VERSION ""

NS_ :

BS_:

BU_: BCM BMS_12V CMS_D CMS_P DSMU ECDO METER MID PBD PSB_D PSB_P PSCU RSCU2R RSCU3R SCCM SRVM VSP

BO_ 32 ACU_A102: 8 BCM
  SG_ AirbagCrashOrder_v3 : 5|6@0+ (1,0) [0|0] "" BMS_12V,DSMU,PSCU,SCCM
  SG_ PreRolloverDetection : 16|1@0+ (1,0) [0|0] "" PSB_D,PSB_P
  SG_ RolloverDetection : 57|1@0+ (1,0) [0|0] "" PSB_D,PSB_P

BO_ 114 EBA_A101: 7 BCM
  SG_ BrakePedalPosition : 23|12@0+ (0.03125,0) [0|100] "%" PSB_D,PSB_P

BO_ 115 ECM_A109: 6 BCM
  SG_ EngineRPMDisplay : 31|16@0+ (0.125,0) [0|8191.75] "rpm" METER

BO_ 116 ECM_A110: 8 BCM
  SG_ StopAutoPhase : 47|3@0+ (1,0) [0|0] "" SCCM

BO_ 117 ECM_A112: 8 BCM
  SG_ CRC_ECM_A112 : 7|8@0+ (1,0) [0|255] "" METER
  SG_ Clock_ECM_A112 : 15|4@0+ (1,0) [0|15] "" METER
  SG_ PowerTrainStatus : 25|2@0+ (1,0) [0|0] "" METER,VSP
  SG_ EngineStopRequestOrigin : 28|3@0+ (1,0) [0|0] "" METER
  SG_ EngineRPM : 39|16@0+ (0.125,0) [0|8191.75] "rpm" VSP

BO_ 159 ADAS_A4: 5 BCM
  SG_ AEB_BrakeWheelTorqueOrder2 : 11|3@0+ (1,0) [0|0] "" PSB_D,PSB_P

BO_ 168 STRG_A1: 7 BCM
  SG_ SteeringWheelAngleRaw : 22|15@0+ (0.1,-1080) [-1080|1080] "°" METER,PSB_D,PSB_P
  SG_ SwaSensorInternalStatus : 39|3@0+ (1,0) [0|0] "" DSMU,METER,PSB_D,PSB_P
  SG_ SteeringWheelRotationSpeed : 47|16@0+ (0.1,-3276.7) [-3276.7|3276.7] "°/s" DSMU,PSB_D,PSB_P

BO_ 171 VDC_A6: 8 BCM
  SG_ YawRateCorrected : 10|11@0+ (0.1,-100) [-100|100] "°/s" DSMU
  SG_ BrakingPressure : 31|8@0+ (0.5,0) [0|126] "bar" PSB_D,PSB_P
  SG_ SteerRackPinionAngleCorrect : 39|15@0+ (0.1,-1080) [-1080|1080] "°" METER,PSB_D,PSB_P

BO_ 180 VDC_A5: 8 BCM
  SG_ LongitudinalAccelCorrected : 23|12@0+ (0.001,-2) [-2|2] "G" METER
  SG_ TransversalAccelCorrected : 47|12@0+ (0.001,-2) [-2|2] "G" METER

BO_ 303 ATCU_A108: 7 BCM
  SG_ GearLeverPosition_v2 : 20|4@0+ (1,0) [0|0] "" DSMU,PBD,RSCU2R,SCCM,VSP

BO_ 514 VDC_A4: 8 BCM
  SG_ ABSinRegulation : 0|1@0+ (1,0) [0|0] "" PSB_D,PSB_P
  SG_ ESCMalfunction : 33|1@0+ (1,0) [0|0] "" METER
  SG_ ABSMalfunction : 47|1@0+ (1,0) [0|0] "" METER

BO_ 534 EPS_A101: 4 BCM
  SG_ CRC_EPS_A101 : 7|8@0+ (1,0) [0|255] "" METER
  SG_ Clock_EPS_A101 : 15|4@0+ (1,0) [0|15] "" METER
  SG_ EPSWarning : 19|2@0+ (1,0) [0|0] "" METER

BO_ 549 VDC_A115: 3 BCM
  SG_ StopLampFlashingRequest : 21|1@0+ (1,0) [0|0] "" DSMU

BO_ 559 FrCamADAS_R109: 7 BCM
  SG_ ADAS_SwitchTransitionDisplay : 42|3@0+ (1,0) [0|0] "" METER

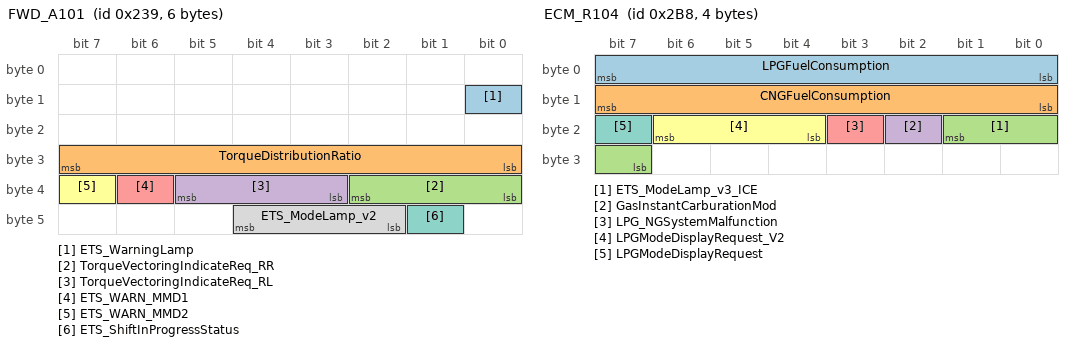
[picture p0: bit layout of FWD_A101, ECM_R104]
BO_ 569 FWD_A101: 6 BCM
  SG_ ETS_WarningLamp : 8|1@0+ (1,0) [0|0] "" METER
  SG_ TorqueDistributionRatio : 31|8@0+ (0.5,0) [0|100] "%" METER
  SG_ TorqueVectoringIndicateReq_RR : 34|3@0+ (1,0) [0|0] "" METER
  SG_ TorqueVectoringIndicateReq_RL : 37|3@0+ (1,0) [0|0] "" METER
  SG_ ETS_WARN_MMD1 : 38|1@0+ (1,0) [0|0] "" METER
  SG_ ETS_WARN_MMD2 : 39|1@0+ (1,0) [0|0] "" METER
  SG_ ETS_ShiftInProgressStatus : 41|1@0+ (1,0) [0|0] "" METER
  SG_ ETS_ModeLamp_v2 : 44|3@0+ (1,0) [0|0] "" METER

BO_ 578 FrCamADAS_R113: 2 BCM
  SG_ V2XDistanceToEvent : 7|11@0+ (1,0) [0|1500] "m" METER

BO_ 604 EPKB_A1: 4 BCM
  SG_ ParkingBrakeBindingStatus : 9|2@0+ (1,0) [0|0] "" METER

BO_ 650 VDC_A9: 8 BCM
  SG_ VehicleSpeed : 39|16@0+ (0.01,0) [0|655.34] "km/h" DSMU,METER,MID,PBD,PSB_D,PSB_P,PSCU,RSCU2R,RSCU3R,SCCM,VSP
  SG_ VehicleSpeedClock : 51|4@0+ (1,0) [0|15] "" DSMU,METER,PBD
  SG_ VDC_StandStillSupposed : 53|2@0+ (1,0) [0|0] "" METER
  SG_ VehicleSpeedCRC : 63|8@0+ (1,0) [0|255] "" DSMU,METER,PBD

BO_ 696 ECM_R104: 4 BCM
  SG_ LPGFuelConsumption : 7|8@0+ (0.000020,0) [0|0.00508] "L" METER
  SG_ CNGFuelConsumption : 15|8@0+ (0.000010,0) [0|0.00254] "kg" METER
  SG_ ETS_ModeLamp_v3_ICE : 17|3@0+ (1,0) [0|0] "" METER
  SG_ GasInstantCarburationMod : 18|1@0+ (1,0) [0|0] "" METER
  SG_ LPG_NGSystemMalfunction : 19|1@0+ (1,0) [0|0] "" METER
  SG_ LPGModeDisplayRequest_V2 : 22|3@0+ (1,0) [0|0] "" METER
  SG_ LPGModeDisplayRequest : 23|1@0+ (1,0) [0|0] "" METER

BO_ 699 VDC_R102: 5 BCM
  SG_ VaccumPumpDurabilityLimitAlert : 18|2@0+ (1,0) [0|0] "" METER

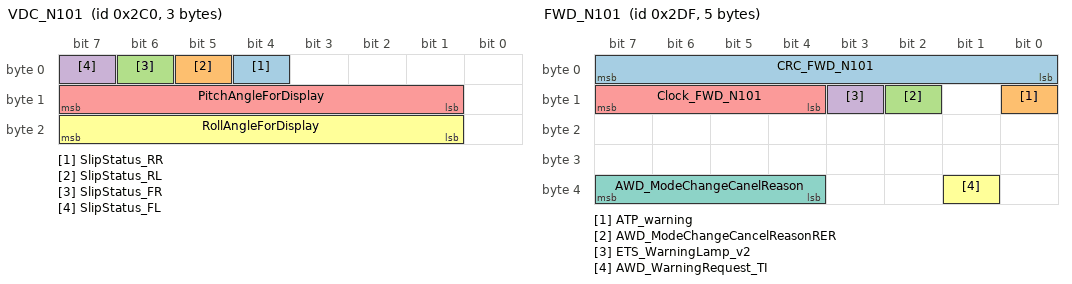
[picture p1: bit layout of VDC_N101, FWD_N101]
BO_ 704 VDC_N101: 3 BCM
  SG_ SlipStatus_RR : 4|1@0+ (1,0) [0|0] "" METER
  SG_ SlipStatus_RL : 5|1@0+ (1,0) [0|0] "" METER
  SG_ SlipStatus_FR : 6|1@0+ (1,0) [0|0] "" METER
  SG_ SlipStatus_FL : 7|1@0+ (1,0) [0|0] "" METER
  SG_ PitchAngleForDisplay : 15|7@0+ (1,-60) [-60|60] "°" METER
  SG_ RollAngleForDisplay : 23|7@0+ (1,-60) [-60|60] "°" METER

BO_ 735 FWD_N101: 5 BCM
  SG_ CRC_FWD_N101 : 7|8@0+ (1,0) [0|255] "" METER
  SG_ ATP_warning : 8|1@0+ (1,0) [0|0] "" METER
  SG_ AWD_ModeChangeCancelReasonRER : 10|1@0+ (1,0) [0|0] "" METER
  SG_ ETS_WarningLamp_v2 : 11|1@0+ (1,0) [0|0] "" METER
  SG_ Clock_FWD_N101 : 15|4@0+ (1,0) [0|15] "" METER
  SG_ AWD_WarningRequest_TI : 33|1@0+ (1,0) [0|0] "" METER
  SG_ AWD_ModeChangeCanelReason : 39|4@0+ (1,0) [0|0] "" METER

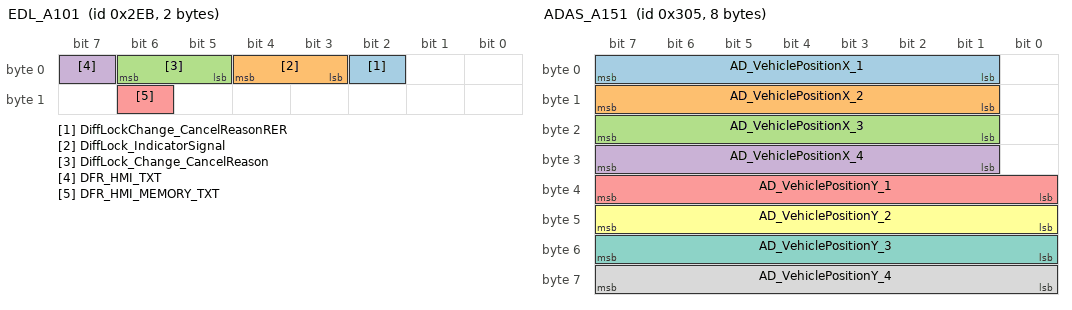
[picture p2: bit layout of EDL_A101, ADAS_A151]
BO_ 747 EDL_A101: 2 BCM
  SG_ DiffLockChange_CancelReasonRER : 2|1@0+ (1,0) [0|0] "" METER
  SG_ DiffLock_IndicatorSignal : 4|2@0+ (1,0) [0|0] "" METER
  SG_ DiffLock_Change_CancelReason : 6|2@0+ (1,0) [0|0] "" METER
  SG_ DFR_HMI_TXT : 7|1@0+ (1,0) [0|0] "" METER
  SG_ DFR_HMI_MEMORY_TXT : 14|1@0+ (1,0) [0|0] "" METER

BO_ 772 ADAS_A148: 4 BCM
  SG_ CRC_ADAS_A148 : 7|8@0+ (1,0) [0|255] "" METER
  SG_ Clock_ADAS_A148 : 15|4@0+ (1,0) [0|15] "" METER
  SG_ AD_OwnVehicle_ALCPosition : 23|7@0+ (1,0) [0|127] "" METER

BO_ 773 ADAS_A151: 8 BCM
  SG_ AD_VehiclePositionX_1 : 7|7@0+ (1,0) [0|127] "" METER
  SG_ AD_VehiclePositionX_2 : 15|7@0+ (1,0) [0|127] "" METER
  SG_ AD_VehiclePositionX_3 : 23|7@0+ (1,0) [0|127] "" METER
  SG_ AD_VehiclePositionX_4 : 31|7@0+ (1,0) [0|127] "" METER
  SG_ AD_VehiclePositionY_1 : 39|8@0+ (1,0) [0|255] "" METER
  SG_ AD_VehiclePositionY_2 : 47|8@0+ (1,0) [0|255] "" METER
  SG_ AD_VehiclePositionY_3 : 55|8@0+ (1,0) [0|255] "" METER
  SG_ AD_VehiclePositionY_4 : 63|8@0+ (1,0) [0|255] "" METER

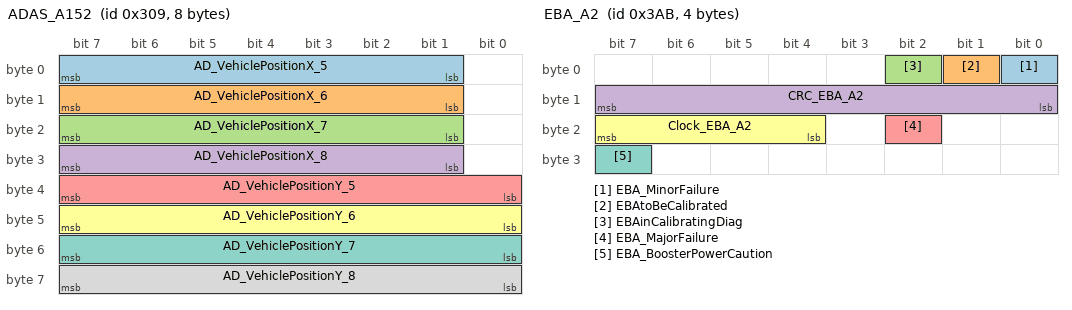
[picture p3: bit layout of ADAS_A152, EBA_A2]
BO_ 777 ADAS_A152: 8 BCM
  SG_ AD_VehiclePositionX_5 : 7|7@0+ (1,0) [0|127] "" METER
  SG_ AD_VehiclePositionX_6 : 15|7@0+ (1,0) [0|127] "" METER
  SG_ AD_VehiclePositionX_7 : 23|7@0+ (1,0) [0|127] "" METER
  SG_ AD_VehiclePositionX_8 : 31|7@0+ (1,0) [0|127] "" METER
  SG_ AD_VehiclePositionY_5 : 39|8@0+ (1,0) [0|255] "" METER
  SG_ AD_VehiclePositionY_6 : 47|8@0+ (1,0) [0|255] "" METER
  SG_ AD_VehiclePositionY_7 : 55|8@0+ (1,0) [0|255] "" METER
  SG_ AD_VehiclePositionY_8 : 63|8@0+ (1,0) [0|255] "" METER

BO_ 791 HVAC_A1: 8 BCM
  SG_ ISS_EcoActivationState : 43|2@0+ (1,0) [0|0] "" METER
  SG_ AirCondEcoActivationState : 45|2@0+ (1,0) [0|0] "" METER
  SG_ ClimECOModeStatusDisplay : 52|2@0+ (1,0) [0|0] "" METER

BO_ 879 METER_A4: 4 METER
  SG_ MemorizedDistanceTotalizer : 7|28@0+ (0.01,0) [0|2600000] "km" BCM

BO_ 893 EPS_A103: 3 BCM
  SG_ LDW_VibrationIntensityState : 2|2@0+ (1,0) [0|0] "" METER

BO_ 896 TCO1: 3 BCM
  SG_ DTCO_Driver1TimeRelatedStates : 11|4@0+ (1,0) [0|0] "" METER
  SG_ DTCO_OverSpeed : 15|2@0+ (1,0) [0|0] "" METER
  SG_ DTCO_Driver2TimeRelatedStates : 19|4@0+ (1,0) [0|0] "" METER

BO_ 930 ADAS_A123: 6 BCM
  SG_ DMC_UnresponsiveAlertStatus : 37|3@0+ (1,0) [0|0] "" METER

BO_ 934 AVM_A120: 3 BCM
  SG_ CRC_AVM_A120 : 7|8@0+ (1,0) [0|255] "" METER
  SG_ APA_StatusDisplay2 : 11|2@0+ (1,0) [0|0] "" METER
  SG_ Clock_AVM_A120 : 15|4@0+ (1,0) [0|15] "" METER

BO_ 939 EBA_A2: 4 BCM
  SG_ EBA_MinorFailure : 0|1@0+ (1,0) [0|0] "" METER
  SG_ EBAtoBeCalibrated : 1|1@0+ (1,0) [0|0] "" METER
  SG_ EBAinCalibratingDiag : 2|1@0+ (1,0) [0|0] "" METER
  SG_ CRC_EBA_A2 : 15|8@0+ (1,0) [0|255] "" METER
  SG_ EBA_MajorFailure : 18|1@0+ (1,0) [0|0] "" METER
  SG_ Clock_EBA_A2 : 23|4@0+ (1,0) [0|15] "" METER
  SG_ EBA_BoosterPowerCaution : 31|1@0+ (1,0) [0|0] "" METER

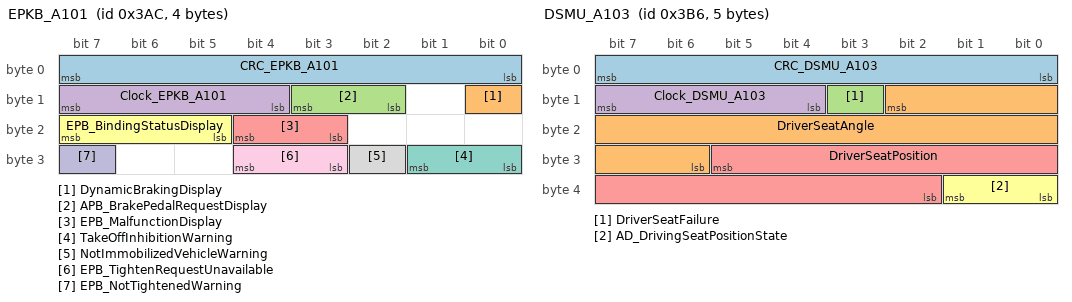
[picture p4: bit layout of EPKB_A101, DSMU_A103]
BO_ 940 EPKB_A101: 4 BCM
  SG_ CRC_EPKB_A101 : 7|8@0+ (1,0) [0|255] "" METER
  SG_ DynamicBrakingDisplay : 8|1@0+ (1,0) [0|0] "" METER
  SG_ APB_BrakePedalRequestDisplay : 11|2@0+ (1,0) [0|0] "" METER
  SG_ Clock_EPKB_A101 : 15|4@0+ (1,0) [0|15] "" METER
  SG_ EPB_MalfunctionDisplay : 20|2@0+ (1,0) [0|0] "" METER
  SG_ EPB_BindingStatusDisplay : 23|3@0+ (1,0) [0|0] "" METER
  SG_ TakeOffInhibitionWarning : 25|2@0+ (1,0) [0|0] "" METER
  SG_ NotImmobilizedVehicleWarning : 26|1@0+ (1,0) [0|0] "" METER
  SG_ EPB_TightenRequestUnavailable : 28|2@0+ (1,0) [0|0] "" METER
  SG_ EPB_NotTightenedWarning : 31|1@0+ (1,0) [0|0] "" METER

BO_ 941 BMS12V_A102: 2 BMS_12V
  SG_ CRC_BMS12V_A102 : 7|8@0+ (1,0) [0|255] "" BCM
  SG_ BMS12V_SafetyAlert : 11|2@0+ (1,0) [0|0] "" BCM,METER
  SG_ Clock_BMS12V_A102 : 15|4@0+ (1,0) [0|15] "" BCM

BO_ 943 FWD_M101: 3 BCM
  SG_ ETS_ModeLamp_v3 : 20|3@0+ (1,0) [0|0] "" METER

BO_ 950 DSMU_A103: 5 DSMU
  SG_ CRC_DSMU_A103 : 7|8@0+ (1,0) [0|255] "" BCM
  SG_ DriverSeatAngle : 10|13@0+ (1,-2244) [-2244|2244] "pulse" BCM
  SG_ DriverSeatFailure : 11|1@0+ (1,0) [0|0] "" BCM
  SG_ Clock_DSMU_A103 : 15|4@0+ (1,0) [0|15] "" BCM
  SG_ DriverSeatPosition : 29|12@0+ (1,-1260) [-1260|1260] "pulse" BCM
  SG_ AD_DrivingSeatPositionState : 33|2@0+ (1,0) [0|0] "" BCM

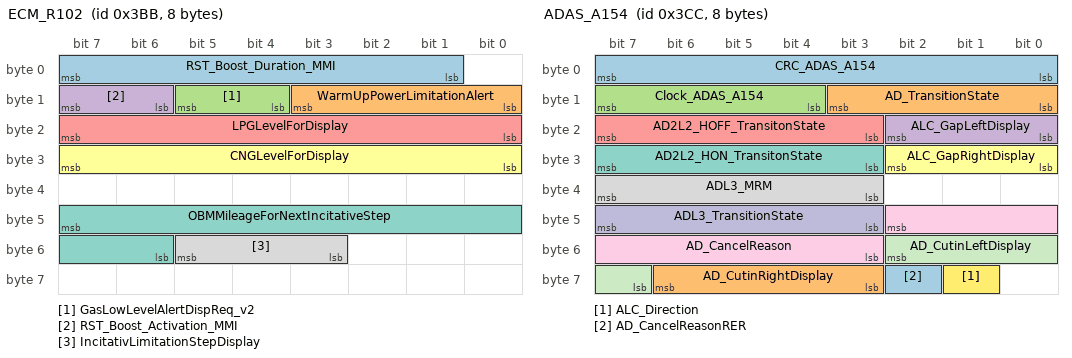
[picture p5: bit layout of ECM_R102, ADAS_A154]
BO_ 955 ECM_R102: 8 BCM
  SG_ RST_Boost_Duration_MMI : 7|7@0+ (1,0) [0|100] "%" METER
  SG_ WarmUpPowerLimitationAlert : 11|4@0+ (1,0) [0|0] "" METER
  SG_ GasLowLevelAlertDispReq_v2 : 13|2@0+ (1,0) [0|0] "" METER
  SG_ RST_Boost_Activation_MMI : 15|2@0+ (1,0) [0|0] "" METER
  SG_ LPGLevelForDisplay : 23|8@0+ (0.25,0) [0|63.5] "L" METER
  SG_ CNGLevelForDisplay : 31|8@0+ (0.2,0) [0|50.8] "kg" METER
  SG_ OBMMileageForNextIncitativeStep : 47|10@0+ (1,0) [0|1000] "Km" METER
  SG_ IncitativLimitationStepDisplay : 53|3@0+ (1,0) [0|0] "" METER

BO_ 959 HEVC_N101: 8 BCM
  SG_ IntelD_SettingStatus : 56|1@0+ (1,0) [0|0] "" METER
  SG_ IntelD_FailureDisplay : 58|2@0+ (1,0) [0|0] "" METER

BO_ 961 IVI_A112: 8 BCM
  SG_ DistanceBeforeNextAction : 7|40@0+ (1,0) [0|0] "" METER
  SG_ UnitDistanceBeforeNextAction : 47|4@0+ (1,0) [0|0] "" METER

BO_ 962 SONAR_A118: 4 BCM
  SG_ CRC_SONAR_A118 : 7|8@0+ (1,0) [0|255] "" METER
  SG_ APA_StatusDisplay : 11|2@0+ (1,0) [0|0] "" METER
  SG_ Clock_SONAR_A118 : 15|4@0+ (1,0) [0|15] "" METER

BO_ 967 IVI_A5: 8 BCM
  SG_ IVI_ParkAssistVolumeState : 63|3@0+ (1,0) [0|0] "" METER

BO_ 969 HEVC_M101: 1 BCM
  SG_ TorqueDistributionRatioDisplay : 7|8@0+ (0.5,0) [0|100] "%" METER

BO_ 970 BLM_A101: 1 BCM
  SG_ VirtualKeyState : 4|1@0+ (1,0) [0|0] "" METER

BO_ 971 ADAS_A150: 6 BCM
  SG_ AD_OwnVehicleEffect : 1|2@0+ (1,0) [0|0] "" METER
  SG_ AD_RightsideLane : 4|3@0+ (1,0) [0|0] "" METER
  SG_ AD_LeftsideLane : 7|3@0+ (1,0) [0|0] "" METER
  SG_ AD_VehicleEffect4 : 9|2@0+ (1,0) [0|0] "" METER
  SG_ AD_VehicleEffect3 : 11|2@0+ (1,0) [0|0] "" METER
  SG_ AD_VehicleEffect2 : 13|2@0+ (1,0) [0|0] "" METER
  SG_ AD_VehicleEffect1 : 15|2@0+ (1,0) [0|0] "" METER
  SG_ AD_VehicleEffect5 : 17|2@0+ (1,0) [0|0] "" METER
  SG_ AD_VehicleStatus2 : 20|3@0+ (1,0) [0|0] "" METER
  SG_ AD_VehicleStatus1 : 23|3@0+ (1,0) [0|0] "" METER
  SG_ AD_VehicleEffect6 : 25|2@0+ (1,0) [0|0] "" METER
  SG_ AD_VehicleStatus4 : 28|3@0+ (1,0) [0|0] "" METER
  SG_ AD_VehicleStatus3 : 31|3@0+ (1,0) [0|0] "" METER
  SG_ AD_VehicleEffect7 : 33|2@0+ (1,0) [0|0] "" METER
  SG_ AD_VehicleStatus6 : 36|3@0+ (1,0) [0|0] "" METER
  SG_ AD_VehicleStatus5 : 39|3@0+ (1,0) [0|0] "" METER
  SG_ AD_VehicleEffect8 : 41|2@0+ (1,0) [0|0] "" METER
  SG_ AD_VehicleStatus8 : 44|3@0+ (1,0) [0|0] "" METER
  SG_ AD_VehicleStatus7 : 47|3@0+ (1,0) [0|0] "" METER

BO_ 972 ADAS_A154: 8 BCM
  SG_ CRC_ADAS_A154 : 7|8@0+ (1,0) [0|255] "" METER
  SG_ AD_TransitionState : 11|4@0+ (1,0) [0|0] "" METER
  SG_ Clock_ADAS_A154 : 15|4@0+ (1,0) [0|15] "" METER
  SG_ ALC_GapLeftDisplay : 18|3@0+ (1,0) [0|0] "" METER
  SG_ AD2L2_HOFF_TransitonState : 23|5@0+ (1,0) [0|0] "" METER
  SG_ ALC_GapRightDisplay : 26|3@0+ (1,0) [0|0] "" METER
  SG_ AD2L2_HON_TransitonState : 31|5@0+ (1,0) [0|0] "" METER
  SG_ ADL3_MRM : 39|5@0+ (1,0) [0|0] "" METER
  SG_ AD_CancelReason : 42|8@0+ (1,0) [0|255] "CancelReason" METER
  SG_ ADL3_TransitionState : 47|5@0+ (1,0) [0|0] "" METER
  SG_ AD_CutinLeftDisplay : 50|4@0+ (1,0) [0|0] "" METER
  SG_ ALC_Direction : 57|1@0+ (1,0) [0|0] "" METER
  SG_ AD_CancelReasonRER : 58|1@0+ (1,0) [0|0] "" METER
  SG_ AD_CutinRightDisplay : 62|4@0+ (1,0) [0|0] "" METER

BO_ 974 ADAS_A147: 7 BCM
  SG_ CRC_ADAS_A147 : 7|8@0+ (1,0) [0|255] "" METER
  SG_ Clock_ADAS_A147 : 15|4@0+ (1,0) [0|15] "" METER
  SG_ ADADAS_ReflectiveFocus_Status : 23|36@0+ (1,0) [0|68719476734] "" METER

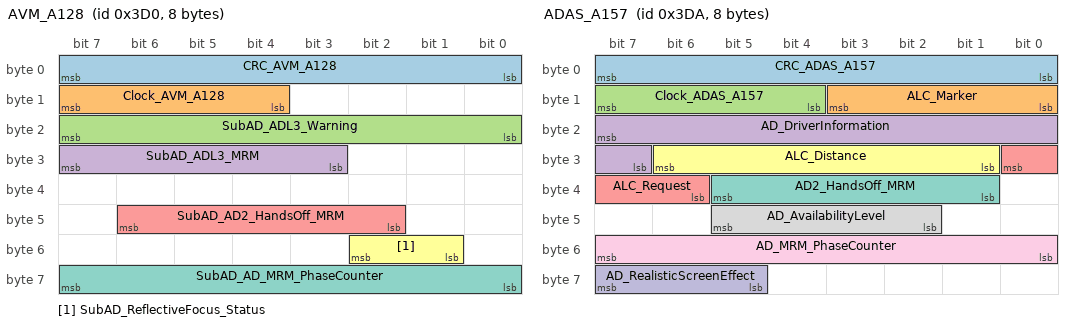
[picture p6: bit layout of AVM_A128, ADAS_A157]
BO_ 976 AVM_A128: 8 BCM
  SG_ CRC_AVM_A128 : 7|8@0+ (1,0) [0|255] "" METER
  SG_ Clock_AVM_A128 : 15|4@0+ (1,0) [0|15] "" METER
  SG_ SubAD_ADL3_Warning : 23|8@0+ (1,0) [0|255] "Warning" METER
  SG_ SubAD_ADL3_MRM : 31|5@0+ (1,0) [0|0] "" METER
  SG_ SubAD_AD2_HandsOff_MRM : 46|5@0+ (1,0) [0|0] "" METER
  SG_ SubAD_ReflectiveFocus_Status : 50|2@0+ (1,0) [0|0] "" METER
  SG_ SubAD_AD_MRM_PhaseCounter : 63|8@0+ (0.2,-0.2) [0|50.6] "s" METER

BO_ 977 CDM_A127: 3 BCM
  SG_ CRC_CDM_A127 : 7|8@0+ (1,0) [0|255] "" BMS_12V
  SG_ Clock_CDM_A127 : 15|4@0+ (1,0) [0|15] "" BMS_12V
  SG_ LiB_RLY_OFF_Inhibition : 23|1@0+ (1,0) [0|0] "" BMS_12V

BO_ 986 ADAS_A157: 8 BCM
  SG_ CRC_ADAS_A157 : 7|8@0+ (1,0) [0|255] "" METER
  SG_ ALC_Marker : 11|4@0+ (1,0) [0|0] "" METER
  SG_ Clock_ADAS_A157 : 15|4@0+ (1,0) [0|15] "" METER
  SG_ AD_DriverInformation : 23|9@0+ (1,0) [0|511] "Instruction" METER
  SG_ ALC_Request : 24|3@0+ (1,0) [0|0] "" METER
  SG_ ALC_Distance : 30|6@0+ (100,-100) [0|6000] "m" METER
  SG_ AD2_HandsOff_MRM : 37|5@0+ (1,0) [0|0] "" METER
  SG_ AD_AvailabilityLevel : 45|4@0+ (1,0) [0|0] "" METER
  SG_ AD_MRM_PhaseCounter : 55|8@0+ (0.2,-0.2) [0|50.6] "s" METER
  SG_ AD_RealisticScreenEffect : 63|3@0+ (1,0) [0|0] "" METER

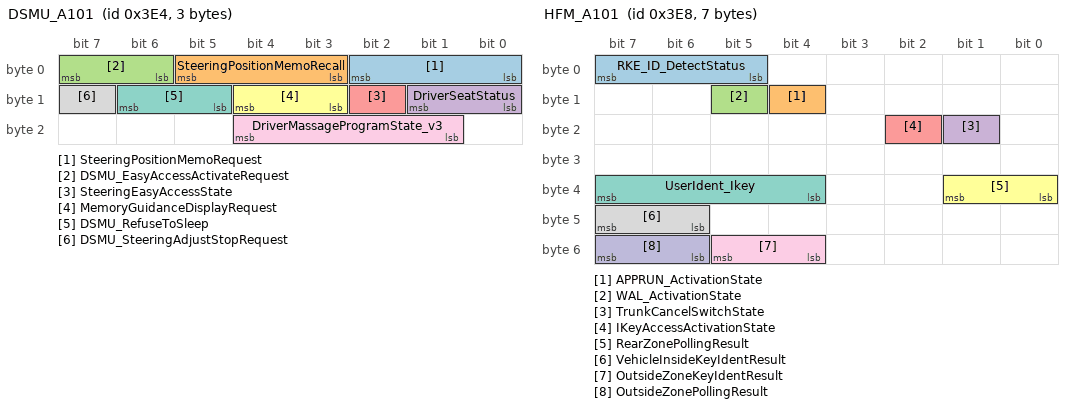
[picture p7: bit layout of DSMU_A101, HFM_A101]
BO_ 996 DSMU_A101: 3 DSMU
  SG_ SteeringPositionMemoRequest : 2|3@0+ (1,0) [0|0] "" SCCM
  SG_ SteeringPositionMemoRecall : 5|3@0+ (1,0) [0|0] "" SCCM
  SG_ DSMU_EasyAccessActivateRequest : 7|2@0+ (1,0) [0|0] "" SCCM
  SG_ DriverSeatStatus : 9|2@0+ (1,0) [0|0] "" BCM,SCCM
  SG_ SteeringEasyAccessState : 10|1@0+ (1,0) [0|0] "" METER
  SG_ MemoryGuidanceDisplayRequest : 12|2@0+ (1,0) [0|0] "" METER
  SG_ DSMU_RefuseToSleep : 14|2@0+ (1,0) [0|0] "" BCM
  SG_ DSMU_SteeringAdjustStopRequest : 15|1@0+ (1,0) [0|0] "" SCCM
  SG_ DriverMassageProgramState_v3 : 20|4@0+ (1,0) [0|0] "" BCM

BO_ 997 SCCM_A101: 1 SCCM
  SG_ SCCM_Status : 2|3@0+ (1,0) [0|0] "" DSMU
  SG_ SCCM_RefuseToSleep : 4|2@0+ (1,0) [0|0] "" BCM
  SG_ STR_AdjustStatus : 6|1@0+ (1,0) [0|0] "" DSMU

BO_ 999 BCM_A105: 4 BCM
  SG_ ADBCautionDisplay : 0|1@0+ (1,0) [0|0] "" METER
  SG_ V2_WakeUpType : 3|3@0+ (1,0) [0|0] "" BMS_12V
  SG_ BCM_LockAndCloseAuthentState : 5|2@0+ (1,0) [0|0] "" PBD
  SG_ V2_WakeUpSleepCommand : 7|2@0+ (1,0) [0|0] "" BMS_12V,DSMU,METER,MID,PBD,PSB_D,PSB_P,PSCU,RSCU2R,RSCU3R,SCCM
  SG_ BCM_SteeringCommandK : 8|1@0+ (1,0) [0|0] "" METER
  SG_ BCM_SteeringCommandJ : 9|1@0+ (1,0) [0|0] "" METER
  SG_ BCM_SteeringCommandI : 10|1@0+ (1,0) [0|0] "" METER
  SG_ BCM_SteeringCommandH : 11|1@0+ (1,0) [0|0] "" METER
  SG_ AHLCautionDisplay : 15|1@0+ (1,0) [0|0] "" METER
  SG_ BCM_SteeringCommandO : 16|1@0+ (1,0) [0|0] "" METER
  SG_ BCM_SteeringCommandN : 17|1@0+ (1,0) [0|0] "" METER
  SG_ BCM_SteeringCommandM : 18|1@0+ (1,0) [0|0] "" METER
  SG_ BCM_SteeringCommandL : 19|1@0+ (1,0) [0|0] "" METER
  SG_ BCM_SteeringPhoneEndCommand : 25|1@0+ (1,0) [0|0] "" METER
  SG_ LightSwitchOperationFdbk_display : 29|4@0+ (1,0) [0|0] "" METER
  SG_ BCM_SteeringCommandG : 30|1@0+ (1,0) [0|0] "" METER
  SG_ BCM_SteeringCommandP : 31|1@0+ (1,0) [0|0] "" METER

BO_ 1000 HFM_A101: 7 BCM
  SG_ RKE_ID_DetectStatus : 7|3@0+ (1,0) [0|0] "" DSMU
  SG_ APPRUN_ActivationState : 12|1@0+ (1,0) [0|0] "" METER
  SG_ WAL_ActivationState : 13|1@0+ (1,0) [0|0] "" METER
  SG_ TrunkCancelSwitchState : 17|1@0+ (1,0) [0|0] "" PBD
  SG_ IKeyAccessActivationState : 18|1@0+ (1,0) [0|0] "" METER
  SG_ RearZonePollingResult : 33|2@0+ (1,0) [0|0] "" PBD
  SG_ UserIdent_Ikey : 39|4@0+ (1,0) [0|0] "" PBD
  SG_ VehicleInsideKeyIdentResult : 47|2@0+ (1,0) [0|0] "" PBD
  SG_ OutsideZoneKeyIdentResult : 53|2@0+ (1,0) [0|0] "" PBD
  SG_ OutsideZonePollingResult : 55|2@0+ (1,0) [0|0] "" PBD

BO_ 1001 PSCU_A102: 1 PSCU
  SG_ PassengerMassageProgramState_v3 : 3|4@0+ (1,0) [0|0] "" BCM

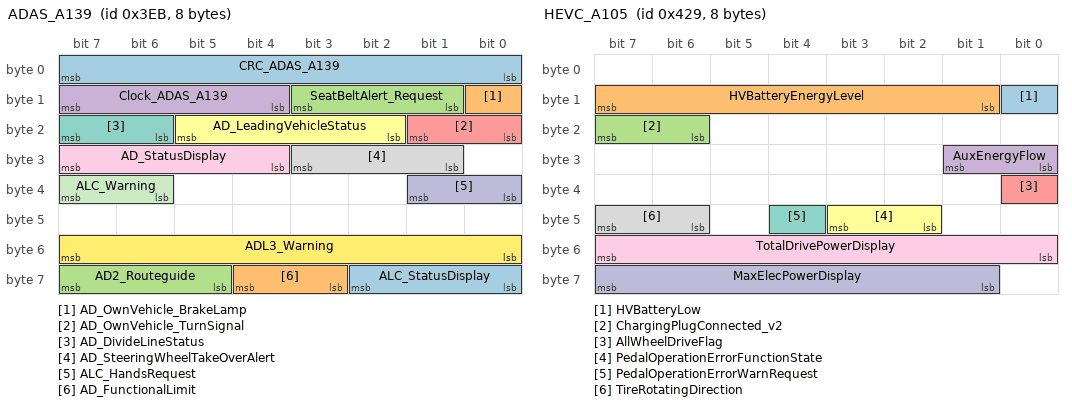
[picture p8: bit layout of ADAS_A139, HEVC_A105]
BO_ 1003 ADAS_A139: 8 BCM
  SG_ CRC_ADAS_A139 : 7|8@0+ (1,0) [0|255] "" METER,PSB_D
  SG_ AD_OwnVehicle_BrakeLamp : 8|1@0+ (1,0) [0|0] "" METER
  SG_ SeatBeltAlert_Request : 11|3@0+ (1,0) [0|0] "" PSB_D
  SG_ Clock_ADAS_A139 : 15|4@0+ (1,0) [0|15] "" METER,PSB_D
  SG_ AD_OwnVehicle_TurnSignal : 17|2@0+ (1,0) [0|0] "" METER
  SG_ AD_LeadingVehicleStatus : 21|4@0+ (1,0) [0|0] "" METER
  SG_ AD_DivideLineStatus : 23|2@0+ (1,0) [0|0] "" METER
  SG_ AD_SteeringWheelTakeOverAlert : 27|3@0+ (1,0) [0|0] "" METER
  SG_ AD_StatusDisplay : 31|4@0+ (1,0) [0|0] "" METER
  SG_ ALC_HandsRequest : 33|2@0+ (1,0) [0|0] "" METER
  SG_ ALC_Warning : 39|2@0+ (1,0) [0|0] "" METER
  SG_ ADL3_Warning : 55|8@0+ (1,0) [0|255] "Warning" METER
  SG_ ALC_StatusDisplay : 58|3@0+ (1,0) [0|0] "" METER
  SG_ AD_FunctionalLimit : 60|2@0+ (1,0) [0|0] "" METER
  SG_ AD2_Routeguide : 63|3@0+ (1,0) [0|0] "" METER

BO_ 1012 TCU_A101: 7 BCM
  SG_ ECALL_StateDisplay_V4 : 55|4@0+ (1,0) [0|0] "" METER

BO_ 1022 PSB_A101: 2 PSB_D
  SG_ CRC_PSB_A101 : 7|8@0+ (1,0) [0|255] "" BCM
  SG_ PSB_RefuseToSleep : 9|2@0+ (1,0) [0|0] "" BCM
  SG_ SeatBeltAlert_Status : 10|1@0+ (1,0) [0|0] "" BCM
  SG_ SeatBeltAlert_Failure : 11|1@0+ (1,0) [0|0] "" BCM
  SG_ Clock_PSB_A101 : 15|4@0+ (1,0) [0|15] "" BCM

BO_ 1028 VSP_A101: 1 VSP
  SG_ VSPSoundActivationState : 4|1@0+ (1,0) [0|0] "" BCM
  SG_ VSPsoundChoiceActivationState : 7|3@0+ (1,0) [0|0] "" BCM

BO_ 1045 IVI_A135: 8 BCM
  SG_ FaceID_temporary_Failure : 11|4@0+ (1,0) [0|0] "" METER
  SG_ FaceID_RegistrationState_IVI : 15|4@0+ (1,0) [0|0] "" METER
  SG_ FaceID_permanent_Failure : 20|2@0+ (1,0) [0|0] "" METER
  SG_ FaceID_RecognitionState_IVI : 23|3@0+ (1,0) [0|0] "" METER

BO_ 1047 AVM_A119: 3 BCM
  SG_ APA_Warning : 4|1@0+ (1,0) [0|0] "" METER

BO_ 1048 SONAR_A121: 1 BCM
  SG_ APA_Warning2 : 7|1@0+ (1,0) [0|0] "" METER

BO_ 1055 HEVC_R129: 8 BCM
  SG_ LowSOCTextRechargeAlertDisplay : 24|1@0+ (1,0) [0|0] "" METER
  SG_ RemainingTripForStartProhibit : 39|8@0+ (1,0) [0|255] "-" METER
  SG_ OBMMileageForNextIncitStep_V2 : 47|14@0+ (1,0) [0|10000] "Km" METER

BO_ 1058 FRCAMERA_A111: 5 BCM
  SG_ SpeedLimiterOSPDisplayRequest : 21|2@0+ (1,0) [0|0] "" METER
  SG_ TSR_ConfidenceLevel : 39|3@0+ (20,0) [0|100] "%" METER

BO_ 1064 HEVC_A104: 7 BCM
  SG_ MinElecPowerDisplay : 26|7@0+ (1,0) [0|100] "%" METER
  SG_ MaxElecPowerStatusDisplay : 33|2@0+ (1,0) [0|0] "" METER
  SG_ MinElecPowerStatusDisplay : 35|2@0+ (1,0) [0|0] "" METER

BO_ 1065 HEVC_A105: 8 BCM
  SG_ HVBatteryLow : 8|1@0+ (1,0) [0|0] "" METER
  SG_ HVBatteryEnergyLevel : 15|7@0+ (1,0) [0|100] "%" METER
  SG_ ChargingPlugConnected_v2 : 23|2@0+ (1,0) [0|0] "" METER
  SG_ AuxEnergyFlow : 25|2@0+ (1,0) [0|0] "" METER
  SG_ AllWheelDriveFlag : 32|1@0+ (1,0) [0|0] "" METER
  SG_ PedalOperationErrorFunctionState : 43|2@0+ (1,0) [0|0] "" METER
  SG_ PedalOperationErrorWarnRequest : 44|1@0+ (1,0) [0|0] "" METER
  SG_ TireRotatingDirection : 47|2@0+ (1,0) [0|0] "" METER
  SG_ TotalDrivePowerDisplay : 55|8@0+ (1,-100) [-100|120] "%" METER
  SG_ MaxElecPowerDisplay : 63|7@0+ (1,0) [0|100] "%" METER

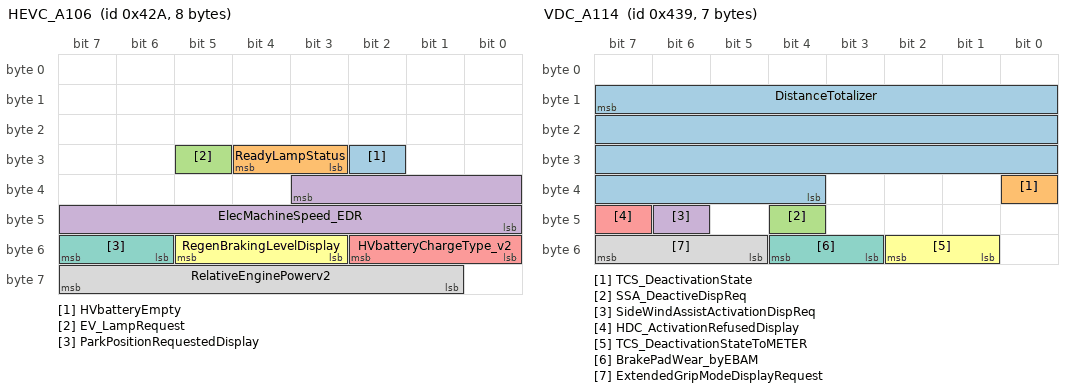
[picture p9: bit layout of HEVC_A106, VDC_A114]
BO_ 1066 HEVC_A106: 8 BCM
  SG_ HVbatteryEmpty : 26|1@0+ (1,0) [0|0] "" METER
  SG_ ReadyLampStatus : 28|2@0+ (1,0) [0|0] "" METER
  SG_ EV_LampRequest : 29|1@0+ (1,0) [0|0] "" METER
  SG_ ElecMachineSpeed_EDR : 35|12@0+ (10,-20000) [-20000|20000] "rpm" METER
  SG_ HVbatteryChargeType_v2 : 50|3@0+ (1,0) [0|0] "" METER
  SG_ RegenBrakingLevelDisplay : 53|3@0+ (1,0) [0|0] "" METER
  SG_ ParkPositionRequestedDisplay : 55|2@0+ (1,0) [0|0] "" METER
  SG_ RelativeEnginePowerv2 : 63|7@0+ (1,0) [0|100] "%" METER

BO_ 1067 HEVC_A107: 8 BCM
  SG_ RE_ElecMachineTemp_BLMS : 26|8@0+ (1,-40) [-40|210] "°C" METER
  SG_ RE_InverterTemp_BLMS : 34|8@0+ (1,-40) [-40|210] "°C" METER
  SG_ RE_ElecMachineSpeed_BLMS : 42|12@0+ (10,-20000) [-20000|20000] "rpm" METER
  SG_ HVbatteryTempForDisp : 62|7@0+ (1,-40) [-40|80] "°C" METER

BO_ 1068 HEVC_A108: 8 BCM
  SG_ HEV_ElecMotorFailureDisplay : 3|1@0+ (1,0) [0|0] "" METER
  SG_ HEV_ChargeFailureDisplay : 4|1@0+ (1,0) [0|0] "" METER
  SG_ HEV_MajorElecFailureDisplay : 5|1@0+ (1,0) [0|0] "" METER
  SG_ ChargingSoundRequest : 7|2@0+ (1,0) [0|0] "" VSP
  SG_ EngineMotorEnergyFlow_v2 : 10|3@0+ (1,0) [0|0] "" METER
  SG_ HVchargerStatus : 12|2@0+ (1,0) [0|0] "" DSMU,PSCU,RSCU2R,RSCU3R
  SG_ EngineWheelEnergyFlow_v2 : 18|3@0+ (1,0) [0|0] "" METER
  SG_ AuxChargePlugEnergyFlow : 20|2@0+ (1,0) [0|0] "" METER
  SG_ BatteryMotorEnergyFlow_v2 : 23|3@0+ (1,0) [0|0] "" METER
  SG_ HVBatInstantCurrentDisplay_v2 : 28|15@0+ (0.125,-1200) [-1200|1200] "A" METER
  SG_ BatteryRearMotorEnergyFlow : 31|3@0+ (1,0) [0|0] "" METER
  SG_ BatteryChargePlugEnergyFlow : 41|2@0+ (1,0) [0|0] "" METER
  SG_ ChargingStatusDisplay_v2 : 45|4@0+ (1,0) [0|0] "" METER
  SG_ ChargeRemainingTimeDisplay_v2 : 55|11@0+ (1,0) [0|2046] "min" METER
  SG_ HybridTractionChargeModeAvail : 56|1@0+ (1,0) [0|0] "" METER
  SG_ HybridTractionSaveModeAvail : 57|1@0+ (1,0) [0|0] "" METER
  SG_ HybridTractionModeCursorDisplay : 60|3@0+ (1,0) [0|0] "" METER

BO_ 1070 HEVC_R101: 7 BCM
  SG_ EcoNavStatusDisplay : 34|1@0+ (1,0) [0|0] "" METER
  SG_ ElecPowerDisplay : 55|8@0+ (1,-100) [-100|100] "%" METER

BO_ 1076 HFM_A104: 8 BCM
  SG_ CRC_HFM_A104 : 7|8@0+ (1,0) [0|255] "" METER
  SG_ BadgeBatteryLow : 8|1@0+ (1,0) [0|0] "" METER
  SG_ Clock_HFM_A104 : 15|4@0+ (1,0) [0|15] "" METER
  SG_ SteeringLockFailure : 47|2@0+ (1,0) [0|0] "" METER
  SG_ SwitchOffSESDisturbers : 50|1@0+ (1,0) [0|0] "" METER

BO_ 1081 VDC_A114: 7 BCM
  SG_ DistanceTotalizer : 15|28@0+ (0.01,0) [0|2600000] "km" BMS_12V,CMS_D,CMS_P,DSMU,METER,MID,PBD,PSB_D,PSB_P,PSCU,RSCU2R,RSCU3R,SCCM,VSP
  SG_ TCS_DeactivationState : 32|1@0+ (1,0) [0|0] "" METER
  SG_ SSA_DeactiveDispReq : 44|1@0+ (1,0) [0|0] "" METER
  SG_ SideWindAssistActivationDispReq : 46|1@0+ (1,0) [0|0] "" METER
  SG_ HDC_ActivationRefusedDisplay : 47|1@0+ (1,0) [0|0] "" METER
  SG_ TCS_DeactivationStateToMETER : 50|2@0+ (1,0) [0|0] "" METER
  SG_ BrakePadWear_byEBAM : 52|2@0+ (1,0) [0|0] "" METER
  SG_ ExtendedGripModeDisplayRequest : 55|3@0+ (1,0) [0|0] "" METER

BO_ 1082 HFM_A108: 7 BCM
  SG_ VPA_PBD_Request : 53|3@0+ (1,0) [0|0] "" PBD

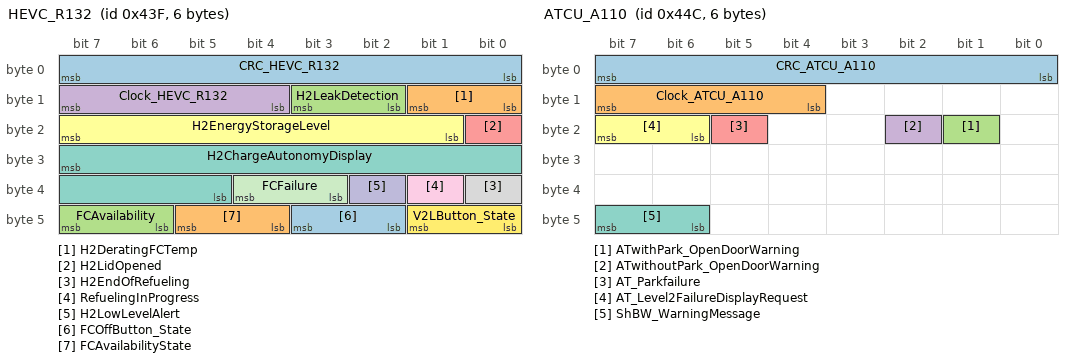
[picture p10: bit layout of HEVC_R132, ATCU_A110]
BO_ 1087 HEVC_R132: 6 BCM
  SG_ CRC_HEVC_R132 : 7|8@0+ (1,0) [0|255] "" METER
  SG_ H2DeratingFCTemp : 9|2@0+ (1,0) [0|0] "" METER
  SG_ H2LeakDetection : 11|2@0+ (1,0) [0|0] "" METER
  SG_ Clock_HEVC_R132 : 15|4@0+ (1,0) [0|15] "" METER
  SG_ H2LidOpened : 16|1@0+ (1,0) [0|0] "" METER
  SG_ H2EnergyStorageLevel : 23|7@0+ (1,0) [0|100] "%" METER
  SG_ H2ChargeAutonomyDisplay : 31|11@0+ (1,0) [0|2047] "KM" METER
  SG_ H2EndOfRefueling : 32|1@0+ (1,0) [0|0] "" METER
  SG_ RefuelingInProgress : 33|1@0+ (1,0) [0|0] "" METER
  SG_ H2LowLevelAlert : 34|1@0+ (1,0) [0|0] "" METER
  SG_ FCFailure : 36|2@0+ (1,0) [0|0] "" METER
  SG_ V2LButton_State : 41|2@0+ (1,0) [0|0] "" METER
  SG_ FCOffButton_State : 43|2@0+ (1,0) [0|0] "" METER
  SG_ FCAvailabilityState : 45|2@0+ (1,0) [0|0] "" METER
  SG_ FCAvailability : 47|2@0+ (1,0) [0|0] "" METER

BO_ 1099 ATCU_A109: 8 BCM
  SG_ AT_BrakeAvailability : 10|2@0+ (1,0) [0|0] "" METER
  SG_ RST_LaunchControlReadyMMI : 13|2@0+ (1,0) [0|0] "" METER
  SG_ AT_LoadAvailability : 17|2@0+ (1,0) [0|0] "" METER
  SG_ AT_DriverRequestWithoutBrake : 18|1@0+ (1,0) [0|0] "" METER
  SG_ AT_DriverRequest : 22|4@0+ (1,0) [0|0] "" METER
  SG_ AT_DriveAvailability_v2 : 23|1@0+ (1,0) [0|0] "" METER
  SG_ AT_PressBrakePedalRequest : 24|1@0+ (1,0) [0|0] "" METER
  SG_ AT_ParkAvailability : 26|2@0+ (1,0) [0|0] "" METER
  SG_ AT_NeutralAvailability : 28|2@0+ (1,0) [0|0] "" METER
  SG_ AT_ManualAvailability : 30|2@0+ (1,0) [0|0] "" METER
  SG_ AT_GearShiftRefused : 31|1@0+ (1,0) [0|0] "" METER
  SG_ ATCVT_CheckWarning : 32|1@0+ (1,0) [0|0] "" METER
  SG_ AT_TipDownAvailability : 34|2@0+ (1,0) [0|0] "" METER
  SG_ AT_ReverseAvailability : 39|2@0+ (1,0) [0|0] "" METER
  SG_ ATCVT_RangeIndicationExtended : 44|6@0+ (1,0) [0|0] "" METER
  SG_ ATCVT_HiTempWarning : 45|1@0+ (1,0) [0|0] "" METER
  SG_ AT_TipUpAvailability : 47|2@0+ (1,0) [0|0] "" METER
  SG_ AccelReqImpossible : 60|1@0+ (1,0) [0|0] "" METER
  SG_ NeutralHoldModeMessage : 63|3@0+ (1,0) [0|0] "" METER

BO_ 1100 ATCU_A110: 6 BCM
  SG_ CRC_ATCU_A110 : 7|8@0+ (1,0) [0|255] "" METER
  SG_ Clock_ATCU_A110 : 15|4@0+ (1,0) [0|15] "" METER
  SG_ ATwithPark_OpenDoorWarning : 17|1@0+ (1,0) [0|0] "" METER
  SG_ ATwithoutPark_OpenDoorWarning : 18|1@0+ (1,0) [0|0] "" METER
  SG_ AT_Parkfailure : 21|1@0+ (1,0) [0|0] "" METER
  SG_ AT_Level2FailureDisplayRequest : 23|2@0+ (1,0) [0|0] "" METER
  SG_ ShBW_WarningMessage : 47|2@0+ (1,0) [0|0] "" METER

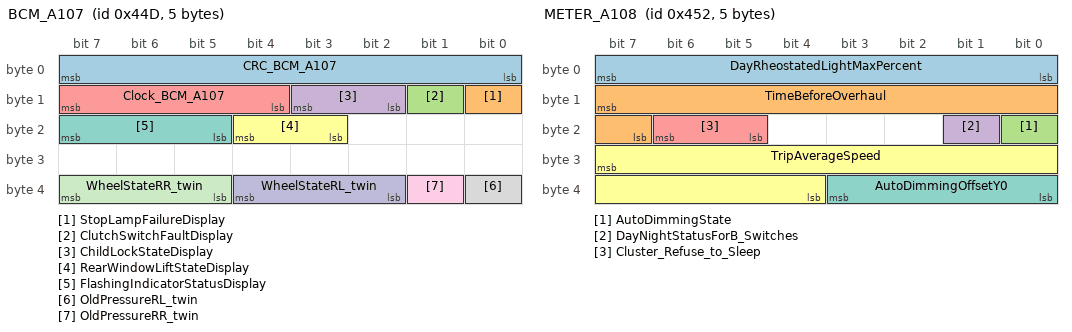
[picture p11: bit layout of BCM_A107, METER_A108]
BO_ 1101 BCM_A107: 5 BCM
  SG_ CRC_BCM_A107 : 7|8@0+ (1,0) [0|255] "" METER
  SG_ StopLampFailureDisplay : 8|1@0+ (1,0) [0|0] "" METER
  SG_ ClutchSwitchFaultDisplay : 9|1@0+ (1,0) [0|0] "" METER
  SG_ ChildLockStateDisplay : 11|2@0+ (1,0) [0|0] "" METER
  SG_ Clock_BCM_A107 : 15|4@0+ (1,0) [0|15] "" METER
  SG_ RearWindowLiftStateDisplay : 20|2@0+ (1,0) [0|0] "" METER
  SG_ FlashingIndicatorStatusDisplay : 23|3@0+ (1,0) [0|0] "" METER
  SG_ OldPressureRL_twin : 32|1@0+ (1,0) [0|0] "" METER
  SG_ OldPressureRR_twin : 33|1@0+ (1,0) [0|0] "" METER
  SG_ WheelStateRL_twin : 36|3@0+ (1,0) [0|0] "" METER
  SG_ WheelStateRR_twin : 39|3@0+ (1,0) [0|0] "" METER

BO_ 1102 BCM_A108: 6 BCM
  SG_ AutoLockActivationState : 1|2@0+ (1,0) [0|0] "" METER
  SG_ AutoLightSensitivityStatus : 3|2@0+ (1,0) [0|0] "" METER
  SG_ AutoFrontWiperActivationStatus : 5|2@0+ (1,0) [0|0] "" METER
  SG_ AHL_ActivationState : 7|2@0+ (1,0) [0|0] "" METER
  SG_ RearWiperStatus : 9|2@0+ (1,0) [0|0] "" METER
  SG_ MotorwayFlashersNumberStatus : 11|2@0+ (1,0) [0|0] "" METER
  SG_ AutoUnLockActivationState : 13|2@0+ (1,0) [0|0] "" METER
  SG_ AmbientLightingPatternState : 14|1@0+ (1,0) [0|0] "" METER
  SG_ AutoFMHactivationState : 15|1@0+ (1,0) [0|0] "" METER
  SG_ AutoInternalLightingState : 16|1@0+ (1,0) [0|0] "" METER
  SG_ AutoFMHdurationState : 19|3@0+ (1,0) [0|0] "" METER
  SG_ ADB_ActivationState : 20|1@0+ (1,0) [0|0] "" METER
  SG_ AutoReLockActivationState : 21|1@0+ (1,0) [0|0] "" METER
  SG_ FrontRearWiperDropStatus : 22|1@0+ (1,0) [0|0] "" METER
  SG_ WGSactivationState : 23|1@0+ (1,0) [0|0] "" METER
  SG_ LowBeamDisplay : 30|1@0+ (1,0) [0|0] "" METER
  SG_ HighBeamDisplay : 31|1@0+ (1,0) [0|0] "" METER
  SG_ AmbientLightingArea5Status : 35|1@0+ (1,0) [0|0] "" METER
  SG_ AmbientLightingArea4Status : 36|1@0+ (1,0) [0|0] "" METER
  SG_ SupportKeyJudgement : 47|2@0+ (1,0) [0|0] "" METER

BO_ 1103 BCM_A109: 8 BCM
  SG_ AHL_ActivationDisplay : 1|2@0+ (1,0) [0|0] "" METER
  SG_ FollowMeHomeDurationDisplay : 4|3@0+ (1,0) [0|0] "" METER
  SG_ KeylessInfoReemissionRequest : 5|1@0+ (1,0) [0|0] "" METER
  SG_ KeyReminderAlert : 7|2@0+ (1,0) [0|0] "" METER
  SG_ FrontRightDoorOpenWarning : 9|2@0+ (1,0) [0|0] "" METER
  SG_ FrontLeftDoorOpenWarning : 11|2@0+ (1,0) [0|0] "" METER
  SG_ PositionLightsDisplay : 13|1@0+ (1,0) [0|0] "" METER
  SG_ BootOpenWarning : 15|2@0+ (1,0) [0|0] "" METER
  SG_ DoorLockRefuseToLockAlertDisplay : 16|1@0+ (1,0) [0|0] "" METER
  SG_ IGN_SaverWarningBeforeIGNOFF : 18|1@0+ (1,0) [0|0] "" METER
  SG_ STCUT_RLY_FailureAlert : 19|1@0+ (1,0) [0|0] "" METER
  SG_ RearRightDoorOpenWarning : 21|2@0+ (1,0) [0|0] "" METER
  SG_ RearLeftDoorOpenWarning : 23|2@0+ (1,0) [0|0] "" METER
  SG_ AllWeather_Display : 25|2@0+ (1,0) [0|0] "" METER
  SG_ BCM_SteeringUpCommand : 26|1@0+ (1,0) [0|0] "" METER
  SG_ BCM_SteeringPushToTalkCommand : 27|1@0+ (1,0) [0|0] "" METER
  SG_ BCM_SteeringPhoneCommand : 28|1@0+ (1,0) [0|0] "" METER
  SG_ WashingInProgressDisplay : 29|1@0+ (1,0) [0|0] "" METER
  SG_ GlasshatchOpenWarning : 31|2@0+ (1,0) [0|0] "" METER
  SG_ BCM_SteeringDownCommand : 32|1@0+ (1,0) [0|0] "" METER
  SG_ BCM_SteeringCommandF : 33|1@0+ (1,0) [0|0] "" METER
  SG_ BCM_SteeringCommandE : 34|1@0+ (1,0) [0|0] "" METER
  SG_ BCM_SteeringCommandD : 35|1@0+ (1,0) [0|0] "" METER
  SG_ BCM_SteeringCommandC : 36|1@0+ (1,0) [0|0] "" METER
  SG_ BCM_SteeringCommandB : 37|1@0+ (1,0) [0|0] "" METER
  SG_ BCM_SteeringCommandA : 38|1@0+ (1,0) [0|0] "" METER
  SG_ BCM_MMISteeringSwitchesFailure : 39|1@0+ (1,0) [0|0] "" METER
  SG_ AccessModeState : 41|1@0+ (1,0) [0|0] "" METER
  SG_ LoadingAreaLocked_Display : 43|2@0+ (1,0) [0|0] "" METER
  SG_ CockpitLocked_Display : 45|2@0+ (1,0) [0|0] "" METER
  SG_ AutomaticLockUpActivationState_2 : 47|2@0+ (1,0) [0|0] "" METER
  SG_ ExtLightCheck_Result_display : 58|3@0+ (1,0) [0|0] "" METER
  SG_ DRLoffMode_Status : 60|2@0+ (1,0) [0|0] "" METER
  SG_ TrailerLightCheck_Status : 62|2@0+ (1,0) [0|0] "" METER

BO_ 1104 METER_A103: 8 METER
  SG_ RawFuelGaugeResistance : 7|10@0+ (1,0) [0|1022] "Ohm" BCM
  SG_ ExternalTempDisplayUnit : 8|1@0+ (1,0) [0|0] "" BCM
  SG_ DimmingState : 13|5@0+ (1,0) [0|0] "" BCM
  SG_ ExternalTempDisplayValue : 23|8@0+ (1,-40) [-40|140] "" BCM
  SG_ SteeringPushToTalkCommand : 24|1@0+ (1,0) [0|0] "" BCM
  SG_ SteeringPhoneCommand : 25|1@0+ (1,0) [0|0] "" BCM
  SG_ UnitDistanceDisplayState : 26|1@0+ (1,0) [0|0] "" BCM
  SG_ OilChangeCounterReset : 27|1@0+ (1,0) [0|0] "" BCM
  SG_ Meter_ADACresetRequest : 28|1@0+ (1,0) [0|0] "" BCM
  SG_ ManualDPFregenerationRequest : 29|1@0+ (1,0) [0|0] "" BCM
  SG_ DiagnosedFuelLow : 31|2@0+ (1,0) [0|0] "" BCM
  SG_ MuteRadioOrder : 32|1@0+ (1,0) [0|0] "" BCM
  SG_ WelcomeSequenceStatus : 34|2@0+ (1,0) [0|0] "" BCM
  SG_ FillerCapIndicatorResetStatus : 35|1@0+ (1,0) [0|0] "" BCM
  SG_ DisplayedOilLevel : 39|4@0+ (1,0) [0|0] "" BCM
  SG_ MeterVolumeState : 40|2@0+ (1,0) [0|0] "" BCM
  SG_ FuelLevelDisplayed : 47|7@0+ (1,0) [0|80] "L" BCM
  SG_ DayNightForMeterDisplay : 49|2@0+ (1,0) [0|0] "" MID
  SG_ SteeringFavoriteCommand : 50|1@0+ (1,0) [0|0] "" BCM
  SG_ DRLoffMode_Request : 52|2@0+ (1,0) [0|0] "" BCM
  SG_ TrailerLightCheck_Request : 54|2@0+ (1,0) [0|0] "" BCM
  SG_ SteeringMultiModeCommand : 60|1@0+ (1,0) [0|0] "" BCM
  SG_ SwitchIlluminationReq : 61|1@0+ (1,0) [0|0] "" MID
  SG_ MeterDisplayActivation : 63|2@0+ (1,0) [0|0] "" MID

BO_ 1105 METER_A104: 8 METER
  SG_ Clock_METER_A104 : 3|4@0+ (1,0) [0|15] "" BCM
  SG_ TPW_ResetDriverRequest : 5|2@0+ (1,0) [0|0] "" BCM
  SG_ TPMS_ResetDriverRequest : 7|2@0+ (1,0) [0|0] "" BCM
  SG_ CRC_METER_A104 : 15|8@0+ (1,0) [0|255] "" BCM
  SG_ OdoCustomerAction : 18|3@0+ (1,0) [0|6] "" BCM
  SG_ DisplayedSpeedUnit : 19|1@0+ (1,0) [0|0] "" BCM
  SG_ GlobalVehicleWarningState : 21|2@0+ (1,0) [0|0] "" BCM
  SG_ DayNightForBacklights : 23|2@0+ (1,0) [0|0] "" BCM,CMS_D,CMS_P,MID
  SG_ NightRheostatedLightMaxPercent : 31|8@0+ (0.4,0) [0|100] "%" BCM,CMS_D,CMS_P,MID
  SG_ ExternalTemperature : 37|9@0+ (0.25,-50) [-50|70] "°C" BCM
  SG_ ParkingBrakeStatus : 39|2@0+ (1,0) [0|0] "" BCM,DSMU,PBD,SCCM
  SG_ VehicleSpeedDisplayValue : 41|9@0+ (1,0) [0|510] "" BCM
  SG_ PeriodicReverseBuzzerTrigger : 42|1@0+ (1,0) [0|0] "" VSP
  SG_ LowBrakeFluidLevelStatus : 44|2@0+ (1,0) [0|0] "" BCM
  SG_ MeterResetRequest_PWTstart : 48|1@0+ (1,0) [0|0] "" BCM
  SG_ AirSusp_ActivationRequest : 57|2@0+ (1,0) [0|0] "" BCM
  SG_ METER_Status : 60|3@0+ (1,0) [0|0] "" BCM
  SG_ METER_CAN_CorruptionDetection : 62|2@0+ (1,0) [0|0] "" BCM
  SG_ MeterResetRequest_Refuel : 63|1@0+ (1,0) [0|0] "" BCM

BO_ 1106 METER_A108: 5 METER
  SG_ DayRheostatedLightMaxPercent : 7|8@0+ (0.4,0) [0|100] "%" BCM,MID
  SG_ TimeBeforeOverhaul : 15|9@0+ (1,0) [0|511] "day" BCM
  SG_ AutoDimmingState : 16|1@0+ (1,0) [0|0] "" BCM
  SG_ DayNightStatusForB_Switches : 17|1@0+ (1,0) [0|0] "" BCM,CMS_D,CMS_P
  SG_ Cluster_Refuse_to_Sleep : 22|2@0+ (1,0) [0|0] "" BCM
  SG_ TripAverageSpeed : 31|12@0+ (0.1,0) [0|409.5] "" BCM
  SG_ AutoDimmingOffsetY0 : 35|4@0+ (1,0) [0|0] "" BCM

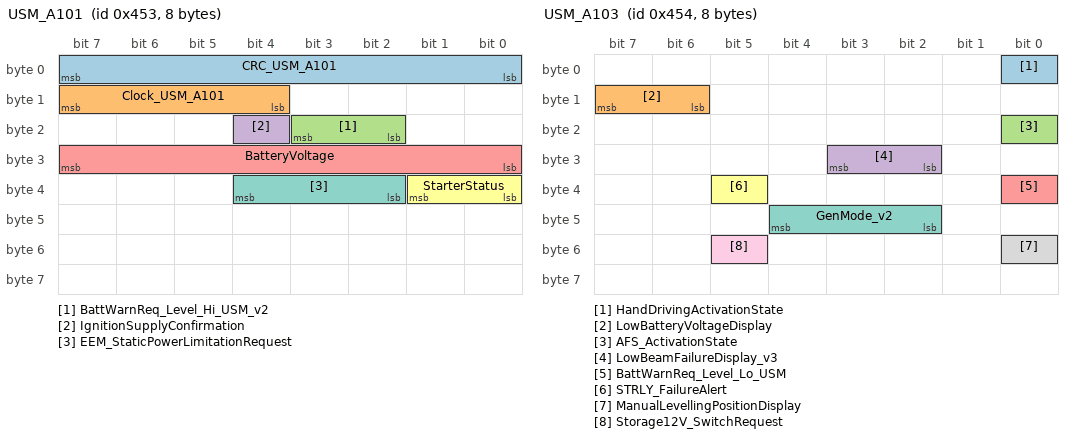
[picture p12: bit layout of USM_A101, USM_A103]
BO_ 1107 USM_A101: 8 BCM
  SG_ CRC_USM_A101 : 7|8@0+ (1,0) [0|255] "" METER
  SG_ Clock_USM_A101 : 15|4@0+ (1,0) [0|15] "" METER
  SG_ BattWarnReq_Level_Hi_USM_v2 : 19|2@0+ (1,0) [0|0] "" METER
  SG_ IgnitionSupplyConfirmation : 20|1@0+ (1,0) [0|0] "" DSMU,PBD,PSB_D,PSB_P,PSCU,VSP
  SG_ BatteryVoltage : 31|8@0+ (0.06,6) [6|18] "V" BMS_12V,DSMU,METER,PBD,PSB_D,PSB_P,PSCU,RSCU2R,RSCU3R,SCCM
  SG_ StarterStatus : 33|2@0+ (1,0) [0|0] "" METER
  SG_ EEM_StaticPowerLimitationRequest : 36|3@0+ (1,0) [0|0] "" DSMU,PSCU,RSCU2R

BO_ 1108 USM_A103: 8 BCM
  SG_ HandDrivingActivationState : 0|1@0+ (1,0) [0|0] "" METER
  SG_ LowBatteryVoltageDisplay : 15|2@0+ (1,0) [0|0] "" METER
  SG_ AFS_ActivationState : 16|1@0+ (1,0) [0|0] "" METER
  SG_ LowBeamFailureDisplay_v3 : 27|2@0+ (1,0) [0|0] "" METER
  SG_ BattWarnReq_Level_Lo_USM : 32|1@0+ (1,0) [0|0] "" METER
  SG_ STRLY_FailureAlert : 37|1@0+ (1,0) [0|0] "" METER
  SG_ GenMode_v2 : 44|3@0+ (1,0) [0|0] "" METER
  SG_ ManualLevellingPositionDisplay : 48|1@0+ (1,0) [0|0] "" METER
  SG_ Storage12V_SwitchRequest : 53|1@0+ (1,0) [0|0] "" BMS_12V

BO_ 1109 VDC_A113: 8 BCM
  SG_ CRC_VDC_A113 : 7|8@0+ (1,0) [0|255] "" METER
  SG_ HDC_StatusDisplay : 10|2@0+ (1,0) [0|0] "" METER
  SG_ EBAfailureDisplayAlert : 11|1@0+ (1,0) [0|0] "" METER
  SG_ Clock_VDC_A113 : 15|4@0+ (1,0) [0|15] "" METER
  SG_ BrakingSystemStateDisplayRequest : 16|1@0+ (1,0) [0|0] "" METER
  SG_ EBDstateDisplayRequest : 26|1@0+ (1,0) [0|0] "" METER
  SG_ CRBSfailureDisplayAlert : 27|1@0+ (1,0) [0|0] "" METER
  SG_ ABSstateDisplayRequest : 29|2@0+ (1,0) [0|0] "" METER
  SG_ VDCstateDisplayRequest : 31|2@0+ (1,0) [0|0] "" METER
  SG_ HSAstateDisplayRequest : 32|1@0+ (1,0) [0|0] "" METER
  SG_ HSA_StatusDisplay : 34|2@0+ (1,0) [0|0] "" METER
  SG_ TPW_AcknowledgeResetDriver : 42|2@0+ (1,0) [0|0] "" METER
  SG_ VDCdeactivationDisplayRequest : 49|1@0+ (1,0) [0|0] "" METER
  SG_ VDCactivationState : 50|1@0+ (1,0) [0|0] "" METER
  SG_ TPW_TireCheckReminder : 53|1@0+ (1,0) [0|0] "" METER
  SG_ TPW_Status : 55|2@0+ (1,0) [0|0] "" METER
  SG_ MCB_FailureDisplay : 57|1@0+ (1,0) [0|0] "" METER
  SG_ MiniBrakeFluidLevelAlertDisp : 58|1@0+ (1,0) [0|0] "" METER
  SG_ LowVacPWT_RestartImpossibleAlert : 61|1@0+ (1,0) [0|0] "" METER

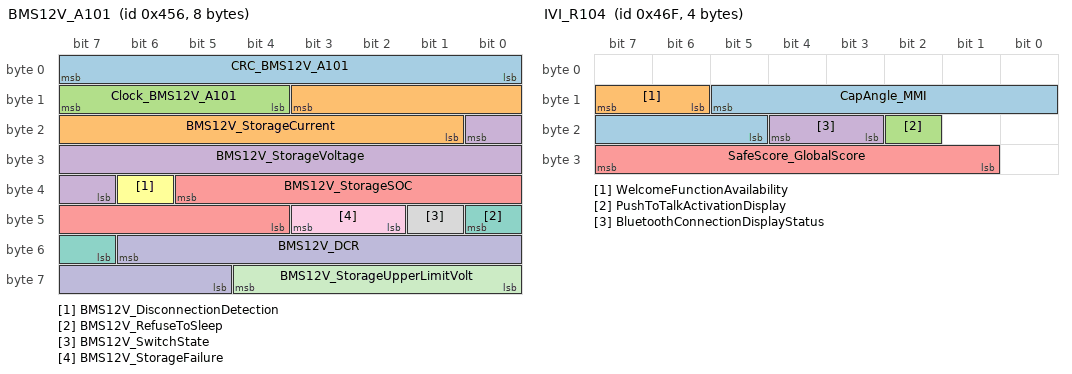
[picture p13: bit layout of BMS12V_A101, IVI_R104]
BO_ 1110 BMS12V_A101: 8 BMS_12V
  SG_ CRC_BMS12V_A101 : 7|8@0+ (1,0) [0|255] "" BCM
  SG_ BMS12V_StorageCurrent : 11|11@0+ (0.25,-150) [-150|300] "A" BCM
  SG_ Clock_BMS12V_A101 : 15|4@0+ (1,0) [0|15] "" BCM
  SG_ BMS12V_StorageVoltage : 16|10@0+ (0.01,9) [9|16] "V" BCM
  SG_ BMS12V_StorageSOC : 37|10@0+ (0.1,0) [0|100] "%" BCM
  SG_ BMS12V_DisconnectionDetection : 38|1@0+ (1,0) [0|0] "" BCM
  SG_ BMS12V_RefuseToSleep : 40|2@0+ (1,0) [0|0] "" BCM
  SG_ BMS12V_SwitchState : 41|1@0+ (1,0) [0|0] "" BCM
  SG_ BMS12V_StorageFailure : 43|2@0+ (1,0) [0|0] "" BCM
  SG_ BMS12V_DCR : 54|10@0+ (0.04,0) [0|40] "mOhm" BCM
  SG_ BMS12V_StorageUpperLimitVolt : 60|5@0+ (0.1,13.5) [13.5|16] "V" BCM

BO_ 1116 CDM_A116: 8 BCM
  SG_ SSAactivationState : 1|2@0+ (1,0) [0|0] "" METER
  SG_ SSA_StateLamp : 3|2@0+ (1,0) [0|0] "" METER
  SG_ IDM_FailureDisplay : 4|1@0+ (1,0) [0|0] "" METER
  SG_ GCC_IntendedVehicleMoment : 10|3@0+ (1,0) [0|0] "" METER
  SG_ GCC_ActualVehicleMoment : 12|2@0+ (1,0) [0|0] "" METER
  SG_ NotImmobilizedVehicleWarning_IDM : 13|1@0+ (1,0) [0|0] "" METER
  SG_ ASAactivationState : 14|1@0+ (1,0) [0|0] "" METER
  SG_ ADA1ActivationState : 15|1@0+ (1,0) [0|0] "" METER
  SG_ ATV_RatioDisplay_slow : 23|8@0+ (0.5,0) [0|100] "%" METER
  SG_ AWC_YawMomentValueDisplay : 27|4@0+ (1,-7) [-7|7] "" METER
  SG_ GCC_WheelBrake_FR : 30|1@0+ (1,0) [0|0] "" METER
  SG_ GCC_WheelBrake_FL : 31|1@0+ (1,0) [0|0] "" METER
  SG_ GCC_WheelBrake_RR : 32|1@0+ (1,0) [0|0] "" METER
  SG_ TorqueDistributionRatio_slow : 47|8@0+ (0.5,0) [0|100] "%" METER
  SG_ GCC_WheelBrake_RL : 48|1@0+ (1,0) [0|0] "" METER
  SG_ a4WS_AnglePosition_MMI : 55|7@0+ (0.1,-5) [-5|5] "deg" METER
  SG_ FrontWheelAngle_MMI : 63|7@0+ (1,-50) [-50|50] "°" METER

BO_ 1119 ECM_A108: 4 BCM
  SG_ CRC_ECM_A108 : 7|8@0+ (1,0) [0|255] "" METER
  SG_ BattWarnReq_Level_Hi_ECM_v2 : 11|2@0+ (1,0) [0|0] "" METER
  SG_ Clock_ECM_A108 : 15|4@0+ (1,0) [0|15] "" METER
  SG_ EngineCoolantTemp : 23|8@0+ (1,-40) [-40|214] "°C" METER
  SG_ BattWarnReq_Level_Lo_ECM : 31|1@0+ (1,0) [0|0] "" METER

BO_ 1120 ECM_R101: 8 BCM
  SG_ AdvisorEconometer : 7|7@0+ (1,0) [0|127] "%" METER
  SG_ RST_RevLimiterValue : 16|8@0+ (50,0) [0|12700] "rpm" METER
  SG_ ETS_ModeLamp_v2_ICE : 59|3@0+ (1,0) [0|0] "" METER
  SG_ RST_CC_ACC_DeactWarning : 61|2@0+ (1,0) [0|0] "" METER
  SG_ RST_CC_ACC_UnavailableRequest : 63|2@0+ (1,0) [0|0] "" METER

BO_ 1123 EVAP_A1: 8 BCM
  SG_ RefuelingStatus : 1|1@0+ (1,0) [0|0] "" METER

BO_ 1135 IVI_R104: 4 BCM
  SG_ CapAngle_MMI : 13|9@0+ (1,0) [0|360] "°" METER
  SG_ WelcomeFunctionAvailability : 15|2@0+ (1,0) [0|0] "" METER
  SG_ PushToTalkActivationDisplay : 18|1@0+ (1,0) [0|0] "" METER
  SG_ BluetoothConnectionDisplayStatus : 20|2@0+ (1,0) [0|0] "" METER
  SG_ SafeScore_GlobalScore : 31|7@0+ (1,0) [0|100] "-" METER

BO_ 1136 ECM_A107: 8 BCM
  SG_ EngineControlFailureLevel2 : 11|1@0+ (1,0) [0|0] "" METER
  SG_ EngineControlFailureLevel1 : 32|1@0+ (1,0) [0|0] "" METER
  SG_ RelativeEngineTorque_v2 : 54|7@0+ (1,0) [0|100] "%" METER
  SG_ DSICoachingDisplay : 62|2@0+ (1,0) [0|0] "" METER

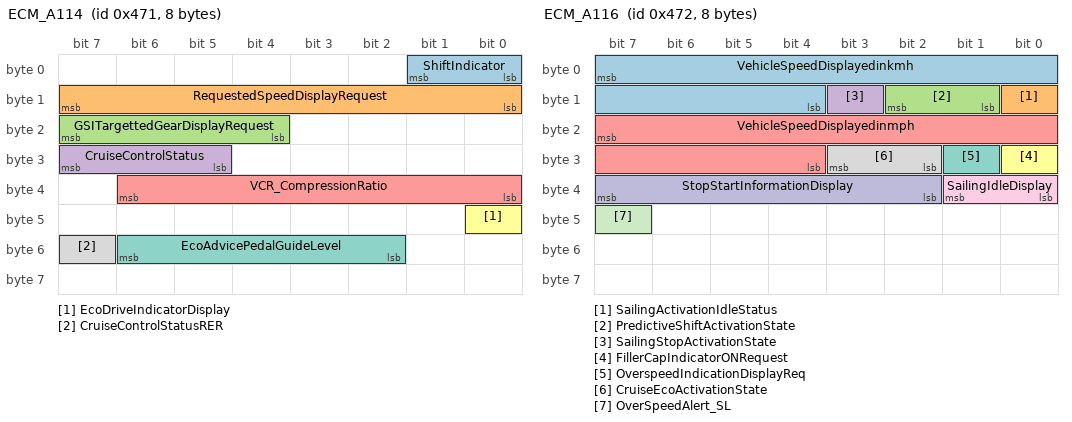
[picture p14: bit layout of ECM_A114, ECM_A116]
BO_ 1137 ECM_A114: 8 BCM
  SG_ ShiftIndicator : 1|2@0+ (1,0) [0|0] "" METER
  SG_ RequestedSpeedDisplayRequest : 15|8@0+ (1,0) [0|253] "" METER
  SG_ GSITargettedGearDisplayRequest : 23|4@0+ (1,0) [0|0] "" METER
  SG_ CruiseControlStatus : 31|3@0+ (1,0) [0|0] "" METER
  SG_ VCR_CompressionRatio : 38|7@0+ (0.1,7.5) [7.5|20.1] "" METER
  SG_ EcoDriveIndicatorDisplay : 40|1@0+ (1,0) [0|0] "" METER
  SG_ EcoAdvicePedalGuideLevel : 54|5@0+ (1,0) [0|30] "wu" METER
  SG_ CruiseControlStatusRER : 55|1@0+ (1,0) [0|0] "" METER

BO_ 1138 ECM_A116: 8 BCM
  SG_ VehicleSpeedDisplayedinkmh : 7|12@0+ (0.1,0) [0|409.4] "km/h" METER
  SG_ SailingActivationIdleStatus : 8|1@0+ (1,0) [0|0] "" METER
  SG_ PredictiveShiftActivationState : 10|2@0+ (1,0) [0|0] "" METER
  SG_ SailingStopActivationState : 11|1@0+ (1,0) [0|0] "" METER
  SG_ VehicleSpeedDisplayedinmph : 23|12@0+ (0.1,0) [0|409.4] "m/h" METER
  SG_ FillerCapIndicatorONRequest : 24|1@0+ (1,0) [0|0] "" METER
  SG_ OverspeedIndicationDisplayReq : 25|1@0+ (1,0) [0|0] "" METER
  SG_ CruiseEcoActivationState : 27|2@0+ (1,0) [0|0] "" METER
  SG_ SailingIdleDisplay : 33|2@0+ (1,0) [0|0] "" METER
  SG_ StopStartInformationDisplay : 39|6@0+ (1,0) [0|0] "" METER,VSP
  SG_ OverSpeedAlert_SL : 47|1@0+ (1,0) [0|0] "" METER

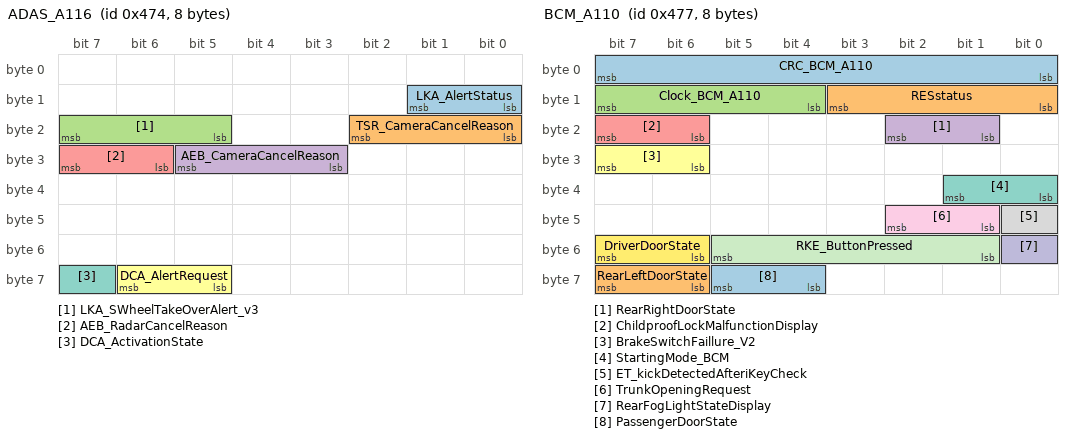
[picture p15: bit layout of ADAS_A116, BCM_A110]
BO_ 1140 ADAS_A116: 8 BCM
  SG_ LKA_AlertStatus : 9|2@0+ (1,0) [0|0] "" METER
  SG_ TSR_CameraCancelReason : 18|3@0+ (1,0) [0|0] "" METER
  SG_ LKA_SWheelTakeOverAlert_v3 : 23|3@0+ (1,0) [0|0] "" METER
  SG_ AEB_CameraCancelReason : 29|3@0+ (1,0) [0|0] "" METER
  SG_ AEB_RadarCancelReason : 31|2@0+ (1,0) [0|0] "" METER
  SG_ DCA_AlertRequest : 62|2@0+ (1,0) [0|0] "" METER
  SG_ DCA_ActivationState : 63|1@0+ (1,0) [0|0] "" METER

BO_ 1143 BCM_A110: 8 BCM
  SG_ CRC_BCM_A110 : 7|8@0+ (1,0) [0|255] "" METER
  SG_ RESstatus : 11|4@0+ (1,0) [0|0] "" DSMU,PSCU,SCCM
  SG_ Clock_BCM_A110 : 15|4@0+ (1,0) [0|15] "" METER
  SG_ RearRightDoorState : 18|2@0+ (1,0) [0|0] "" PBD,RSCU2R
  SG_ ChildproofLockMalfunctionDisplay : 23|2@0+ (1,0) [0|0] "" METER
  SG_ BrakeSwitchFaillure_V2 : 31|2@0+ (1,0) [0|0] "" METER
  SG_ StartingMode_BCM : 33|2@0+ (1,0) [0|0] "" DSMU,METER,PSCU,RSCU2R,RSCU3R,SCCM
  SG_ ET_kickDetectedAfteriKeyCheck : 40|1@0+ (1,0) [0|0] "" PBD
  SG_ TrunkOpeningRequest : 42|2@0+ (1,0) [0|0] "" PBD
  SG_ RearFogLightStateDisplay : 48|1@0+ (1,0) [0|0] "" METER
  SG_ RKE_ButtonPressed : 53|5@0+ (1,0) [0|0] "" PBD
  SG_ DriverDoorState : 55|2@0+ (1,0) [0|0] "" DSMU,METER,PBD,PSB_D,PSB_P,SCCM
  SG_ PassengerDoorState : 61|2@0+ (1,0) [0|0] "" METER,PBD,PSB_D,PSB_P,PSCU
  SG_ RearLeftDoorState : 63|2@0+ (1,0) [0|0] "" PBD,RSCU2R

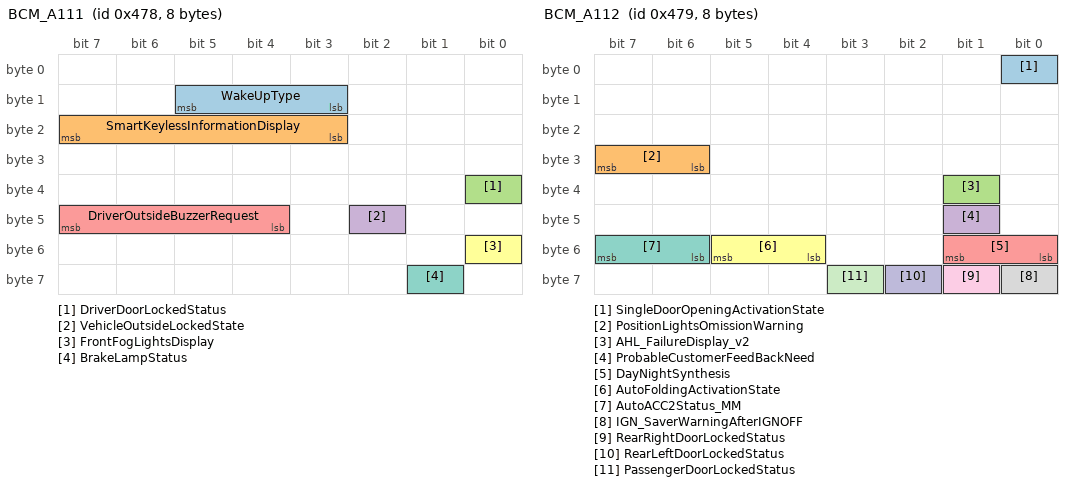
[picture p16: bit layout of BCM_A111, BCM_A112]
BO_ 1144 BCM_A111: 8 BCM
  SG_ WakeUpType : 13|3@0+ (1,0) [0|0] "" METER
  SG_ SmartKeylessInformationDisplay : 23|5@0+ (1,0) [0|0] "" METER
  SG_ DriverDoorLockedStatus : 32|1@0+ (1,0) [0|0] "" DSMU,PBD
  SG_ VehicleOutsideLockedState : 42|1@0+ (1,0) [0|0] "" METER,PBD
  SG_ DriverOutsideBuzzerRequest : 47|4@0+ (1,0) [0|0] "" VSP
  SG_ FrontFogLightsDisplay : 48|1@0+ (1,0) [0|0] "" METER
  SG_ BrakeLampStatus : 57|1@0+ (1,0) [0|0] "" METER

BO_ 1145 BCM_A112: 8 BCM
  SG_ SingleDoorOpeningActivationState : 0|1@0+ (1,0) [0|0] "" METER
  SG_ PositionLightsOmissionWarning : 31|2@0+ (1,0) [0|0] "" METER
  SG_ AHL_FailureDisplay_v2 : 33|1@0+ (1,0) [0|0] "" METER
  SG_ ProbableCustomerFeedBackNeed : 41|1@0+ (1,0) [0|0] "" METER
  SG_ DayNightSynthesis : 49|2@0+ (1,0) [0|0] "" METER
  SG_ AutoFoldingActivationState : 53|2@0+ (1,0) [0|0] "" METER
  SG_ AutoACC2Status_MM : 55|2@0+ (1,0) [0|0] "" METER
  SG_ IGN_SaverWarningAfterIGNOFF : 56|1@0+ (1,0) [0|0] "" METER
  SG_ RearRightDoorLockedStatus : 57|1@0+ (1,0) [0|0] "" PBD
  SG_ RearLeftDoorLockedStatus : 58|1@0+ (1,0) [0|0] "" PBD
  SG_ PassengerDoorLockedStatus : 59|1@0+ (1,0) [0|0] "" PBD

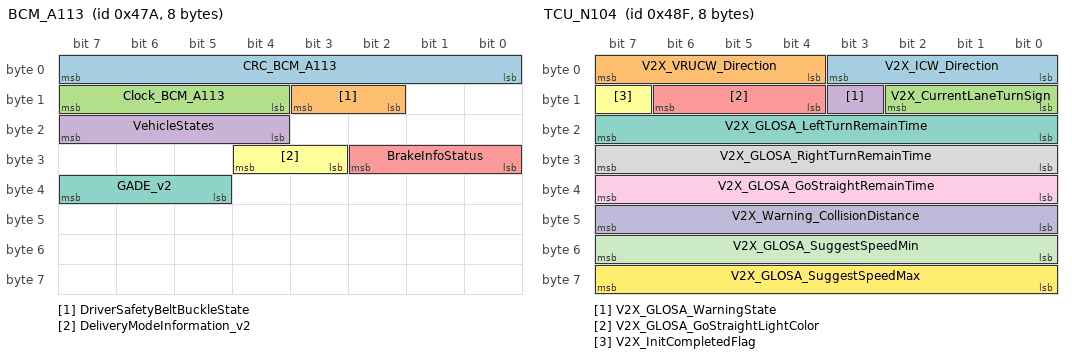
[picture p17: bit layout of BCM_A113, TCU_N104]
BO_ 1146 BCM_A113: 8 BCM
  SG_ CRC_BCM_A113 : 7|8@0+ (1,0) [0|255] "" METER,PSB_D
  SG_ DriverSafetyBeltBuckleState : 11|2@0+ (1,0) [0|0] "" METER,PSB_D
  SG_ Clock_BCM_A113 : 15|4@0+ (1,0) [0|15] "" METER,PSB_D
  SG_ VehicleStates : 23|4@0+ (1,0) [0|0] "" DSMU,METER,PBD,PSCU,RSCU2R,RSCU3R,SCCM,VSP
  SG_ BrakeInfoStatus : 26|3@0+ (1,0) [0|0] "" VSP
  SG_ DeliveryModeInformation_v2 : 28|2@0+ (1,0) [0|0] "" DSMU,METER,PSCU,RSCU2R,RSCU3R,SCCM,VSP
  SG_ GADE_v2 : 39|3@0+ (1,0) [0|0] "" BMS_12V,CMS_D,CMS_P,DSMU,METER,MID,PBD,PSB_D,PSB_P,PSCU,RSCU2R,RSCU3R,SCCM,VSP

BO_ 1147 ECM_A105: 8 BCM
  SG_ BoostPressureDisplay : 7|8@0+ (2,-100) [-100|408] "kPa" METER
  SG_ Maintenance_Mode_Display : 16|1@0+ (1,0) [0|0] "" METER
  SG_ OilPressureWarning_ECM : 17|1@0+ (1,0) [0|0] "" METER
  SG_ WarningWaterTemp : 18|1@0+ (1,0) [0|0] "" METER
  SG_ ECM_WarningMessage5 : 19|1@0+ (1,0) [0|0] "" METER
  SG_ ECM_WarningMessage4 : 20|1@0+ (1,0) [0|0] "" METER
  SG_ ECM_WarningMessage3 : 21|1@0+ (1,0) [0|0] "" METER
  SG_ ECM_WarningMessage2 : 22|1@0+ (1,0) [0|0] "" METER
  SG_ ECM_WarningMessage1 : 23|1@0+ (1,0) [0|0] "" METER
  SG_ FuelConsumption : 31|8@0+ (80,0) [0|20400] "mm3" METER
  SG_ CCSL_CancelReason : 35|4@0+ (1,0) [0|0] "" METER
  SG_ MILLamp : 39|4@0+ (1,0) [0|0] "" METER
  SG_ Engine_high_oil_level_warning : 40|1@0+ (1,0) [0|0] "" METER
  SG_ CCSL_TransitionStatesDisplay : 45|5@0+ (1,0) [0|0] "" METER
  SG_ CCSL_CancelReasonRER : 46|1@0+ (1,0) [0|0] "" METER
  SG_ ECM_OilPressureSwitchFaultDisp : 47|1@0+ (1,0) [0|0] "" METER
  SG_ Engine_low_oil_level_warning : 55|1@0+ (1,0) [0|0] "" METER

BO_ 1148 ERDC_R_A101: 5 BCM
  SG_ ERDC_R_RefuseToOpenAlertDisplay : 11|2@0+ (1,0) [0|0] "" METER
  SG_ ERDC_R_RefuseToOpenAlertDisp_RER : 37|2@0+ (1,0) [0|0] "" METER

BO_ 1149 ADAS_A153: 8 BCM
  SG_ AD_LaneMarker1_1 : 2|3@0+ (1,0) [0|0] "" METER
  SG_ AD_DrivingLaneType : 4|2@0+ (1,0) [0|0] "" METER
  SG_ AD_CurveStatus : 7|3@0+ (1,0) [0|0] "" METER
  SG_ AD_LineShort1_2 : 8|1@0+ (1,0) [0|0] "" METER
  SG_ AD_LineShort1_1 : 9|1@0+ (1,0) [0|0] "" METER
  SG_ AD_LaneMarker2_1 : 12|3@0+ (1,0) [0|0] "" METER
  SG_ AD_LaneMarker1_2 : 15|3@0+ (1,0) [0|0] "" METER
  SG_ AD_LineShort2_2 : 16|1@0+ (1,0) [0|0] "" METER
  SG_ AD_LineShort2_1 : 17|1@0+ (1,0) [0|0] "" METER
  SG_ AD_LaneMarker3_1 : 20|3@0+ (1,0) [0|0] "" METER
  SG_ AD_LaneMarker2_2 : 23|3@0+ (1,0) [0|0] "" METER
  SG_ AD_LineShort3_2 : 24|1@0+ (1,0) [0|0] "" METER
  SG_ AD_LineShort3_1 : 25|1@0+ (1,0) [0|0] "" METER
  SG_ AD_LaneMarker4_1 : 28|3@0+ (1,0) [0|0] "" METER
  SG_ AD_LaneMarker3_2 : 31|3@0+ (1,0) [0|0] "" METER
  SG_ ALC_TurnByTurnPriority : 33|1@0+ (1,0) [0|0] "" METER
  SG_ AD_LowHighViewState : 34|1@0+ (1,0) [0|0] "" METER
  SG_ AD_LineShort4_2 : 35|1@0+ (1,0) [0|0] "" METER
  SG_ AD_LineShort4_1 : 36|1@0+ (1,0) [0|0] "" METER
  SG_ AD_LaneMarker4_2 : 39|3@0+ (1,0) [0|0] "" METER
  SG_ AD2_ALCGapDetection : 44|5@0+ (1,0) [0|0] "" METER
  SG_ AD2_CarPoolLaneNotification : 47|3@0+ (1,0) [0|0] "" METER
  SG_ AD2_HostVehicleLanePosition : 51|4@0+ (1,0) [0|0] "" METER
  SG_ AD2_NumOfLane : 55|4@0+ (1,0) [0|0] "" METER

BO_ 1150 ADAS_A149: 7 BCM
  SG_ CRC_ADAS_A149 : 7|8@0+ (1,0) [0|255] "" METER
  SG_ SET_PositionInLane_State : 9|2@0+ (1,0) [0|0] "" METER
  SG_ SET_VoiceGuidance_State : 11|2@0+ (1,0) [0|0] "" METER
  SG_ Clock_ADAS_A149 : 15|4@0+ (1,0) [0|15] "" METER
  SG_ SET_LaneChangeSwiftness_State : 17|2@0+ (1,0) [0|0] "" METER
  SG_ SET_NavigatDriveAssist_State : 19|2@0+ (1,0) [0|0] "" METER
  SG_ SET_OvertakeRelatSpeed_State : 21|2@0+ (1,0) [0|0] "" METER
  SG_ SET_OvertakingAssist_State : 23|2@0+ (1,0) [0|0] "" METER
  SG_ SET_Acceleration_State : 25|2@0+ (1,0) [0|0] "" METER
  SG_ SET_ALCActivationByTSIG_State : 27|2@0+ (1,0) [0|0] "" METER
  SG_ SET_CornerSpeedLevel_State : 29|2@0+ (1,0) [0|0] "" METER
  SG_ SET_Deceleration_State : 31|2@0+ (1,0) [0|0] "" METER
  SG_ RAB_CancelReason_v2 : 35|4@0+ (1,0) [0|0] "" METER
  SG_ ADL3_DisclaimerRepetitionRequest : 36|1@0+ (1,0) [0|0] "" METER
  SG_ CASP_ActivationState : 40|1@0+ (1,0) [0|0] "" METER
  SG_ SET_ADL3Activation_State : 42|2@0+ (1,0) [0|0] "" METER
  SG_ SET_AD_HandsOff_State : 44|2@0+ (1,0) [0|0] "" METER
  SG_ SET_ALC_AssistMode_State : 46|2@0+ (1,0) [0|0] "" METER
  SG_ CASP_Extended_ConvertedSpeedReq : 47|1@0+ (1,0) [0|0] "" METER
  SG_ SET_ContextSpdLocal_ActState : 53|2@0+ (1,0) [0|0] "" METER
  SG_ AES_ActivationState : 55|2@0+ (1,0) [0|0] "" METER

BO_ 1152 ERDC_L_A101: 5 BCM
  SG_ ERDC_L_RefuseToOpenAlertDisplay : 3|2@0+ (1,0) [0|0] "" METER
  SG_ ERDC_L_RefuseToOpenAlertDisp_RER : 37|2@0+ (1,0) [0|0] "" METER

BO_ 1161 MBL_A1: 1 BCM
  SG_ MBLfailureDisplay : 7|1@0+ (1,0) [0|0] "" METER

BO_ 1165 BCM_R102: 4 BCM
  SG_ OEMmode_display_request : 18|3@0+ (1,0) [0|0] "" METER
  SG_ OEMmode_coupling_Alert : 19|1@0+ (1,0) [0|0] "" METER
  SG_ OEMmodeMenuState : 23|4@0+ (1,0) [0|0] "" METER
  SG_ StopLampCANfailure_display : 31|1@0+ (1,0) [0|0] "" METER

BO_ 1167 TCU_N104: 8 BCM
  SG_ V2X_ICW_Direction : 3|4@0+ (1,0) [0|0] "" METER
  SG_ V2X_VRUCW_Direction : 7|4@0+ (1,0) [0|0] "" METER
  SG_ V2X_CurrentLaneTurnSign : 10|3@0+ (1,0) [0|0] "" METER
  SG_ V2X_GLOSA_WarningState : 11|1@0+ (1,0) [0|0] "" METER
  SG_ V2X_GLOSA_GoStraightLightColor : 14|3@0+ (1,0) [0|0] "" METER
  SG_ V2X_InitCompletedFlag : 15|1@0+ (1,0) [0|0] "" METER
  SG_ V2X_GLOSA_LeftTurnRemainTime : 23|8@0+ (1,0) [0|254] "s" METER
  SG_ V2X_GLOSA_RightTurnRemainTime : 31|8@0+ (1,0) [0|254] "s" METER
  SG_ V2X_GLOSA_GoStraightRemainTime : 39|8@0+ (1,0) [0|254] "s" METER
  SG_ V2X_Warning_CollisionDistance : 47|8@0+ (1,0) [0|254] "m" METER
  SG_ V2X_GLOSA_SuggestSpeedMin : 55|8@0+ (1,0) [0|254] "km/h" METER
  SG_ V2X_GLOSA_SuggestSpeedMax : 63|8@0+ (1,0) [0|254] "km/h" METER

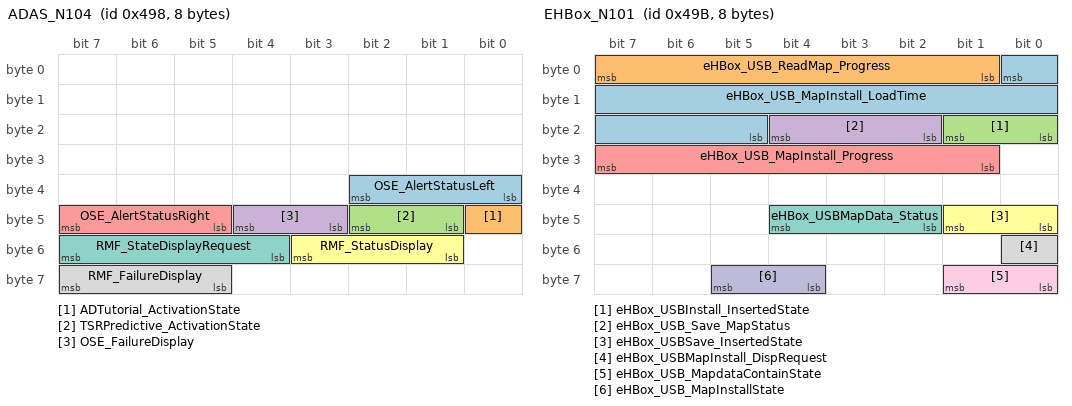
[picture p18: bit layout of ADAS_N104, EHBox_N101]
BO_ 1176 ADAS_N104: 8 BCM
  SG_ OSE_AlertStatusLeft : 34|3@0+ (1,0) [0|0] "" METER
  SG_ ADTutorial_ActivationState : 40|1@0+ (1,0) [0|0] "" METER
  SG_ TSRPredictive_ActivationState : 42|2@0+ (1,0) [0|0] "" METER
  SG_ OSE_FailureDisplay : 44|2@0+ (1,0) [0|0] "" METER
  SG_ OSE_AlertStatusRight : 47|3@0+ (1,0) [0|0] "" METER
  SG_ RMF_StatusDisplay : 51|3@0+ (1,0) [0|0] "" METER
  SG_ RMF_StateDisplayRequest : 55|4@0+ (1,0) [0|0] "" METER
  SG_ RMF_FailureDisplay : 63|3@0+ (1,0) [0|0] "" METER

BO_ 1177 METER_A111: 1 METER
  SG_ DMC_Tempoff_Request : 2|1@0+ (1,0) [0|0] "" BCM
  SG_ RMF_Tempoff_Request : 3|1@0+ (1,0) [0|0] "" BCM
  SG_ WiperLinkedALSActivationRequest : 5|2@0+ (1,0) [0|0] "" BCM
  SG_ OverSpeedWarningSoundMute : 6|1@0+ (1,0) [0|0] "" BCM
  SG_ DAA_Tempoff_Request : 7|1@0+ (1,0) [0|0] "" BCM

BO_ 1179 EHBox_N101: 8 BCM
  SG_ eHBox_USB_MapInstall_LoadTime : 0|12@0+ (1,0) [0|0] "" METER
  SG_ eHBox_USB_ReadMap_Progress : 7|7@0+ (1,0) [0|100] "%" METER
  SG_ eHBox_USBInstall_InsertedState : 17|2@0+ (1,0) [0|0] "" METER
  SG_ eHBox_USB_Save_MapStatus : 20|3@0+ (1,0) [0|0] "" METER
  SG_ eHBox_USB_MapInstall_Progress : 31|7@0+ (1,0) [0|100] "%" METER
  SG_ eHBox_USBSave_InsertedState : 41|2@0+ (1,0) [0|0] "" METER
  SG_ eHBox_USBMapData_Status : 44|3@0+ (1,0) [0|0] "" METER
  SG_ eHBox_USBMapInstall_DispRequest : 48|1@0+ (1,0) [0|0] "" METER
  SG_ eHBox_USB_MapdataContainState : 57|2@0+ (1,0) [0|0] "" METER
  SG_ eHBox_USB_MapInstallState : 61|2@0+ (1,0) [0|0] "" METER

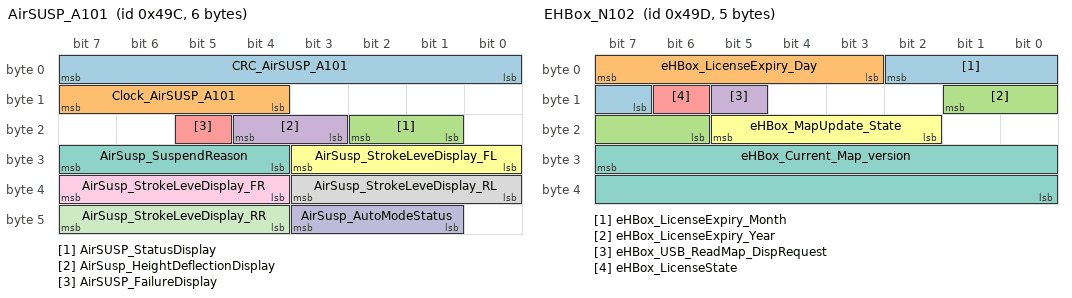
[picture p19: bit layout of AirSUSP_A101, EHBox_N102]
BO_ 1180 AirSUSP_A101: 6 BCM
  SG_ CRC_AirSUSP_A101 : 7|8@0+ (1,0) [0|255] "" METER
  SG_ Clock_AirSUSP_A101 : 15|4@0+ (1,0) [0|15] "" METER
  SG_ AirSUSP_StatusDisplay : 18|2@0+ (1,0) [0|0] "" METER
  SG_ AirSusp_HeightDeflectionDisplay : 20|2@0+ (1,0) [0|0] "" METER
  SG_ AirSUSP_FailureDisplay : 21|1@0+ (1,0) [0|0] "" METER
  SG_ AirSusp_StrokeLeveDisplay_FL : 27|4@0+ (1,0) [0|0] "" METER
  SG_ AirSusp_SuspendReason : 31|4@0+ (1,0) [0|0] "" METER
  SG_ AirSusp_StrokeLeveDisplay_RL : 35|4@0+ (1,0) [0|0] "" METER
  SG_ AirSusp_StrokeLeveDisplay_FR : 39|4@0+ (1,0) [0|0] "" METER
  SG_ AirSusp_AutoModeStatus : 43|3@0+ (1,0) [0|0] "" METER
  SG_ AirSusp_StrokeLeveDisplay_RR : 47|4@0+ (1,0) [0|0] "" METER

BO_ 1181 EHBox_N102: 5 BCM
  SG_ eHBox_LicenseExpiry_Month : 2|4@0+ (1,0) [0|12] "Month" METER
  SG_ eHBox_LicenseExpiry_Day : 7|5@0+ (1,0) [0|31] "Day" METER
  SG_ eHBox_LicenseExpiry_Year : 9|4@0+ (1,2036) [2036|2050] "Year" METER
  SG_ eHBox_USB_ReadMap_DispRequest : 13|1@0+ (1,0) [0|0] "" METER
  SG_ eHBox_LicenseState : 14|1@0+ (1,0) [0|0] "" METER
  SG_ eHBox_MapUpdate_State : 21|4@0+ (1,0) [0|0] "" METER
  SG_ eHBox_Current_Map_version : 31|16@0+ (1,0) [0|0] "" METER

VAL_ 32 AirbagCrashOrder_v3 0 "Crash not detected" 15 "Medium crash" 31 "Violent crash" 47 "Rear crash";
VAL_ 32 PreRolloverDetection 0 "PreRollover not detected" 1 "PreRollover detected";
VAL_ 32 RolloverDetection 0 "Rollover not detected" 1 "Rollover detected";
VAL_ 116 StopAutoPhase 0 "NotInAutoPhase" 1 "StartAuto" 2 "StopAuto" 3 "Not Used" 4 "StopAutoOngoing" 5 "StartByInjectionOnly" 6 "ReflexStart" 7 "Unavailable";
VAL_ 117 PowerTrainStatus 0 "Powertrain Stopped" 1 "Reserved" 2 "Powertrain Running" 3 "Powertrain Starting";
VAL_ 117 EngineStopRequestOrigin 0 "No engine stop request (initial stop or independant engine running)" 1 "Engine stopped by other causes" 2 "Engine stopped by normal system request" 3 "Engine stopped by normal driver request" 4 "Engine stopped by emergency request" 5 "Not used" 6 "Not used" 7 "Not used";
VAL_ 159 AEB_BrakeWheelTorqueOrder2 0 "No Brake Request" 1 "Brake Torque AEBS moderate" 2 "Brake Torque AEBS strong" 3 "Brake Torque AEBS city" 4 "Brake Torque AEBS Maximum" 5 "Not used" 6 "Not used" 7 "unavailable";
VAL_ 168 SwaSensorInternalStatus 0 "not calibrated, not indexed" 1 "not calibrated, indexed" 2 "fault" 3 "reserved" 4 "calibrated, not initialised" 5 "calibrated, initialised" 6 "reserved" 7 "reserved";
VAL_ 303 GearLeverPosition_v2 0 "Parking - P" 1 "Reverse - R" 2 "Neutral - N" 3 "Drive - D" 4 "Manual mode - M" 5 "L" 6 "Ds" 7 "Confirmed lever position (no switch signal)" 8 "B (Brake)" 9 "Not used" 10 "Not used" 11 "Not used" 12 "Not used" 13 "Not used" 14 "Not used" 15 "Not available (init or lever switched failure)";
VAL_ 514 ABSinRegulation 0 "no ABS regulation" 1 "ABS in regulation";
VAL_ 514 ESCMalfunction 0 "No VDC (ESC) malfunction" 1 "VDC (ESC) malfunction";
VAL_ 514 ABSMalfunction 0 "no ABS malfunction" 1 "ABS malfunction";
VAL_ 534 EPSWarning 0 "No EPS warning" 1 "EPS failure level 1" 2 "EPS failure level 2" 3 "EPS meter lamp check";
VAL_ 549 StopLampFlashingRequest 0 "Stop lamps flashing no requested" 1 "Stop lamps flashing requested";
VAL_ 559 ADAS_SwitchTransitionDisplay 0 "No display" 1 "Contextual dead switch transition display" 2 "Custom shield dead switch transition display" 3 "Not used" 4 "Not used" 5 "Not used" 6 "Not used" 7 "Not used";
VAL_ 569 ETS_WarningLamp 0 "No ETS warning display Request" 1 "ETS warning display Request";
VAL_ 569 TorqueVectoringIndicateReq_RR 0 "Turn off indicator" 1 "Turn on No.1 indicator" 2 "Turn on No.1 and No.2 indicator" 3 "Turn on No.1,No.2 and No.3 indicator" 4 "Turn on No.1,No.2,No.3 and No.4 indicator" 5 "Not used" 6 "Not used" 7 "Not used";
VAL_ 569 TorqueVectoringIndicateReq_RL 0 "Turn off indicator" 1 "Turn on No.1 indicator" 2 "Turn on No.1 and No.2 indicator" 3 "Turn on No.1,No.2 and No.3 indicator" 4 "Turn on No.1,No.2,No.3 and No.4 indicator" 5 "Not used" 6 "Not used" 7 "Not used";
VAL_ 569 ETS_WARN_MMD1 0 "No ETS warning display Request" 1 "ETS warning display Request";
VAL_ 569 ETS_WARN_MMD2 0 "No ETS warning display Request" 1 "ETS warning display Request";
VAL_ 569 ETS_ShiftInProgressStatus 0 "No Display - Not in progress" 1 "Display Shift In progress";
VAL_ 569 ETS_ModeLamp_v2 0 "No Display" 1 "LOCK" 2 "2WD" 3 "4Lo (SNOW)" 4 "While shifting H-L 1" 5 "While shifting H-L 2" 6 "AUTO" 7 "Not Used";
VAL_ 604 ParkingBrakeBindingStatus 0 "brake released" 1 "brake tightened" 2 "Not used" 3 "unavailable";
VAL_ 650 VehicleSpeedClock 0 "This counter is incremented when CAN buffers are updated";
VAL_ 650 VDC_StandStillSupposed 0 "Unavailable" 1 "StandStill" 2 "Moving" 3 "Not used";
VAL_ 696 ETS_ModeLamp_v3_ICE 0 "No Display" 1 "LOCK" 2 "4x2" 3 "4Lo (SNOW)" 4 "While shifting H-L 1" 5 "While shifting H-L 2" 6 "AUTO" 7 "AWD overheating";
VAL_ 696 GasInstantCarburationMod 0 "Gasoline mode" 1 "LPG or CNG";
VAL_ 696 LPG_NGSystemMalfunction 0 "no failure" 1 "LPG/NG system failure";
VAL_ 696 LPGModeDisplayRequest_V2 0 "no display" 1 "LPG OFF" 2 "LPG in waiting" 3 "LPG Active" 4 "LPG in failure" 5 "LPG Performance limitation" 6 "Not Used" 7 "Not Used";
VAL_ 696 LPGModeDisplayRequest 0 "LPG Mode OFF" 1 "LPG Mode ON";
VAL_ 699 VaccumPumpDurabilityLimitAlert 0 "no display request" 1 "close to Vacuum pump durability limit alert" 2 "Vacuum pump durability limit exceeded alert" 3 "Not used";
VAL_ 704 SlipStatus_RR 0 "Not Slip" 1 "Slip";
VAL_ 704 SlipStatus_RL 0 "Not Slip" 1 "Slip";
VAL_ 704 SlipStatus_FR 0 "Not Slip" 1 "Slip";
VAL_ 704 SlipStatus_FL 0 "Not Slip" 1 "Slip";
VAL_ 735 ATP_warning 0 "No warning" 1 "ATP warning";
VAL_ 735 AWD_ModeChangeCancelReasonRER 0 "No request" 1 "Reemission request";
VAL_ 735 ETS_WarningLamp_v2 0 "No ETS warning display Request" 1 "ETS warning display Request";
VAL_ 735 AWD_WarningRequest_TI 0 "no request" 1 "AWD warining lamp request";
VAL_ 735 AWD_ModeChangeCanelReason 0 "No display" 1 "4L refused : Not AT position N" 2 "4L refused : Not vehicle speed 0 and brake off" 3 "4H,AUTO refused : Not AT position N" 4 "4H,AUTO refused : Not vehicle speed 0 and brake off" 5 "4L refused : DriveMode condition" 6 "4H refused : DriveMode condition" 7 "AUTO refused : DriveMode condition" 8 "Reserved" 9 "Reserved" 10 "Reserved" 11 "Reserved" 12 "Reserved" 13 "Reserved" 14 "Reserved" 15 "Reserved";
VAL_ 747 DiffLockChange_CancelReasonRER 0 "No request" 1 "Reemission request";
VAL_ 747 DiffLock_IndicatorSignal 0 "No Display" 1 "Lock ON" 2 "Transition" 3 "Failure";
VAL_ 747 DiffLock_Change_CancelReason 0 "No display" 1 "Not 4L mode" 2 "Not vehicle speed less than 7 km/h" 3 "Not Used";
VAL_ 747 DFR_HMI_TXT 0 "No display" 1 "Display";
VAL_ 747 DFR_HMI_MEMORY_TXT 0 "No Display" 1 "Display";
VAL_ 791 ISS_EcoActivationState 0 "Unavailable" 1 "ECO activated" 2 "ECO deactivated" 3 "Not used";
VAL_ 791 AirCondEcoActivationState 0 "Unavailable" 1 "ECO activated" 2 "ECO deactivated" 3 "Not used";
VAL_ 791 ClimECOModeStatusDisplay 0 "No display" 1 "Activated" 2 "Not Activated" 3 "Unavailable";
VAL_ 893 LDW_VibrationIntensityState 0 "Unavailable" 1 "Low Intensity" 2 "Middle Intensity" 3 "High Intensity";
VAL_ 896 DTCO_Driver1TimeRelatedStates 0 "Normal_No Limits Reached" 1 "Limit1_15Min Before 4h30" 2 "Limit2_4h30 Reached" 3 "Limit3_15Min Before 9h" 4 "Limit4_9h Reached" 5 "Limit5_15Min Before 16h" 6 "Limit6_16h Reached" 7 "WeeklyDrivingTimePreWarningActive" 8 "WeeklyDrivingTimeWarningActive" 9 "2WeeksDrivingTimePreWarningActive" 10 "2WeeksDrivingTimeWarningActive" 11 "Driver1CardExpiryWarningActive" 12 "NextMandatoryDriver1CardDownloadWarningActive" 13 "Other" 14 "Error" 15 "NotAvailable";
VAL_ 896 DTCO_OverSpeed 0 "No Overspeed" 1 "Overspeed" 2 "Error" 3 "Not Available";
VAL_ 896 DTCO_Driver2TimeRelatedStates 0 "no time related warning detected." 1 "Reserved" 2 "Reserved" 3 "Reserved" 4 "Reserved" 5 "daily/weekly rest pre-warning active" 6 "daily/weekly rest warning active" 7 "Reserved" 8 "Reserved" 9 "Reserved" 10 "Reserved" 11 "driver 2 card expiry warning active" 12 "next mandatory driver 2 card download warning active" 13 "Other" 14 "Error" 15 "Not available";
VAL_ 930 DMC_UnresponsiveAlertStatus 0 "No display" 1 "Fatigue_Lv1" 2 "Drowsiness_Lv1" 3 "Fatigue_Lv2" 4 "Drowsiness_Lv2" 5 "Duration" 6 "Stopped" 7 "Reserved";
VAL_ 934 APA_StatusDisplay2 0 "Automatic maneuver OFF" 1 "Automatic maneuver Standby" 2 "Automatic maneuver ON" 3 "Not Used";
VAL_ 939 EBA_MinorFailure 0 "No Alert" 1 "DLC failure alert request";
VAL_ 939 EBAtoBeCalibrated 0 "No warning : ECU operational" 1 "ECU to be calibrated warning";
VAL_ 939 EBAinCalibratingDiag 0 "No ABS or ESP in Calibrating Diagnosis Session warning" 1 "ABS or ESP in Calibrating Diagnosis Session warning";
VAL_ 939 EBA_MajorFailure 0 "No Failure" 1 "Failure";
VAL_ 939 EBA_BoosterPowerCaution 0 "Buzzer off" 1 "Buzzer on";
VAL_ 940 DynamicBrakingDisplay 0 "No dynamic braking display Request" 1 "Dynamic braking display request";
VAL_ 940 APB_BrakePedalRequestDisplay 0 "No brake pedal Request message display" 1 "Brake pedal request message to display" 2 "Not used" 3 "Brake pedal request message re-emission requested";
VAL_ 940 EPB_MalfunctionDisplay 0 "No EPB default" 1 "Minor EPB default" 2 "Major EPB default" 3 "Unavailable";
VAL_ 940 EPB_BindingStatusDisplay 0 "No display request (APB is released)" 1 "APB is tightened" 2 "APB is tightened re-emission" 3 "APB state is unknown" 4 "Not used" 5 "Not used" 6 "Not used" 7 "Unavailable";
VAL_ 940 TakeOffInhibitionWarning 0 "No take off inhibition warning requested" 1 "Take off inhibition warning requested" 2 "Unavailable" 3 "Take off inhibition warning re-emission requested";
VAL_ 940 NotImmobilizedVehicleWarning 0 "No warning Vehicle not immobilized display request" 1 "Warning Vehicle not immobilized display request";
VAL_ 940 EPB_TightenRequestUnavailable 0 "No EPB tightened request unavailable warning requested" 1 "EPB tightened request unavailable warning requested" 2 "Not used" 3 "EPB tightened request unavailable warning re-emission requested";
VAL_ 940 EPB_NotTightenedWarning 0 "No EPB not tightened warning display requested" 1 "EPB not tightened warning display requested";
VAL_ 941 BMS12V_SafetyAlert 0 "No alert" 1 "Low level Alert" 2 "High level Alert" 3 "Not used";
VAL_ 943 ETS_ModeLamp_v3 0 "No Display" 1 "LOCK" 2 "4x2" 3 "4Lo (SNOW)" 4 "While shifting H-L 1" 5 "While shifting H-L 2" 6 "AUTO" 7 "Not Used";
VAL_ 950 DriverSeatFailure 0 "No Failure" 1 "Failure";
VAL_ 950 AD_DrivingSeatPositionState 0 "Not used" 1 "Driving Seat position compatible" 2 "Driving Seat position not compatible" 3 "Unavailable";
VAL_ 955 WarmUpPowerLimitationAlert 0 "No display" 1 "EHC Warm-up state 1" 2 "EHC Warm-up state 2 last chance" 3 "starting delay" 4 "3WC power active limit" 5 "3WC power effective limit" 6 "3WC power active effective but OBM prio" 7 "not used" 8 "not used" 9 "not used" 10 "not used" 11 "not used" 12 "not used" 13 "not used" 14 "not used" 15 "not used";
VAL_ 955 GasLowLevelAlertDispReq_v2 0 "Fuel Level OK" 1 "Fuel Level Low" 2 "Fuel Level Empty" 3 "Not Used";
VAL_ 955 RST_Boost_Activation_MMI 0 "No Display" 1 "Boost Deactivated" 2 "Boost Activated" 3 "Boost Unavailable";
VAL_ 955 IncitativLimitationStepDisplay 0 "Step Green" 1 "Step Orange" 2 "Step Red1" 3 "Step Red2" 4 "Step Red3" 5 "Step Red4" 6 "Not Used" 7 "Not Used";
VAL_ 959 IntelD_SettingStatus 0 "Intel-D OFF status" 1 "Intel-D ON status";
VAL_ 959 IntelD_FailureDisplay 0 "No display" 1 "Temporary failure display" 2 "Permanent failure display" 3 "Not used";
VAL_ 961 DistanceBeforeNextAction 0 "Table Value26873";
VAL_ 961 UnitDistanceBeforeNextAction 0 "meter" 1 "kilometer" 2 "yard" 3 "mile" 4 "feet" 5 "not used" 6 "not used" 7 "not used" 8 "not used" 9 "not used" 10 "not used" 11 "not used" 12 "not used" 13 "not used" 14 "not used" 15 "not used";
VAL_ 962 APA_StatusDisplay 0 "Automatic maneuver OFF" 1 "Automatic maneuver Standby" 2 "Automatic maneuver ON" 3 "Not Used";
VAL_ 967 IVI_ParkAssistVolumeState 0 "Level 0 (off)" 1 "Level 1" 2 "Level 2" 3 "Level 3" 4 "Level 4" 5 "Level 5" 6 "Not used" 7 "Not used";
VAL_ 970 VirtualKeyState 0 "VK Suspended" 1 "VK Resumed";
VAL_ 971 AD_OwnVehicleEffect 0 "No Display" 1 "surrounding detection Not Ready" 2 "surrounding detection Ready" 3 "surrounding detection Active";
VAL_ 971 AD_RightsideLane 0 "No Display" 1 "Normal lane" 2 "Prohibited lane" 3 "Lane to merge to the right lane" 4 "Normal lane to merge into own lane" 5 "Prohibited lane to merge into own lane" 6 "Prohibited to merge to the right lane" 7 "Not used";
VAL_ 971 AD_LeftsideLane 0 "No Display" 1 "Normal lane" 2 "Prohibited lane" 3 "Lane to merge to the left lane" 4 "Normal lane to merge into own lane" 5 "Prohibited lane to merge into own lane" 6 "Prohibited to merge to the left lane" 7 "Not used";
VAL_ 971 AD_VehicleEffect4 0 "No display" 1 "Vehicle without risk" 2 "Vehicle with Mid risk" 3 "Vehicle with High risk";
VAL_ 971 AD_VehicleEffect3 0 "No display" 1 "Vehicle without risk" 2 "Vehicle with Mid risk" 3 "Vehicle with High risk";
VAL_ 971 AD_VehicleEffect2 0 "No display" 1 "Vehicle without risk" 2 "Vehicle with Mid risk" 3 "Vehicle with High risk";
VAL_ 971 AD_VehicleEffect1 0 "No display" 1 "Vehicle without risk" 2 "Vehicle with Mid risk" 3 "Vehicle with High risk";
VAL_ 971 AD_VehicleEffect5 0 "No display" 1 "Vehicle without risk" 2 "Vehicle with Mid risk" 3 "Vehicle with High risk";
VAL_ 971 AD_VehicleStatus2 0 "No Display" 1 "Motor bike detection" 2 "Large vehicle detection" 3 "Normal vehicle detection" 4 "Unknown vehicle detection" 5 "Not Used" 6 "Not Used" 7 "Not Used";
VAL_ 971 AD_VehicleStatus1 0 "No Display" 1 "Motor bike detection" 2 "Large vehicle detection" 3 "Normal vehicle detection" 4 "Unknown vehicle detection" 5 "Not Used" 6 "Not Used" 7 "Not Used";
VAL_ 971 AD_VehicleEffect6 0 "No display" 1 "Vehicle without risk" 2 "Vehicle with Mid risk" 3 "Vehicle with High risk";
VAL_ 971 AD_VehicleStatus4 0 "No Display" 1 "Motor bike detection" 2 "Large vehicle detection" 3 "Normal vehicle detection" 4 "Unknown vehicle detection" 5 "Not Used" 6 "Not Used" 7 "Not Used";
VAL_ 971 AD_VehicleStatus3 0 "No Display" 1 "Motor bike detection" 2 "Large vehicle detection" 3 "Normal vehicle detection" 4 "Unknown vehicle detection" 5 "Not Used" 6 "Not Used" 7 "Not Used";
VAL_ 971 AD_VehicleEffect7 0 "No display" 1 "Vehicle without risk" 2 "Vehicle with Mid risk" 3 "Vehicle with High risk";
VAL_ 971 AD_VehicleStatus6 0 "No Display" 1 "Motor bike detection" 2 "Large vehicle detection" 3 "Normal vehicle detection" 4 "Unknown vehicle detection" 5 "Not Used" 6 "Not Used" 7 "Not Used";
VAL_ 971 AD_VehicleStatus5 0 "No Display" 1 "Motor bike detection" 2 "Large vehicle detection" 3 "Normal vehicle detection" 4 "Unknown vehicle detection" 5 "Not Used" 6 "Not Used" 7 "Not Used";
VAL_ 971 AD_VehicleEffect8 0 "No display" 1 "Vehicle without risk" 2 "Vehicle with Mid risk" 3 "Vehicle with High risk";
VAL_ 971 AD_VehicleStatus8 0 "No Display" 1 "Motor bike detection" 2 "Large vehicle detection" 3 "Normal vehicle detection" 4 "Unknown vehicle detection" 5 "Not Used" 6 "Not Used" 7 "Not Used";
VAL_ 971 AD_VehicleStatus7 0 "No Display" 1 "Motor bike detection" 2 "Large vehicle detection" 3 "Normal vehicle detection" 4 "Unknown vehicle detection" 5 "Not Used" 6 "Not Used" 7 "Not Used";
VAL_ 972 AD_TransitionState 0 "No display" 1 "AD1 to AD2L2 HandsON" 2 "AD2L2 HandsON to AD1" 3 "AD2L2 HandsON to AD2L2 HandsOFF" 4 "AD2L2 HandsON to AD1L3" 5 "AD2L2 HandsOFF to AD2L2 HandsON" 6 "AD2L2 HandsOFF to AD1" 7 "AD2L2 HandsOFF to AD1L3" 8 "AD1L3 to AD2L2 HandsOFF" 9 "AD1L3 to AD2L2 HandsON" 10 "AD1L3 to AD1" 11 "Not used" 12 "Not used" 13 "Not used" 14 "Not used" 15 "Not used";
VAL_ 972 ALC_GapLeftDisplay 0 "No display" 1 "Very Near" 2 "Near" 3 "Far" 4 "Very Far" 5 "Not used" 6 "Not used" 7 "Not used";
VAL_ 972 AD2L2_HOFF_TransitonState 0 "No display" 1 "User activation : OFF to AD2L2_HOFF ON NotOperational" 2 "System activation : ON NotOperational to Operational" 3 "User deactivation : ON NotOperational to OFF" 4 "User deactivation : ON Operational to OFF" 5 "System deactivation lvl1 ON NotOperational to OFF" 6 "System deactivation lvl2 ON NotOperational to OFF" 7 "System deactivation lvl1 ON Operational to ON NotOperational" 8 "System deactivation lvl2 ON Operational to ON NotOperational" 9 "System deactivation lvl1 ON Operational to OFF" 10 "System deactivation lvl2 ON Operational to OFF" 11 "Not used" 12 "Not used" 13 "Not used" 14 "Not used" 15 "Not used" 16 "Not used" 17 "Not used" 18 "Not used" 19 "Not used" 20 "Not used" 21 "Not used" 22 "Not used" 23 "Not used" 24 "Not used" 25 "Not used" 26 "Not used" 27 "Not used" 28 "Not used" 29 "Not used" 30 "Not used" 31 "Not used";
VAL_ 972 ALC_GapRightDisplay 0 "No display" 1 "Very Near" 2 "Near" 3 "Far" 4 "Very Far" 5 "Not used" 6 "Not used" 7 "Not used";
VAL_ 972 AD2L2_HON_TransitonState 0 "No display" 1 "User activation OFF to AD2L2_HON ON NotOperational" 2 "System activation : ON NotOperational to ON Operational" 3 "User deactivation : NotOperational to OFF" 4 "User deactivation : ON Operational to OFF" 5 "System deactivation lvl1: ON NotOperational to OFF" 6 "System deactivation lvl2 : ON NotOperational to OFF" 7 "System deactivation lvl1 : ON Operational to ON NotOperational" 8 "System deactivation lvl2 ON Operational to ON NotOperational" 9 "System deactivation lvl1 ON Operational to OFF" 10 "System deactivation lvl2 ON Operational to OFF" 11 "Not used" 12 "Not used" 13 "Not used" 14 "Not used" 15 "Not used" 16 "Not used" 17 "Not used" 18 "Not used" 19 "Not used" 20 "Not used" 21 "Not used" 22 "Not used" 23 "Not used" 24 "Not used" 25 "Not used" 26 "Not used" 27 "Not used" 28 "Not used" 29 "Not used" 30 "Not used" 31 "Not used";
VAL_ 972 ADL3_MRM 0 "No display" 1 "Alert Eyes on road level1" 2 "Alert Eyes on road level2" 3 "Alert Eyes on road level3" 4 "Alert Eyes on road level4" 5 "Alert Eyes on road level5" 6 "Alert Eyes on road level6" 7 "Alert Eyes on road level7" 8 "Alert Eyes on road level8" 9 "Alert Eyes on road level9" 10 "Alert Eyes on road level10" 11 "Alert Eyes on road level11" 12 "Alert Eyes on road level12" 13 "Alert Eyes on road level13" 14 "Alert Eyes on road level14" 15 "Alert Eyes on road level15" 16 "Alert Eyes not on road level1" 17 "Alert Eyes not on road level2" 18 "Alert Eyes not on road level3" 19 "Alert Eyes not on road level4" 20 "Alert Eyes not on road level5" 21 "Alert Eyes not on road level6" 22 "Alert Eyes not on road level7" 23 "Alert Eyes not on road level8" 24 "Alert Eyes not on road level9" 25 "Alert Eyes not on road level10" 26 "Alert Eyes not on road level11" 27 "Alert Eyes not on road level12" 28 "Alert Eyes not on road level13" 29 "Alert Eyes not on road level14" 30 "Alert Eyes not on road level15" 31 "Alert Eyes not on road level16";
VAL_ 972 ADL3_TransitionState 0 "No display" 1 "User activation : OFF to NotOperational Available wo Longi" 2 "User deactivation : NotOperational Available to OFF" 3 "NotOperational Available wo Longi to NotOperational Available w Longi" 4 "NotOperational Available w Longi to NotOperational Available wo Longi" 5 "NotOperational Available w Longi to OFF" 6 "NotOperational Available w Longi to ON Ready" 7 "ON Ready to NotOperational Available w Longi" 8 "ON Ready to NotOperational Available wo Longi" 9 "ON Ready to OFF" 10 "ON Ready to ON Operational" 11 "ON Operational to ON Ready level1" 12 "ON Operational to ON Ready level2" 13 "ON Operational to NotOperational Available w Longi level1" 14 "ON Operational to NotOperational Available w Longi level2" 15 "ON Operational to NotOperational Available wo Longi level1" 16 "ON Operational to NotOperational Available wo Longi level2" 17 "ON Operational to OFF level1" 18 "ON Operational to OFF level2" 19 "Not used" 20 "Not used" 21 "Not used" 22 "Not used" 23 "Not used" 24 "Not used" 25 "Not used" 26 "Not used" 27 "Not used" 28 "Not used" 29 "Not used" 30 "Not used" 31 "Not used";
VAL_ 972 AD_CutinLeftDisplay 0 "No display" 1 "Motorbike Alert without risk" 2 "Motorbike Alert with risk" 3 "Truck Alert without risk" 4 "Truck Alert with risk" 5 "Car Alert without risk" 6 "Car Alert with risk" 7 "Unknown Alert without risk" 8 "Unknown Alert with risk" 9 "Not used" 10 "Not used" 11 "Not used" 12 "Not used" 13 "Not used" 14 "Not used" 15 "Not used";
VAL_ 972 ALC_Direction 0 "Right Heading Lane Change" 1 "Left Heading Lane Change";
VAL_ 972 AD_CancelReasonRER 0 "No request" 1 "Reemission request";
VAL_ 972 AD_CutinRightDisplay 0 "No display" 1 "Motorbike Alert without risk" 2 "Motorbike Alert with risk" 3 "Truck Alert without risk" 4 "Truck Alert with risk" 5 "Car Alert without risk" 6 "Car Alert with risk" 7 "Unknown Alert without risk" 8 "Unknown Alert with risk" 9 "Not used" 10 "Not used" 11 "Not used" 12 "Not used" 13 "Not used" 14 "Not used" 15 "Not used";
VAL_ 976 SubAD_ADL3_MRM 0 "No display" 1 "Alert Eyes on road level1" 2 "Alert Eyes on road level2" 3 "Alert Eyes on road level3" 4 "Alert Eyes on road level4" 5 "Alert Eyes on road level5" 6 "Alert Eyes on road level6" 7 "Alert Eyes on road level7" 8 "Alert Eyes on road level8" 9 "Alert Eyes on road level9" 10 "Alert Eyes on road level10" 11 "Alert Eyes on road level11" 12 "Alert Eyes on road level12" 13 "Alert Eyes on road level13" 14 "Alert Eyes on road level14" 15 "Alert Eyes on road level15" 16 "Alert Eyes not on road level1" 17 "Alert Eyes not on road level2" 18 "Alert Eyes not on road level3" 19 "Alert Eyes not on road level4" 20 "Alert Eyes not on road level5" 21 "Alert Eyes not on road level6" 22 "Alert Eyes not on road level7" 23 "Alert Eyes not on road level8" 24 "Alert Eyes not on road level9" 25 "Alert Eyes not on road level10" 26 "Alert Eyes not on road level11" 27 "Alert Eyes not on road level12" 28 "Alert Eyes not on road level13" 29 "Alert Eyes not on road level14" 30 "Alert Eyes not on road level15" 31 "Alert Eyes not on road level16";
VAL_ 976 SubAD_AD2_HandsOff_MRM 0 "No display" 1 "Alert Eyes on road level1" 2 "Alert Eyes on road level2" 3 "Alert Eyes on road level3" 4 "Alert Eyes on road level4" 5 "Alert Eyes on road level5" 6 "Alert Eyes on road level6" 7 "Alert Eyes on road level7" 8 "Alert Eyes on road level8" 9 "Alert Eyes on road level9" 10 "Alert Eyes on road level10" 11 "Alert Eyes on road level11" 12 "Alert Eyes on road level12" 13 "Alert Eyes on road level13" 14 "Alert Eyes on road level14" 15 "Alert Eyes on road level15" 16 "Alert Eyes not on road level1" 17 "Alert Eyes not on road level2" 18 "Alert Eyes not on road level3" 19 "Alert Eyes not on road level4" 20 "Alert Eyes not on road level5" 21 "Alert Eyes not on road level6" 22 "Alert Eyes not on road level7" 23 "Alert Eyes not on road level8" 24 "Alert Eyes not on road level9" 25 "Alert Eyes not on road level10" 26 "Alert Eyes not on road level11" 27 "Alert Eyes not on road level12" 28 "Alert Eyes not on road level13" 29 "Alert Eyes not on road level14" 30 "Alert Eyes not on road level15" 31 "Alert Eyes not on road level16";
VAL_ 976 SubAD_ReflectiveFocus_Status 0 "No request" 1 "MRM request" 2 "TD request" 3 "MRM and TD request";
VAL_ 976 SubAD_AD_MRM_PhaseCounter 0 "No display";
VAL_ 977 LiB_RLY_OFF_Inhibition 0 "LiB RLY OFF permission" 1 "LiB RLY OFF inhibition";
VAL_ 986 ALC_Marker 0 "No display" 1 "Right NotOperational" 2 "Right Waiting wo GapConfirmation" 3 "Right Waiting w GapConfirmation" 4 "Right Operational wo GapConfirmation" 5 "Right Operational w GapConfirmation" 6 "Left NotOperational" 7 "Left Waiting wo GapConfirmation" 8 "Left Waiting w GapConfirmation" 9 "Left Operational wo GapConfirmation" 10 "Left Operational w GapConfirmation" 11 "Not used" 12 "Not used" 13 "Not used" 14 "Not used" 15 "Not used";
VAL_ 986 ALC_Request 0 "No request" 1 "Initial User Request" 2 "Initial System Request" 3 "Second User request" 4 "Second System request" 5 "Not used" 6 "Not used" 7 "Not used";
VAL_ 986 ALC_Distance 0 "No Display";
VAL_ 986 AD2_HandsOff_MRM 0 "No display" 1 "Alert Eyes on road level1" 2 "Alert Eyes on road level2" 3 "Alert Eyes on road level3" 4 "Alert Eyes on road level4" 5 "Alert Eyes on road level5" 6 "Alert Eyes on road level6" 7 "Alert Eyes on road level7" 8 "Alert Eyes on road level8" 9 "Alert Eyes on road level9" 10 "Alert Eyes on road level10" 11 "Alert Eyes on road level11" 12 "Alert Eyes on road level12" 13 "Alert Eyes on road level13" 14 "Alert Eyes on road level14" 15 "Alert Eyes on road level15" 16 "Alert Eyes not on road level1" 17 "Alert Eyes not on road level2" 18 "Alert Eyes not on road level3" 19 "Alert Eyes not on road level4" 20 "Alert Eyes not on road level5" 21 "Alert Eyes not on road level6" 22 "Alert Eyes not on road level7" 23 "Alert Eyes not on road level8" 24 "Alert Eyes not on road level9" 25 "Alert Eyes not on road level10" 26 "Alert Eyes not on road level11" 27 "Alert Eyes not on road level12" 28 "Alert Eyes not on road level13" 29 "Alert Eyes not on road level14" 30 "Alert Eyes not on road level15" 31 "Alert Eyes not on road level16";
VAL_ 986 AD_AvailabilityLevel 0 "No display" 1 "AD Availability Level1 (dn)" 2 "AD Availability Level2 (up/dn)" 3 "AD Availability Level3" 4 "AD Availability Level4" 5 "AD Availability Level5" 6 "AD Availability Level6 (up/dn)" 7 "AD Availability Level7 (up/dn)" 8 "AD Availability Level8 (dn)" 9 "AD Availability Level9 (dn)" 10 "AD Availability Level10 (up/dn)" 11 "AD Availability Level11 (up)" 12 "Not used" 13 "Not used" 14 "Not used" 15 "Not used";
VAL_ 986 AD_MRM_PhaseCounter 0 "No display";
VAL_ 986 AD_RealisticScreenEffect 0 "No Effect" 1 "Effect1" 2 "Effect2" 3 "Effect3" 4 "Effect4" 5 "Effect5" 6 "Not Used" 7 "Not Used";
VAL_ 996 SteeringPositionMemoRequest 0 "No steering position memorization request" 1 "Steering position M1 memorization request" 2 "Steering position M2 memorization request" 3 "Steering position M3 memorization request" 4 "Steering position M4 memorization request" 5 "Steering position M5 memorization request" 6 "Steering position M6 memorization request" 7 "Not used";
VAL_ 996 SteeringPositionMemoRecall 0 "No Steering memorized position recall request" 1 "Steering M1 memorized position recall request" 2 "Steering M2 memorized position recall request" 3 "Steering M3 memorized position recall request" 4 "Steering M4 memorized position recall request" 5 "Steering M5 memorized position recall request" 6 "Steering M6 memorized position recall request" 7 "Reset request";
VAL_ 996 DSMU_EasyAccessActivateRequest 0 "No Request" 1 "Easy Access Request" 2 "Easy Entry Request" 3 "Not used";
VAL_ 996 DriverSeatStatus 0 "Operational" 1 "In Failure Mode" 2 "Reserved" 3 "Unavailable";
VAL_ 996 SteeringEasyAccessState 0 "Easy Access Activation State" 1 "Easy Access Deactivation State";
VAL_ 996 MemoryGuidanceDisplayRequest 0 "No Display Request" 1 "Memory Guidance Display Request" 2 "Memory Complete Address SW 1 Display Request" 3 "Memory Complete Address SW 2 Display Request";
VAL_ 996 DSMU_RefuseToSleep 0 "reserved" 1 "DSMU refuse to sleep" 2 "DSMU ready to sleep" 3 "reserved";
VAL_ 996 DSMU_SteeringAdjustStopRequest 0 "No Request" 1 "Stop Activation Request";
VAL_ 996 DriverMassageProgramState_v3 0 "Massage is not running" 1 "Program massage 1 is runnning" 2 "Program massage 2 is runnning" 3 "Program massage 3 is runnning" 4 "Program massage 4 is runnning" 5 "Program massage 5 is runnning" 6 "Program massage 6 is runnning" 7 "Program massage 7 is runnning" 8 "Program massage 8 is runnning" 9 "Program massage 9 is runnning" 10 "Program massage 10 is runnning" 11 "Program massage 11 is runnning" 12 "Program massage 12 is runnning" 13 "Program massage 13 is runnning" 14 "Program massage 14 is runnning" 15 "Not used";
VAL_ 997 SCCM_Status 0 "Operational" 1 "movement in progress" 2 "Reserved" 3 "position note saved" 4 "Failure" 5 "Unavailable" 6 "Not used" 7 "Not used";
VAL_ 997 SCCM_RefuseToSleep 0 "reserved" 1 "SCCM refuse to sleep" 2 "SCCM ready to sleep" 3 "reserved";
VAL_ 997 STR_AdjustStatus 0 "No Request" 1 "Stop Activation Request";
VAL_ 999 ADBCautionDisplay 0 "No Need to display ADB caution" 1 "Need to display ADB Caution";
VAL_ 999 V2_WakeUpType 0 "Full Wake-Up Mode" 1 "Selective Wake-Up Mode 1" 2 "Selective Wake-Up Mode 2" 3 "Selective Wake-Up Mode 3" 4 "Selective Wake-Up Mode 4" 5 "Selective Wake-Up Mode 5" 6 "Selective Wake-Up Mode 6" 7 "Unavailable";
VAL_ 999 BCM_LockAndCloseAuthentState 0 "No Request" 1 "Lock&Close Refused due to Door condition" 2 "Lock&Close Refused due to Authent Failure" 3 "Lock&Close Authorized";
VAL_ 999 V2_WakeUpSleepCommand 0 "Go to Sleep" 1 "reserved" 2 "reserved" 3 "WakeUp";
VAL_ 999 BCM_SteeringCommandK 0 "button released" 1 "button pressed";
VAL_ 999 BCM_SteeringCommandJ 0 "button released" 1 "button pressed";
VAL_ 999 BCM_SteeringCommandI 0 "button released" 1 "button pressed";
VAL_ 999 BCM_SteeringCommandH 0 "button released" 1 "button pressed";
VAL_ 999 AHLCautionDisplay 0 "No need to display  AHL caution" 1 "Need to display  AHL caution";
VAL_ 999 BCM_SteeringCommandO 0 "button released" 1 "button pressed";
VAL_ 999 BCM_SteeringCommandN 0 "button released" 1 "button pressed";
VAL_ 999 BCM_SteeringCommandM 0 "button released" 1 "button pressed";
VAL_ 999 BCM_SteeringCommandL 0 "button released" 1 "button pressed";
VAL_ 999 BCM_SteeringPhoneEndCommand 0 "button released" 1 "button pressed";
VAL_ 999 LightSwitchOperationFdbk_display 0 "No display" 1 "LAMP OFF succeed by Stable tail Switch" 2 "LAMP OFF refused by Stable tail Switch" 3 "Operation refused due to AD" 4 "LAMP OFF guide for Unstable tail Switch" 5 "Tail mode condition NOK" 6 "Auto mode activated by System" 7 "Auto mode activated by User" 8 "Auto mode deactivated by User" 9 "Tail mode guide for Unstable tail Switch" 10 "LAMP OFF mode condition NOK" 11 "LAMP OFF succeed by Unstable tail switch" 12 "Reserved" 13 "Reserved" 14 "Reserved" 15 "Reserved";
VAL_ 999 BCM_SteeringCommandG 0 "button released" 1 "button pressed";
VAL_ 999 BCM_SteeringCommandP 0 "button released" 1 "button pressed";
VAL_ 1000 RKE_ID_DetectStatus 0 "No existing" 1 "User 1" 2 "User 2" 3 "User 3" 4 "User 4" 5 "Not Used" 6 "Not Used" 7 "Not Used";
VAL_ 1000 APPRUN_ActivationState 0 "Approach Unlock is deactivated (initial value)" 1 "Approach Unlock is activated";
VAL_ 1000 WAL_ActivationState 0 "Walk Away Locking is deactivated (initial value)" 1 "Walk Away Locking is activated";
VAL_ 1000 TrunkCancelSwitchState 0 "Trunk Cancel Switch OFF" 1 "Trunk Cancel Switch ON";
VAL_ 1000 IKeyAccessActivationState 0 "iKey Access is Desactivated" 1 "iKey Access is Activated";
VAL_ 1000 RearZonePollingResult 0 "No search" 1 "Searching" 2 "No Key Detect" 3 "Key Detect";
VAL_ 1000 UserIdent_Ikey 0 "No Ident" 1 "ID1" 2 "ID2" 3 "ID3" 4 "ID4" 5 "VK_ID1" 6 "VK_ID2" 7 "VK_ID3" 8 "VK_ID4" 9 "VK_ID5" 10 "VK_ID6" 11 "Not used" 12 "Not used" 13 "Not used" 14 "Not used" 15 "Not used";
VAL_ 1000 VehicleInsideKeyIdentResult 0 "No search" 1 "Searching" 2 "No Ident" 3 "Ident";
VAL_ 1000 OutsideZoneKeyIdentResult 0 "No search" 1 "Searching" 2 "No Ident" 3 "Ident";
VAL_ 1000 OutsideZonePollingResult 0 "No search" 1 "Searching" 2 "No Key Detect" 3 "Key Detect";
VAL_ 1001 PassengerMassageProgramState_v3 0 "Massage is not running" 1 "Program massage 1 is runnning" 2 "Program massage 2 is runnning" 3 "Program massage 3 is runnning" 4 "Program massage 4 is runnning" 5 "Program massage 5 is runnning" 6 "Program massage 6 is runnning" 7 "Program massage 7 is runnning" 8 "Program massage 8 is runnning" 9 "Program massage 9 is runnning" 10 "Program massage 10 is runnning" 11 "Program massage 11 is runnning" 12 "Program massage 12 is runnning" 13 "Program massage 13 is runnning" 14 "Program massage 14 is runnning" 15 "Not used";
VAL_ 1003 AD_OwnVehicle_BrakeLamp 0 "No display" 1 "Brake Lamp On";
VAL_ 1003 SeatBeltAlert_Request 0 "No vibration" 1 "vibration pattern1" 2 "vibration pattern2" 3 "vibration pattern3" 4 "vibration pattern4" 5 "vibration pattern5" 6 "Not used" 7 "Not used";
VAL_ 1003 AD_OwnVehicle_TurnSignal 0 "No Display" 1 "Left turn signal ON" 2 "Right turn signal ON" 3 "Left and Right turn signals ON";
VAL_ 1003 AD_LeadingVehicleStatus 0 "No Display" 1 "Far Motor bike" 2 "Near Motor bike" 3 "Far Truck" 4 "Near Truck" 5 "Far Car" 6 "Near Car" 7 "Far Unknown vehicle" 8 "Near Unknown vehicle" 9 "Reserved" 10 "Reserved" 11 "Reserved" 12 "Reserved" 13 "Reserved" 14 "Reserved" 15 "Reserved";
VAL_ 1003 AD_DivideLineStatus 0 "No Display" 1 "AD condition Not fulfilled" 2 "AD condition fulfilled" 3 "AD continuous condition fulfilled";
VAL_ 1003 AD_SteeringWheelTakeOverAlert 0 "No Alert" 1 "Alert level1" 2 "Alert level2" 3 "Alert level3" 4 "Alert level4" 5 "Alert level5" 6 "Alert level6" 7 "Alert level7";
VAL_ 1003 AD_StatusDisplay 0 "No display" 1 "AD2L2 HON NotOperational" 2 "AD2L2 HON Operational" 3 "AD2L2 HOFF NotOperational" 4 "AD2L2 HOFF Operational" 5 "AD1L3 NotOperational Available wo Longi" 6 "AD1L3 NotOperational Available w Longi" 7 "AD1L3 Ready" 8 "AD1L3 Operational" 9 "AD_TemporaryFailure" 10 "AD_PermanentFailure" 11 "Not used" 12 "Not used" 13 "Not used" 14 "Not used" 15 "Not used";
VAL_ 1003 ALC_HandsRequest 0 "Hands NotRequested" 1 "Hands Requested without risk" 2 "Hands Requested with risk" 3 "Not used";
VAL_ 1003 ALC_Warning 0 "No display" 1 "Warning Level1 (low risk)" 2 "Warning Level2 (high risk)" 3 "Not used";
VAL_ 1003 ALC_StatusDisplay 0 "No display" 1 "Not Operational" 2 "Operational waiting HandsON" 3 "Operational waiting HandsOFF" 4 "Operational Active HandsON" 5 "Operational Active HandsOFF" 6 "Operational Standby" 7 "Not used";
VAL_ 1003 AD_FunctionalLimit 0 "Limit not reached" 1 "Limit reached without risk" 2 "Limit reached with risk" 3 "Not used";
VAL_ 1003 AD2_Routeguide 0 "No Display" 1 "ON NotOperational" 2 "ON Operational HandsON" 3 "ON Operational HandsOFF" 4 "Not used" 5 "Not used" 6 "Not used" 7 "Reserved";
VAL_ 1012 ECALL_StateDisplay_V4 0 "No message" 1 "Not used" 2 "Not used" 3 "Manual Ecall - push to cancel" 4 "Manual Ecall launch" 5 "Ecall auto launch" 6 "Manual Ecall failure" 7 "Ecall launch cancelled" 8 "Ecall on going" 9 "Voice communication on going - MSD not sent" 10 "Voice communication on going - MSD sent" 11 "Voice call failure" 12 "End of voice communication" 13 "Incoming call" 14 "Not used" 15 "Ecall malfunction";
VAL_ 1022 PSB_RefuseToSleep 0 "reserved" 1 "PSB refuse to sleep" 2 "PSB ready to sleep" 3 "reserved";
VAL_ 1022 SeatBeltAlert_Status 0 "No activation" 1 "Activation";
VAL_ 1022 SeatBeltAlert_Failure 0 "No Failure" 1 "Failure";
VAL_ 1028 VSPSoundActivationState 0 "Not Activated" 1 "Activated";
VAL_ 1028 VSPsoundChoiceActivationState 0 "VSP Choice 1" 1 "VSP Choice 2" 2 "VSP Choice 3" 3 "VSP Choice 4" 4 "VSP Choice 5" 5 "Not used" 6 "Not used" 7 "Not used";
VAL_ 1045 FaceID_temporary_Failure 0 "No display" 1 "Camera temporary OBSTRUCTION" 2 "Camera temporary DIRTY" 3 "Camera temporary FACE MASKED/Nose masked" 4 "Camera temporary EYES MASKED" 5 "Camera temporary MASKED BY STEERING WHEEL" 6 "Camera temporary Part of face" 7 "Camera temporary Too large face angle" 8 "Camera temporary Eye closed" 9 "Camera temporary Not alive" 10 "Camera temporary Poor light condition" 11 "Camera temporary Bad face" 12 "Camera temporary No face detected" 13 "Camera temporary Too large/small face" 14 "Not used" 15 "Unavailable value";
VAL_ 1045 FaceID_RegistrationState_IVI 0 "Initial Value" 1 "Start" 2 "Registering" 3 "Complete" 4 "Stop (Cancel)" 5 "Time Out" 6 "Error" 7 "Non P gear" 8 "Already Registered" 9 "Not used" 10 "Not used" 11 "Not used" 12 "Not used" 13 "Not used" 14 "Not used" 15 "Not used";
VAL_ 1045 FaceID_permanent_Failure 0 "No failure (default)" 1 "failure" 2 "Reserved" 3 "Unavailable value";
VAL_ 1045 FaceID_RecognitionState_IVI 0 "Initial Value" 1 "Start/Recognizing" 2 "Complete" 3 "Stop (Cancel)" 4 "Time Out" 5 "Error" 6 "Non P gear" 7 "Not used";
VAL_ 1047 APA_Warning 0 "No Alert" 1 "Alert";
VAL_ 1048 APA_Warning2 0 "No Alert" 1 "Alert";
VAL_ 1055 LowSOCTextRechargeAlertDisplay 0 "Charge Alert is NOT Displayed" 1 "Charge Alert is Displayed";
VAL_ 1058 SpeedLimiterOSPDisplayRequest 0 "No request" 1 "Set SL display request" 2 "Re emission Request" 3 "Not used";
VAL_ 1064 MaxElecPowerStatusDisplay 0 "No display request" 1 "Nominal display request" 2 "Limit exceed display request" 3 "Not used";
VAL_ 1064 MinElecPowerStatusDisplay 0 "No display request" 1 "Nominal display request" 2 "Limit exceed display request" 3 "Not used";
VAL_ 1065 HVBatteryLow 0 "No HV Battery Low Display Requested" 1 "HV Battery Low Display Requested";
VAL_ 1065 ChargingPlugConnected_v2 0 "No display request (Charging Plug is NOT Connected)" 1 "Charging Plug is Connected" 2 "PWT Start impossible - Plug Connected" 3 "Unavailable value";
VAL_ 1065 AuxEnergyFlow 0 "No power" 1 "Battery to accessory - Low power" 2 "Battery  to accessory - High power" 3 "Not used";
VAL_ 1065 AllWheelDriveFlag 0 "2WD" 1 "AWD";
VAL_ 1065 PedalOperationErrorFunctionState 0 "No activated" 1 "System activated" 2 "Not used" 3 "Unavailable value";
VAL_ 1065 PedalOperationErrorWarnRequest 0 "No request" 1 "Warning request";
VAL_ 1065 TireRotatingDirection 0 "Stop" 1 "Forward direction" 2 "Back direction" 3 "Unavailable value";
VAL_ 1066 HVbatteryEmpty 0 "No alert" 1 "Alert";
VAL_ 1066 ReadyLampStatus 0 "LED OFF" 1 "LED ON" 2 "PWT Starting Information" 3 "Unavailable value";
VAL_ 1066 EV_LampRequest 0 "No Display request (Turn OFF - ICE engine is ON)" 1 "Turn ON - vehicle is in EV mode";
VAL_ 1066 HVbatteryChargeType_v2 0 "No charge" 1 "Normal charge" 2 "Accelerated charge" 3 "Fast charge" 4 "Quick charge" 5 "Ultra fast" 6 "V2H" 7 "V2G";
VAL_ 1066 RegenBrakingLevelDisplay 0 "Regenerative braking level 0" 1 "Regenerative braking level 1" 2 "Regenerative braking level 2" 3 "Regenerative braking level 3" 4 "Regenerative braking level 4" 5 "Regenerative braking level 5" 6 "Not Used" 7 "No display";
VAL_ 1066 ParkPositionRequestedDisplay 0 "Not used" 1 "No alert 'Set Park for Charge'" 2 "Alert 'Set Park for Charge'" 3 "Unavailable";
VAL_ 1068 HEV_ElecMotorFailureDisplay 0 "No Alert" 1 "Alert";
VAL_ 1068 HEV_ChargeFailureDisplay 0 "No Alert" 1 "Alert";
VAL_ 1068 HEV_MajorElecFailureDisplay 0 "No Alert" 1 "Alert";
VAL_ 1068 ChargingSoundRequest 0 "No request" 1 "Play charging plug sound request" 2 "Play Admit to charge battery sound request" 3 "Play Unlock charging plug sound request";
VAL_ 1068 EngineMotorEnergyFlow_v2 0 "No Power" 1 "Engine to Motor - Low Power" 2 "Engine to Motor - Mid Power" 3 "Engine to Motor - High Power" 4 "Motor to Engine - Low Power" 5 "Motor to Engine - Mid Power" 6 "Motor to Engine - High Power" 7 "Not used";
VAL_ 1068 HVchargerStatus 0 "No HV charge" 1 "HV battery charge" 2 "HV consumers charge" 3 "Not used";
VAL_ 1068 EngineWheelEnergyFlow_v2 0 "No Power" 1 "Engine to Wheel- Low Power" 2 "Engine to Wheel - Mid Power" 3 "Engine to Wheel - High Power" 4 "Wheel to Engine - Low Power" 5 "Wheel to Engine - Mid Power" 6 "Wheel to Engine - High Power" 7 "Not used";
VAL_ 1068 AuxChargePlugEnergyFlow 0 "No Power" 1 "Charge Plug to Auxillary" 2 "Auxillary to Charge Plug" 3 "Unavailable";
VAL_ 1068 BatteryMotorEnergyFlow_v2 0 "No Power" 1 "Battery to Motor - Low Power" 2 "Battery to Motor - Mid Power" 3 "Battery to Motor - High Power" 4 "Motor to Battery - Low Power" 5 "Motor to Battery - Mid Power" 6 "Motor to Battery - High Power" 7 "Not used";
VAL_ 1068 BatteryRearMotorEnergyFlow 0 "No Power" 1 "Battery to Rear Motor - Low Power" 2 "Battery to Rear Motor - Mid Power" 3 "Battery to Rear Motor - High Power" 4 "Rear Motor to Battery - Low Power" 5 "Rear Motor to Battery - Mid Power" 6 "Rear Motor to Battery - High Power" 7 "Unavailable";
VAL_ 1068 BatteryChargePlugEnergyFlow 0 "No Power" 1 "Charge Plug to Battery" 2 "Battery to Charge Plug" 3 "Unavailable";
VAL_ 1068 ChargingStatusDisplay_v2 0 "No charge" 1 "Waiting a planned charge" 2 "Ended charge" 3 "Charge in progress" 4 "Charge failure" 5 "Waiting for current charge" 6 "Energy Flap opened: welcome MMI" 7 "Stopped charge(SOC is not full)" 8 "Charging is continue with full SOC" 9 "V2G" 10 "V2L Outside" 11 "V2G in discharge" 12 "V2G in charge" 13 "Not used" 14 "Not used" 15 "Not used";
VAL_ 1068 HybridTractionChargeModeAvail 0 "Available" 1 "Not available";
VAL_ 1068 HybridTractionSaveModeAvail 0 "Available" 1 "Not available";
VAL_ 1068 HybridTractionModeCursorDisplay 0 "No display" 1 "EV mode selected" 2 "Auto mode selected" 3 "Sport mode selected" 4 "Charge Battery selected" 5 "Save Battery level selected" 6 "Not Used" 7 "Not Used";
VAL_ 1070 EcoNavStatusDisplay 0 "Econav function not active" 1 "Econav function active";
VAL_ 1076 BadgeBatteryLow 0 " No Display request (badge battery OK)" 1 "badge battery low";
VAL_ 1076 SteeringLockFailure 0 "no steering lock  failure" 1 "steering column locking failure" 2 "steering colum unlocking failure" 3 "reserved";
VAL_ 1076 SwitchOffSESDisturbers 0 "No request" 1 "Disturbers switch off requested";
VAL_ 1081 TCS_DeactivationState 0 "TCS not deactivated" 1 "TCS deactivated";
VAL_ 1081 SSA_DeactiveDispReq 0 "No request" 1 "Display request";
VAL_ 1081 SideWindAssistActivationDispReq 0 "No display" 1 "Display Side Wind Assist";
VAL_ 1081 HDC_ActivationRefusedDisplay 0 "HDC_ActivationRefused not displayed" 1 "HDC_ActivationRefused displayed";
VAL_ 1081 TCS_DeactivationStateToMETER 0 "No display" 1 "TCS ASR is activated text on and no telltale display" 2 "TCS ASR is deactivated text on and telltale display" 3 "TCS ASR deactivated no text message and telltale display";
VAL_ 1081 BrakePadWear_byEBAM 0 "no fault" 1 "short circuit 12 V" 2 "pad to be changed" 3 "Unavailable";
VAL_ 1081 ExtendedGripModeDisplayRequest 0 "No display ExtendedGrip not available" 1 "Mode 1" 2 "Mode 2" 3 "Mode 3" 4 "Mode 4" 5 "Mode 5" 6 "Not Used" 7 "Not Used";
VAL_ 1082 VPA_PBD_Request 0 "No request" 1 "Full close request" 2 "Full open request" 3 "Latch release request" 4 "Stop request" 5 "Not Used" 6 "Not Used" 7 "Not Used";
VAL_ 1087 H2DeratingFCTemp 0 "No Display" 1 "Temperature of Fuel cell too high" 2 "Temperature of Fuel cell too low" 3 "Not Used";
VAL_ 1087 H2LeakDetection 0 "No Display" 1 "Light H2 Leak" 2 "Heavy H2 Leak" 3 "Not Used";
VAL_ 1087 H2LidOpened 0 "No Display" 1 "Lid Opened Display";
VAL_ 1087 H2EndOfRefueling 0 "No Display" 1 "End of Refueling Display";
VAL_ 1087 RefuelingInProgress 0 "No Display" 1 "Refueling In Progress";
VAL_ 1087 H2LowLevelAlert 0 "No Display" 1 "Alert Display";
VAL_ 1087 FCFailure 0 "No Display" 1 "Defect fuel cell" 2 "System Failure H2" 3 "Not Used";
VAL_ 1087 V2LButton_State 0 "No Display" 1 "V2L Button OFF" 2 "V2L Button ON" 3 "Not Used";
VAL_ 1087 FCOffButton_State 0 "No Display" 1 "Fuel Cell OFF" 2 "Fuel Cell ON" 3 "Not Used";
VAL_ 1087 FCAvailabilityState 0 "No Display" 1 "Fuel Cell Activated" 2 "Fuel Cell Not Activated" 3 "Not Used";
VAL_ 1087 FCAvailability 0 "No Display" 1 "Fuel Cell Activated" 2 "Fuel Cell Not Activated" 3 "Not Used";
VAL_ 1099 AT_BrakeAvailability 0 "Brake range not available" 1 "Brake range available" 2 "not used" 3 "Unavailable";
VAL_ 1099 RST_LaunchControlReadyMMI 0 "No display" 1 "Launch Control Not Active" 2 "Display Launch Control Active" 3 "reserved";
VAL_ 1099 AT_LoadAvailability 0 "Load range not available" 1 "Load range available" 2 "not used" 3 "Unavailable";
VAL_ 1099 AT_DriverRequestWithoutBrake 0 "No driver request without brake pedal pressed" 1 "Driver request without brake pedal pressed";
VAL_ 1099 AT_DriverRequest 0 "No request" 1 "P requested" 2 "R requested" 3 "N requested" 4 "D requested" 5 "M requested" 6 "+ requested" 7 "- requested" 8 "B requested" 9 "L requested" 10 "Not used" 11 "Not used" 12 "Not used" 13 "Not used" 14 "Not used" 15 "Unavailable value";
VAL_ 1099 AT_DriveAvailability_v2 0 "No display request" 1 "Display request";
VAL_ 1099 AT_PressBrakePedalRequest 0 "No press brake pedal request" 1 "Push brake pedal requested (Shiftlock for Automatic gear or cranking with transmission range engaged for robotized gear)";
VAL_ 1099 AT_ParkAvailability 0 "No display request" 1 "Display request" 2 "Not used" 3 "Unavailable";
VAL_ 1099 AT_NeutralAvailability 0 "No display request" 1 "Display request" 2 "Not used" 3 "Unavailable";
VAL_ 1099 AT_ManualAvailability 0 "No display request" 1 "Display request" 2 "Not used" 3 "Unavailable";
VAL_ 1099 AT_GearShiftRefused 0 "gear shift accepted" 1 "gear shift refused";
VAL_ 1099 ATCVT_CheckWarning 0 "No AT/CVT default warning" 1 "AT/CVT default warning";
VAL_ 1099 AT_TipDownAvailability 0 "No display request" 1 "Display request" 2 "Not used" 3 "Unavailable";
VAL_ 1099 AT_ReverseAvailability 0 "No display request" 1 "Display request" 2 "Not used" 3 "Unavailable";
VAL_ 1099 ATCVT_RangeIndicationExtended 0 "OFF" 1 "P range" 2 "R range" 3 "N range" 4 "D range" 5 "S range" 6 "L range" 7 "B range" 8 "1st range" 9 "2nd range" 10 "3rd range" 11 "4th range" 12 "5th range" 13 "6th range" 14 "7th range" 15 "8th range" 16 "9th range" 17 "10th range" 18 "Not used" 19 "Not used" 20 "M1st" 21 "M2nd" 22 "M3rd" 23 "M4th" 24 "M5th" 25 "M6th" 26 "M7th" 27 "M8th" 28 "M9th" 29 "M10th" 30 "Not used" 31 "Not used" 32 "Auto 1st" 33 "Auto 2nd" 34 "Auto 3rd" 35 "Auto 4th" 36 "Auto 5th" 37 "Auto 6th" 38 "Auto 7th" 39 "Auto 8th" 40 "Auto 9th" 41 "Auto 10th" 42 "Not used" 43 "Not used" 44 "Not used" 45 "Not used" 46 "Not used" 47 "Not used" 48 "Not used" 49 "Not used" 50 "Not used" 51 "Not used" 52 "Not used" 53 "Not used" 54 "Not used" 55 "Not used" 56 "Not used" 57 "Not used" 58 "Not used" 59 "Not used" 60 "Not used" 61 "Not used" 62 "Not used" 63 "Not used";
VAL_ 1099 ATCVT_HiTempWarning 0 "No AT/CVT High temp warning" 1 "AT/CVT high temp warning";
VAL_ 1099 AT_TipUpAvailability 0 "No display request" 1 "Display request" 2 "Not used" 3 "Unavailable";
VAL_ 1099 AccelReqImpossible 0 "No alert" 1 "Alert";
VAL_ 1099 NeutralHoldModeMessage 0 "No request" 1 "Neutral hold mode is ready" 2 "Neutral hold mode is in progress" 3 "Neutral hold message 3" 4 "Neutral hold message 4" 5 "Neutral hold message 5" 6 "Neutral hold message 6" 7 "Neutral hold message 7";
VAL_ 1100 ATwithPark_OpenDoorWarning 0 "No open door warning" 1 "AT_open door warning";
VAL_ 1100 ATwithoutPark_OpenDoorWarning 0 "No open door warning" 1 "AT_open door warning";
VAL_ 1100 AT_Parkfailure 0 "No park failure" 1 "Park Failure";
VAL_ 1100 AT_Level2FailureDisplayRequest 0 "Unavailable" 1 "No warning" 2 "AT  major failure warning (Level 2)" 3 "Protection mode activated";
VAL_ 1100 ShBW_WarningMessage 0 "No request" 1 "Parking Brake request" 2 "Confirm Lever position" 3 "Not used";
VAL_ 1101 StopLampFailureDisplay 0 "Stop lamp failure display not requested" 1 "Stop lamp failure display requested";
VAL_ 1101 ClutchSwitchFaultDisplay 0 "No clutch switch failure display request" 1 "Clutch switch failure display requested";
VAL_ 1101 ChildLockStateDisplay 0 "Unavailable" 1 "Child Lock activated" 2 "Child Lock not activated" 3 "Not Used";
VAL_ 1101 RearWindowLiftStateDisplay 0 "Unavailable" 1 "Rear Window Lift activated" 2 "Rear Window Lift not activated" 3 "Not Used";
VAL_ 1101 FlashingIndicatorStatusDisplay 0 "left and right flashing indicators OFF" 1 "left flashing indicator ON and right flashing indicator OFF" 2 "left flashing indicator OFF and right flashing indicator ON" 3 "left flashing indicator ON and right flashing indicator ON" 4 "Not used" 5 "Not used" 6 "Not used" 7 "Unavailable";
VAL_ 1101 OldPressureRL_twin 0 "Pressure up to date" 1 "Pressure not up to date";
VAL_ 1101 OldPressureRR_twin 0 "Pressure up to date" 1 "Pressure not up to date";
VAL_ 1101 WheelStateRL_twin 0 "Pressure ok and no failure" 1 "Failure" 2 "Underinflation" 3 "Underinflation and failure" 4 "Puncture" 5 "Puncture and failure" 6 "Puncture and underinflation" 7 "Puncture and underinflation and failure";
VAL_ 1101 WheelStateRR_twin 0 "Pressure ok and no failure" 1 "Failure" 2 "Underinflation" 3 "Underinflation and failure" 4 "Puncture" 5 "Puncture and failure" 6 "Puncture and underinflation" 7 "Puncture and underinflation and failure";
VAL_ 1102 AutoLockActivationState 0 "Auto Lock is not activated" 1 "Auto Lock with Speed is activated" 2 "Auto Lock with Park-out is activated" 3 "Not used";
VAL_ 1102 AutoLightSensitivityStatus 0 "Configuration 1 activated" 1 "Configuration 2 activated" 2 "Configuration 3 activated" 3 "Configuration 4 activated";
VAL_ 1102 AutoFrontWiperActivationStatus 0 "Auto Front wiper de-activation requested" 1 "Auto Front wiper activation requested" 2 "Not used" 3 "Not used";
VAL_ 1102 AHL_ActivationState 0 "Not used" 1 "AHL activated" 2 "AHL NOT activated" 3 "Unavailable";
VAL_ 1102 RearWiperStatus 0 "Unavailable" 1 "Rear wiper activation requested" 2 "Rear wiper de-activation requested" 3 "Not used";
VAL_ 1102 MotorwayFlashersNumberStatus 0 "1 flash per CSW mode" 1 "3 flash per CSW mode" 2 "5 flash per CSW mode" 3 "Not used";
VAL_ 1102 AutoUnLockActivationState 0 "Auto UnLock is not activated" 1 "Auto UnLock with IGN OFF is activated" 2 "Auto UnLock with Park is activated" 3 "Not used";
VAL_ 1102 AmbientLightingPatternState 0 "Activated" 1 "Deactivated";
VAL_ 1102 AutoFMHactivationState 0 "Activated" 1 "Deactivated";
VAL_ 1102 AutoInternalLightingState 0 "Deactivation" 1 "Activation";
VAL_ 1102 AutoFMHdurationState 0 "30 sec" 1 "45 sec" 2 "60 sec" 3 "90 sec" 4 "120 sec" 5 "150 sec" 6 "180 sec" 7 "Not used";
VAL_ 1102 ADB_ActivationState 0 "Activated" 1 "Deactivated";
VAL_ 1102 AutoReLockActivationState 0 "Auto ReLock OFF" 1 "Auto ReLock ON";
VAL_ 1102 FrontRearWiperDropStatus 0 "Wiper Drop Deactivated" 1 "Wiper Drop Activated";
VAL_ 1102 WGSactivationState 0 "Activated" 1 "Deactivated";
VAL_ 1102 LowBeamDisplay 0 "low beam display not requested" 1 "low beam display requested";
VAL_ 1102 HighBeamDisplay 0 "High beam display not requested" 1 "High beam display requested";
VAL_ 1102 AmbientLightingArea5Status 0 "AmbientLighting Area 5 Deactivated" 1 "AmbientLighting Area 5 Activated";
VAL_ 1102 AmbientLightingArea4Status 0 "AmbientLighting Area 4 Activated" 1 "AmbientLighting Area 4 Deactivated";
VAL_ 1102 SupportKeyJudgement 0 "Unavailable value" 1 "Normal key" 2 "Support key" 3 "not used";
VAL_ 1103 AHL_ActivationDisplay 0 "Not used" 1 "AHL activated" 2 "AHL NOT activated" 3 "Unavailable";
VAL_ 1103 FollowMeHomeDurationDisplay 0 "No Follow me home duration Display" 1 "Follow me home duration : 30s" 2 "Follow me home duration : 60s" 3 "Follow me home duration : 90s" 4 "Follow me home duration : 120s" 5 "Not Used" 6 "Not Used" 7 "Not Used";
VAL_ 1103 KeylessInfoReemissionRequest 0 "No display request" 1 "Smart keyless info display reemission";
VAL_ 1103 KeyReminderAlert 0 "Unavailable" 1 "No alert request" 2 "Key reminder alert display requested" 3 "Not used";
VAL_ 1103 FrontRightDoorOpenWarning 0 "No front right door open warning" 1 "front right door open warning - level 1(vehicle stopped)" 2 "front right door open warning - level 2 (vehicle running)" 3 "not used";
VAL_ 1103 FrontLeftDoorOpenWarning 0 "No front left door open warning" 1 "Front left door open warning - level 1(vehicle stopped)" 2 "Front left door open warning - level 2 (vehicle running)" 3 "not used";
VAL_ 1103 PositionLightsDisplay 0 "position lights display not requested" 1 "position lights display requested";
VAL_ 1103 BootOpenWarning 0 "No boot open warning" 1 "boot open warning - level 1(vehicle stopped)" 2 "boot open warning - level 2 (vehicle running)" 3 "not used";
VAL_ 1103 DoorLockRefuseToLockAlertDisplay 0 "No alert request" 1 "Alert request";
VAL_ 1103 IGN_SaverWarningBeforeIGNOFF 0 "No Alert" 1 "Alert before IGN OFF";
VAL_ 1103 STCUT_RLY_FailureAlert 0 "Alert OFF" 1 "Alert ON";
VAL_ 1103 RearRightDoorOpenWarning 0 "No rear right door open warning" 1 "rear right door open warning - level 1(vehicle stopped)" 2 "rear right door open warning - level 2 (vehicle running)" 3 "not used";
VAL_ 1103 RearLeftDoorOpenWarning 0 "No rear left door open warning" 1 "rear left door open warning - level 1(vehicle stopped)" 2 "rear left door open warning - level 2 (vehicle running)" 3 "not used";
VAL_ 1103 AllWeather_Display 0 "All weather display is not requested" 1 "All weather display is requested" 2 "Not used" 3 "Unavailable";
VAL_ 1103 BCM_SteeringUpCommand 0 "button released" 1 "button pressed";
VAL_ 1103 BCM_SteeringPushToTalkCommand 0 "button released" 1 "button pressed";
VAL_ 1103 BCM_SteeringPhoneCommand 0 "button released" 1 "button pressed";
VAL_ 1103 WashingInProgressDisplay 0 "Not Display" 1 "Display";
VAL_ 1103 GlasshatchOpenWarning 0 "No Request" 1 "Glasshatch Opened Alert Request level 1" 2 "Glasshatch Opened Alert Request level 2" 3 "Not used";
VAL_ 1103 BCM_SteeringDownCommand 0 "button released" 1 "button pressed";
VAL_ 1103 BCM_SteeringCommandF 0 "button released" 1 "button pressed";
VAL_ 1103 BCM_SteeringCommandE 0 "button released" 1 "button pressed";
VAL_ 1103 BCM_SteeringCommandD 0 "button released" 1 "button pressed";
VAL_ 1103 BCM_SteeringCommandC 0 "button released" 1 "button pressed";
VAL_ 1103 BCM_SteeringCommandB 0 "button released" 1 "button pressed";
VAL_ 1103 BCM_SteeringCommandA 0 "button released" 1 "button pressed";
VAL_ 1103 BCM_MMISteeringSwitchesFailure 0 "No MMI steering switches failure" 1 "MMI steering switches failure";
VAL_ 1103 AccessModeState 0 "Standard mode" 1 "Secure mode";
VAL_ 1103 LoadingAreaLocked_Display 0 "No display request" 1 "Loading Area is Not Locked Display Request" 2 "Loading Area is Locked Display Request" 3 "Not used";
VAL_ 1103 CockpitLocked_Display 0 "No display" 1 "Not Locked" 2 "Locked" 3 "Not used";
VAL_ 1103 AutomaticLockUpActivationState_2 0 "No feedback" 1 "Lock with Speed - Activation feedback request" 2 "Lock with Speed - Desactivation feedback request" 3 "Not Used";
VAL_ 1103 ExtLightCheck_Result_display 0 "No display" 1 "Canceled" 2 "Aborted" 3 "Completed" 4 "Reserved" 5 "Reserved" 6 "Reserved" 7 "Reserved";
VAL_ 1103 DRLoffMode_Status 0 "Not Active_DRL ON" 1 "Active_DRL always OFF" 2 "Not used" 3 "Unavailable";
VAL_ 1103 TrailerLightCheck_Status 0 "Operation not allowed" 1 "Operation allowed" 2 "Runing" 3 "Unavailable";
VAL_ 1104 ExternalTempDisplayUnit 0 "display mode in °C" 1 "display mode in °F";
VAL_ 1104 DimmingState 0 "Not used" 1 "Step 1" 2 "Step 2" 3 "Step 3" 4 "Step 4" 5 "Step 5" 6 "Step 6" 7 "Step 7" 8 "Step 8" 9 "Step 9" 10 "Step 10" 11 "Step 11" 12 "Step 12" 13 "Step 13" 14 "Step 14" 15 "Step 15" 16 "Step 16" 17 "Step 17" 18 "Step 18" 19 "Step 19" 20 "Step 20" 21 "Step 21" 22 "Not used" 23 "Not used" 24 "Not used" 25 "Not used" 26 "Not used" 27 "Not used" 28 "Not used" 29 "Not used" 30 "Not used" 31 "Not used";
VAL_ 1104 SteeringPushToTalkCommand 0 "Button released" 1 "Button pressed";
VAL_ 1104 SteeringPhoneCommand 0 "Button released" 1 "Button pressed";
VAL_ 1104 UnitDistanceDisplayState 0 "displayed unit in km" 1 "displayed unit in mph";
VAL_ 1104 OilChangeCounterReset 0 "No request" 1 "Oil change counter reset";
VAL_ 1104 Meter_ADACresetRequest 0 "Reset  METER not requested" 1 "Reset  METER requested";
VAL_ 1104 ManualDPFregenerationRequest 0 "No request" 1 "Regeneration request";
VAL_ 1104 DiagnosedFuelLow 0 "Unavailable" 1 "Not empty" 2 "Empty" 3 "Not used";
VAL_ 1104 MuteRadioOrder 0 "No mute radio order" 1 "Mute radio order";
VAL_ 1104 WelcomeSequenceStatus 0 "Unavailable" 1 "Sequence not Started" 2 "Sequence in progress" 3 "Sequence Done";
VAL_ 1104 FillerCapIndicatorResetStatus 0 "No reset" 1 "Reset";
VAL_ 1104 DisplayedOilLevel 0 "warning" 1 "1 bargraph element displayed" 2 "2 bargraph element displayed" 3 "3 bargraph element displayed" 4 "4 bargraph element displayed" 5 "5 bargraph element displayed" 6 "6 bargraph element displayed" 7 "7 bargraph element displayed" 8 "8 bargraph element displayed" 9 "Not used" 10 "Not used" 11 "Not used" 12 "Not used" 13 "Not used" 14 "Not used" 15 "not available";
VAL_ 1104 MeterVolumeState 0 "Unavailable" 1 "Volume 1" 2 "Volume 2" 3 "Volume 3";
VAL_ 1104 FuelLevelDisplayed 0 "petrol tank reserve";
VAL_ 1104 DayNightForMeterDisplay 0 "Day" 1 "Twilight" 2 "Not used" 3 "Night";
VAL_ 1104 SteeringFavoriteCommand 0 "Favorite button released" 1 "Favorite button pushed";
VAL_ 1104 DRLoffMode_Request 0 "No request" 1 "Not Active_DRL ON" 2 "Active_DRL always OFF" 3 "Reset request";
VAL_ 1104 TrailerLightCheck_Request 0 "No request" 1 "Trailler Light Check OFF request" 2 "Trailler Light Check ON request" 3 "Reset request";
VAL_ 1104 SteeringMultiModeCommand 0 "Multi mode button released" 1 "Multi mode button pushed";
VAL_ 1104 SwitchIlluminationReq 0 "Illumination OFF" 1 "Illumination ON";
VAL_ 1104 MeterDisplayActivation 0 "OFF" 1 "Meter ON" 2 "IVI ON" 3 "Meter and IVI ON";
VAL_ 1105 TPW_ResetDriverRequest 0 "Unavailable" 1 "TPW Reset driver NOT requested" 2 "TPW Reset driver requested" 3 "Not used";
VAL_ 1105 TPMS_ResetDriverRequest 0 "Unvailable Value" 1 "TPMS Reset driver NOT requested " 2 "TPMS Reset driver requested " 3 "Not Used";
VAL_ 1105 DisplayedSpeedUnit 0 "Speed Unit in kmph" 1 "Speed Unit in mph";
VAL_ 1105 GlobalVehicleWarningState 0 "No global  vehicle  Fault" 1 "SERV is ON (alert type R3)" 2 "STOP is ON (alert type D3)" 3 "SERV and STOP are ON (alert type R3& D3)";
VAL_ 1105 DayNightForBacklights 0 "Day" 1 "Twilight" 2 "Night" 3 "Unavailable";
VAL_ 1105 ParkingBrakeStatus 0 "Not used" 1 "Automatic or manual Parking brake not applied" 2 "Automatic or manual Parking brake applied" 3 "Unavailable";
VAL_ 1105 PeriodicReverseBuzzerTrigger 0 "No request" 1 "Reverse alert trigger";
VAL_ 1105 LowBrakeFluidLevelStatus 0 "Unavailable" 1 "No brake system malfunction" 2 "Brake system malfunction" 3 "Not used";
VAL_ 1105 MeterResetRequest_PWTstart 0 "No request" 1 "Reset Meter request";
VAL_ 1105 AirSusp_ActivationRequest 0 "Not Request" 1 "AirSUSP System OFF" 2 "AirSUSP System ON" 3 "Reset Request (Reset to Factory Default)";
VAL_ 1105 METER_Status 0 "Not ready" 1 "Available" 2 "Not Available" 3 "Display Failure" 4 "Sound Failure" 5 "Control Failure" 6 "Failure" 7 "Not Used";
VAL_ 1105 METER_CAN_CorruptionDetection 0 "Not Ready" 1 "No Failure" 2 "Temporary Failure" 3 "Permanent Failure";
VAL_ 1105 MeterResetRequest_Refuel 0 "No request" 1 "Reset Meter requested";
VAL_ 1106 AutoDimmingState 0 "AutoDimming Not activated" 1 "AutoDimming activated";
VAL_ 1106 DayNightStatusForB_Switches 0 "Conditionned backlight" 1 "Permanent backlight";
VAL_ 1106 Cluster_Refuse_to_Sleep 0 "reserved" 1 "Cluster refuse to sleep " 2 "Cluster ready to sleep" 3 "reserved";
VAL_ 1106 AutoDimmingOffsetY0 0 "Unavailable" 1 "Step 1" 2 "Step 2" 3 "Step 3" 4 "Step 4" 5 "Step 5" 6 "Step 6" 7 "Step 7" 8 "Step 8" 9 "Step 9" 10 "Step 10" 11 "Step 11" 12 "Step 12" 13 "Step 13" 14 "Step 14" 15 "Step 15";
VAL_ 1107 BattWarnReq_Level_Hi_USM_v2 0 "Not used" 1 "No Alert" 2 "Alert" 3 "Unavailable value";
VAL_ 1107 IgnitionSupplyConfirmation 0 "no primary ignition supply" 1 "primary ignition supply on";
VAL_ 1107 StarterStatus 0 "cranking relay switched off" 1 "short relaxation active" 2 "long relaxation active" 3 "cranking relay switched on";
VAL_ 1107 EEM_StaticPowerLimitationRequest 0 "No Request" 1 "Life on Board Low SOC power limitation" 2 "Delivery Mode power limitation" 3 "Battery Disconnection power limitation" 4 "Producer failure power limitation" 5 "Not used" 6 "Not used" 7 "Not used";
VAL_ 1108 HandDrivingActivationState 0 "Right Hand Driving activated" 1 "Left Hand Driving activated";
VAL_ 1108 LowBatteryVoltageDisplay 0 "No display request" 1 "Battery weak" 2 "Battery weak : start engine" 3 "Battery in charge";
VAL_ 1108 AFS_ActivationState 0 "AFS activated" 1 "AFS deactivated";
VAL_ 1108 LowBeamFailureDisplay_v3 0 "No Low Beam Failure" 1 "Low Beam Failure" 2 "Not used" 3 "Low Beam Failure re-emission";
VAL_ 1108 BattWarnReq_Level_Lo_USM 0 "No Request" 1 "Request";
VAL_ 1108 STRLY_FailureAlert 0 "Alert OFF" 1 "Alert ON";
VAL_ 1108 GenMode_v2 0 "GENMODE0 Limitation requested by Engine" 1 "GENMODE1 Nominal strategy Mode" 2 "GENMODE2 ESM intermediate Mode" 3 "GENMODE3 Battery protection" 4 "GENMODE4 ESM Discharge Mode" 5 "GENMODE5 ESM Regeneration Mode" 6 "GENMODE7 ESM inhibited by actuator" 7 "GENMODE9 MinimumVoltageByECM";
VAL_ 1108 ManualLevellingPositionDisplay 0 "Not display" 1 "Leveling display request";
VAL_ 1108 Storage12V_SwitchRequest 0 "Disconnection request" 1 "Connection request";
VAL_ 1109 HDC_StatusDisplay 0 "HDC Not activated" 1 "HDC Activated" 2 "HDC in Control" 3 "HDC Failure";
VAL_ 1109 EBAfailureDisplayAlert 0 "No Failure" 1 "Failure";
VAL_ 1109 BrakingSystemStateDisplayRequest 0 "No failure" 1 "Failure";
VAL_ 1109 EBDstateDisplayRequest 0 "No failure" 1 "Failure";
VAL_ 1109 CRBSfailureDisplayAlert 0 "No Failure" 1 "Failure";
VAL_ 1109 ABSstateDisplayRequest 0 "No failure" 1 "Failure" 2 "In ext diag session" 3 "To be calibrated";
VAL_ 1109 VDCstateDisplayRequest 0 "No failure and no control" 1 "Failure" 2 "In active control" 3 "Not used";
VAL_ 1109 HSAstateDisplayRequest 0 "No failure" 1 "Failure";
VAL_ 1109 HSA_StatusDisplay 0 "No display" 1 "Not activated" 2 "Ready" 3 "Activated";
VAL_ 1109 TPW_AcknowledgeResetDriver 0 "Waiting" 1 "Reset fail" 2 "Reset ack" 3 "TPW not activ";
VAL_ 1109 VDCdeactivationDisplayRequest 0 "No request" 1 "VDC deactivated display request";
VAL_ 1109 VDCactivationState 0 "VDC function activated" 1 "VDC function deactivated";
VAL_ 1109 TPW_TireCheckReminder 0 "No tire check reminder" 1 "Tire check reminder";
VAL_ 1109 TPW_Status 0 "System OK" 1 "Tyre under inflated" 2 "Failure" 3 "TPW not operational";
VAL_ 1109 MCB_FailureDisplay 0 "no display" 1 "request display";
VAL_ 1109 MiniBrakeFluidLevelAlertDisp 0 "No alert" 1 "Alert Mini brake fluid level";
VAL_ 1109 LowVacPWT_RestartImpossibleAlert 0 "Engine restart impossible alert not requested" 1 "Engine restart impossible alert requested";
VAL_ 1110 BMS12V_DisconnectionDetection 0 "Connected or switch opened" 1 "Disconnected with switch closed";
VAL_ 1110 BMS12V_RefuseToSleep 0 "reserved" 1 "BMS12V refuse to sleep" 2 "BMS12V ready to sleep" 3 "reserved";
VAL_ 1110 BMS12V_SwitchState 0 "Opened" 1 "Closed";
VAL_ 1110 BMS12V_StorageFailure 0 "Limit mode" 1 "Failure mode" 2 "Nominal mode" 3 "Not used";
VAL_ 1116 SSAactivationState 0 "Deactivated" 1 "UpHill activated" 2 "All activated" 3 "Not used";
VAL_ 1116 SSA_StateLamp 0 "No display" 1 "SSA Lamp STANDBY" 2 "SSA Lamp ON (HOLD)" 3 "Not used";
VAL_ 1116 IDM_FailureDisplay 0 "No failure display" 1 "IDM failure";
VAL_ 1116 GCC_IntendedVehicleMoment 0 "No display" 1 "Left external" 2 "Right external" 3 "Left internal" 4 "Right internal" 5 "Not Used" 6 "Not Used" 7 "Not Used";
VAL_ 1116 GCC_ActualVehicleMoment 0 "No display" 1 "Straight run" 2 "Turning left" 3 "Turning right";
VAL_ 1116 NotImmobilizedVehicleWarning_IDM 0 "No warning Vehicle not immobilized display request" 1 "Warning Vehicle not immobilized display request";
VAL_ 1116 ASAactivationState 0 "Activated" 1 "Deactivated";
VAL_ 1116 ADA1ActivationState 0 "Activated" 1 "Deactivated";
VAL_ 1116 GCC_WheelBrake_FR 0 "Deactivated" 1 "Activated";
VAL_ 1116 GCC_WheelBrake_FL 0 "Deactivated" 1 "Activated";
VAL_ 1116 GCC_WheelBrake_RR 0 "Deactivated" 1 "Activated";
VAL_ 1116 GCC_WheelBrake_RL 0 "Deactivated" 1 "Activated";
VAL_ 1119 BattWarnReq_Level_Hi_ECM_v2 0 "Unavailable" 1 "No alert" 2 "Alert" 3 "Not used";
VAL_ 1119 BattWarnReq_Level_Lo_ECM 0 "No Request" 1 "Request";
VAL_ 1120 ETS_ModeLamp_v2_ICE 0 "No Display" 1 "LOCK" 2 "2WD" 3 "4Lo (SNOW)" 4 "While shifting H-L 1" 5 "While shifting H-L 2" 6 "AUTO" 7 "AWD overheating";
VAL_ 1120 RST_CC_ACC_DeactWarning 0 "No display request" 1 "CC desactivation warning by RS conditions" 2 "ACC desactivation warning by RS conditions" 3 "Not used";
VAL_ 1120 RST_CC_ACC_UnavailableRequest 0 "No display request" 1 "CC unavailable" 2 "ACC unavailable" 3 "Not used";
VAL_ 1123 RefuelingStatus 0 "No refueling" 1 "Refueling in progress";
VAL_ 1135 WelcomeFunctionAvailability 0 "Not ready" 1 "Sound available" 2 "Video available" 3 "Video and sound available";
VAL_ 1135 PushToTalkActivationDisplay 0 "No PTT activation" 1 "PTT activation : start to speak request";
VAL_ 1135 BluetoothConnectionDisplayStatus 0 "Not connected" 1 "Connection ongoing" 2 "Connected" 3 "Not Used";
VAL_ 1136 EngineControlFailureLevel2 0 "no Engine Control Failure Level 2 create by stoping the engine" 1 "Engine Control Failure Level 2 create by stoping the engine";
VAL_ 1136 EngineControlFailureLevel1 0 "no Engine Control Failure Level 1" 1 "Engine Control Failure Level 1";
VAL_ 1136 DSICoachingDisplay 0 "No Display" 1 "Acceleration warning display" 2 "Anticipation warning display" 3 "GSI respect warning display";
VAL_ 1137 ShiftIndicator 0 "No display request (no freeshift function or not equipped)" 1 "UpShift display resques" 2 "DownShift display request " 3 "No Shift change display Request (by freeshift function";
VAL_ 1137 RequestedSpeedDisplayRequest 254 "CC/SL off or awaiting for a speed selection" 255 "CC/SL failure";
VAL_ 1137 GSITargettedGearDisplayRequest 0 "Unavailable value" 1 "1" 2 "2" 3 "3" 4 "4" 5 "5" 6 "6" 7 "7" 8 "8" 9 "9" 10 "10" 11 "11" 12 "12" 13 "13" 14 "14" 15 "No shift";
VAL_ 1137 CruiseControlStatus 0 "Cruise Control (CC) and Speed Limit (SL) OFF" 1 "SL active" 2 "SL on and (awaiting or suspended)" 3 "SL requested and in failure" 4 "CC active" 5 "CC ON and ( awaiting  or suspended)" 6 "CC requested and in failure" 7 "Vehicle not equipped with CC/SL / Not available";
VAL_ 1137 EcoDriveIndicatorDisplay 0 "OFF status" 1 "ON status";
VAL_ 1137 CruiseControlStatusRER 0 "No request" 1 "Reemission request";
VAL_ 1138 SailingActivationIdleStatus 0 "Deactivated" 1 "Activated";
VAL_ 1138 PredictiveShiftActivationState 0 "Unavailable" 1 "Activated" 2 "Deactivated" 3 "Not used";
VAL_ 1138 SailingStopActivationState 0 "Activated" 1 "Deactivated";
VAL_ 1138 FillerCapIndicatorONRequest 0 "Fuel fill cap indicator turn off" 1 "Fuel fill cap indicator turn on";
VAL_ 1138 OverspeedIndicationDisplayReq 0 "No CC/SL over speed indication display requested" 1 "CC/SL over speed indication display requested";
VAL_ 1138 CruiseEcoActivationState 0 "Unavailable" 1 "ECO activated" 2 "ECO deactivated" 3 "Not used";
VAL_ 1138 SailingIdleDisplay 0 "No display" 1 "Sailing idle OFF" 2 "Sailing idle ON" 3 "Sailing idle in progress";
VAL_ 1138 StopStartInformationDisplay 0 "No display" 1 "Stop inhibition - Vehicle malfunction" 2 "Stop inhibition - Slope" 3 "Stop inhibition - Vehicle" 4 "Stop inhibition - EEM" 5 "Stop inhibition - Engine" 6 "Stop inhibition - Braking" 7 "Stop inhibition - Hood" 8 "Stop inhibition - Door" 9 "Stop inhibition - Seatbelt" 10 "Stop inhibition - Maneuver" 11 "Stop inhibition - Air conditionning" 12 "Stop inhibition - Steering" 13 "Stop inhibition - i-key not detected" 14 "Stop inhibition - Others" 15 "Not used" 16 "Not used" 17 "Forced restart - Vehicle malfunction" 18 "Not used" 19 "Not used" 20 "Forced restart - EEM" 21 "Forced restart - Engine" 22 "Forced restart - Braking" 23 "Not used" 24 "Forced restart - Door" 25 "Forced restart - Seatbelt" 26 "Forced restart - Maneuver" 27 "Forced restart - Air conditionning" 28 "Forced restart - Steering" 29 "Forced restart - i-key not detected" 30 "Forced restart - Others" 31 "Impossible restart" 32 "Stop &Start failure" 33 "Stop Auto" 34 "Driving tip - Release clutch" 35 "Driving tip - Press brake" 36 "Stop&Start deactivated" 37 "Stop &Start activated" 38 "Not used" 39 "Not used" 40 "Not used" 41 "Not used" 42 "xEV Hood Open Alert" 43 "xEV Seatbelt Not Fastened" 44 "xEV Driver Exit Alert level 1" 45 "xEV Driver Exit Alert level 2" 46 "Driver exit alert" 47 "Hood open alert" 48 "Not used" 49 "Not used" 50 "Not used" 51 "Not used" 52 "Not used" 53 "Not used" 54 "Not used" 55 "Not used" 56 "Not used" 57 "Not used" 58 "Not used" 59 "Not used" 60 "Not used" 61 "Not used" 62 "Not used" 63 "Not used";
VAL_ 1138 OverSpeedAlert_SL 0 "No involuntary SL over speed warning requested" 1 "Involuntary SL over speed warning requested";
VAL_ 1140 LKA_AlertStatus 0 "No alert" 1 "Right alert" 2 "Left alert" 3 "Not used";
VAL_ 1140 TSR_CameraCancelReason 0 "No display" 1 "Front Camera is blocked" 2 "Front Camera is overheat  (High Temperature)" 3 "Camera permanent failure" 4 "Reserved" 5 "Not used" 6 "Not used" 7 "Not used";
VAL_ 1140 LKA_SWheelTakeOverAlert_v3 0 "No Alert" 1 "Alert Lvl 1" 2 "Alert Lvl 2" 3 "Alert Lvl 3" 4 "Alert Lvl 4" 5 "Alert Lvl 5" 6 "Not used" 7 "Not used";
VAL_ 1140 AEB_CameraCancelReason 0 "No display" 1 "Front Camera is blocked" 2 "Front Camera is overheat  (HighTemperature)" 3 "Camera permanent failure" 4 "Reserved" 5 "Not used" 6 "Not used" 7 "Not used";
VAL_ 1140 AEB_RadarCancelReason 0 "No display" 1 "Radar Blocked Display" 2 "Radar radio disturbance" 3 "Radar permanent failure";
VAL_ 1140 DCA_AlertRequest 0 "No alert" 1 "Alert 1 request" 2 "Alert 2 request" 3 "Not used";
VAL_ 1140 DCA_ActivationState 0 "Activated" 1 "Deactivated";
VAL_ 1143 RESstatus 0 "Unavailable" 1 "Reserved for safety" 2 "Reserved for safety" 3 "Normal engine start only" 4 "Reserved for safety" 5 "Reserved for safety" 6 "wait for RES / Presoak" 7 "Reserved for safety" 8 "Reserved for safety" 9 "Customer Starting" 10 "Reserved for safety" 11 "Reserved for safety" 12 "Remote Engine Start" 13 "Reserved for safety" 14 "Reserved for safety" 15 "Vehicle without RES";
VAL_ 1143 RearRightDoorState 0 "Unavailable Value" 1 "Rear Right door closed" 2 "Rear Right door open" 3 "Not Used";
VAL_ 1143 ChildproofLockMalfunctionDisplay 0 "No Childproof lock malfunction warning message" 1 "Childproof lock malfunction message" 2 "Not used" 3 "Warning re-emission requested";
VAL_ 1143 BrakeSwitchFaillure_V2 0 "Not used" 1 "No failure on brake contacts" 2 "Failure on one or two brake contacts" 3 "Unavailable";
VAL_ 1143 StartingMode_BCM 0 "Powertrain Stopped Request" 1 "No request" 2 "Ignition Request" 3 "Starting Request";
VAL_ 1143 ET_kickDetectedAfteriKeyCheck 0 "Kick not detected" 1 "Kick Detected";
VAL_ 1143 TrunkOpeningRequest 0 "Unavailable" 1 "No request" 2 "Trunk opening requested" 3 "Not used";
VAL_ 1143 RearFogLightStateDisplay 0 "rear fog light OFF" 1 "rear fog light ON";
VAL_ 1143 RKE_ButtonPressed 0 "No request" 1 "Not used" 2 "Short Press - Lock" 3 "Short Press - Unlock" 4 "Short Press -  Backdoor or Trunk" 5 "Short Press - Panic" 6 "Short Press - PowerSlidingDoorRH" 7 "Short Press - PowerSlidingDoorLH" 8 "Short Press - Remote Lighting" 9 "Short Press - RES" 10 "Short Press - Roof" 11 "Not used" 12 "Not used" 13 "Not used" 14 "Not used" 15 "Not used" 16 "Released Button - Backdoor or Trunk" 17 "Not used" 18 "Long Press - Lock" 19 "Long Press - Unlock" 20 "Long Press - Backdoor or Trunk" 21 "Long Press - Panic" 22 "Long Press - PowerSlidingDoorRH" 23 "Long Press - PowerSlidingDoorLH" 24 "Long Press - Remote Lighting" 25 "Long Press - RES" 26 "Long Press - Roof" 27 "Very Long - Lock & Unlock" 28 "Not used" 29 "Not used" 30 "Not used" 31 "Unavailable";
VAL_ 1143 DriverDoorState 0 "Unavailable Value" 1 "Driver door closed" 2 "Driver door open" 3 "Not Used";
VAL_ 1143 PassengerDoorState 0 "Unavailable Value" 1 "Passenger door closed" 2 "Passenger door open" 3 "Not used";
VAL_ 1143 RearLeftDoorState 0 "Unavailable Value" 1 "Rear left door closed" 2 "Rear left door open" 3 "Not Used";
VAL_ 1144 WakeUpType 0 "Full Wake-Up Mode" 1 "Selective Wake-Up Mode 1" 2 "Selective Wake-Up Mode 2" 3 "Selective Wake-Up Mode 3" 4 "Selective Wake-Up Mode 4" 5 "Selective Wake-Up Mode 5" 6 "Selective Wake-Up Mode 6" 7 "Unavailable";
VAL_ 1144 SmartKeylessInformationDisplay 0 "No Display Request" 1 "Brake Pedal and Start Requested" 2 "Declutch and start requested" 3 "Kazashi - Card not detected" 4 "Kazashi separated - Card not detected" 5 "Turn Wheel + Start" 6 "MT gear level on neutral position requested" 7 "AT gear lever on Park requested" 8 "AT gear lever on neutral position requested" 9 "Push" 10 "Engine Running - Card not detected" 11 "Confirm engine Stop on Card not detected" 12 "Confirm engine Stop at Vehicle Speed Unavailable" 13 "Not Used" 14 "Permanent Ignition Alert" 15 "Keylock alert" 16 "Confirm engine stop warning on disconnected 12V battery" 17 "Kazashi authentication succeed" 18 "Emergency engine stop" 19 "Do long press to start" 20 "Keep pedal pressed to start" 21 "Declutch" 22 "FOTA Activation Software" 23 "Not Used" 24 "Not Used" 25 "Not Used" 26 "Not Used" 27 "Not Used" 28 "Not Used" 29 "Not Used" 30 "Not Used" 31 "Not Used";
VAL_ 1144 DriverDoorLockedStatus 0 "Driver Door Unlocked" 1 "Driver Door Locked";
VAL_ 1144 VehicleOutsideLockedState 0 "Vehicle not locked from the outside by the customer" 1 "Vehicle Locked from the outside by the customer";
VAL_ 1144 DriverOutsideBuzzerRequest 0 "No Request" 1 "1 beep" 2 "2 beeps" 3 "Lock by WAC" 4 "Trunk opening" 5 "Refuse to Lock" 6 "Lock out Prevention Doors" 7 "Lock out Prevention Trunk" 8 "Buzzer Request by CIDMOWER" 9 "Buzzer Request by Keylock" 10 "Car Finder is requested" 11 "Not used" 12 "Not used" 13 "Not used" 14 "Not used" 15 "Not used";
VAL_ 1144 FrontFogLightsDisplay 0 "front fog lights display not requested" 1 "front fog lights display requested";
VAL_ 1144 BrakeLampStatus 0 "Brake Lamp Off" 1 "Brake Lamp On";
VAL_ 1145 SingleDoorOpeningActivationState 0 "Single door opening activated" 1 "Single door opening deactivated";
VAL_ 1145 PositionLightsOmissionWarning 0 "No position lights omission warning resquested" 1 "Position lights omission warning requested" 2 "not used" 3 "Warning re-emission requested";
VAL_ 1145 AHL_FailureDisplay_v2 0 "AHL NO Display Failure" 1 "AHL Display Failure";
VAL_ 1145 ProbableCustomerFeedBackNeed 0 "Customer feedback probably not needed" 1 "Customer feedback needed";
VAL_ 1145 DayNightSynthesis 0 "Day" 1 "Twilight" 2 "Night" 3 "Not used";
VAL_ 1145 AutoFoldingActivationState 0 "Unavailable" 1 "Disable" 2 "IGN Unfold" 3 "Unlock + IGN Unfold";
VAL_ 1145 AutoACC2Status_MM 0 "Multimedia is done" 1 "Multimedia can receive / send messages" 2 "Multimedia can detect manual operation" 3 "Multimedia can work for all functions";
VAL_ 1145 IGN_SaverWarningAfterIGNOFF 0 "No Alert" 1 "Alert after IGN OFF";
VAL_ 1145 RearRightDoorLockedStatus 0 "Rear Right Door is Unlocked" 1 "Rear Right Door is Locked";
VAL_ 1145 RearLeftDoorLockedStatus 0 "Rear Left Door is Unlocked" 1 "Rear Left Door is Locked";
VAL_ 1145 PassengerDoorLockedStatus 0 "Passenger Door is Unlocked" 1 "Passenger Door is Locked";
VAL_ 1146 DriverSafetyBeltBuckleState 0 "SB Not monitored" 1 "SB unfastened" 2 "SB fastened" 3 "Unavailable";
VAL_ 1146 VehicleStates 0 "Sleeping" 1 "Not used" 2 "CutoffPending" 3 "AutoACC  - BatTempoLevel" 4 "Not used" 5 "IgnitionLevel" 6 "StartingInProgress" 7 "PowertrainRunning" 8 "AutoStart" 9 "EngineSystemStop" 10 "Not used" 11 "Not used" 12 "Not used" 13 "Not used" 14 "Not used" 15 "Unavailable";
VAL_ 1146 BrakeInfoStatus 0 "Not used" 1 "Brake pedal not pressed" 2 "Brake pedal pressed" 3 "Not used" 4 "Brake pedal confirmed pressed" 5 "Not used" 6 "Not used" 7 "unavailable";
VAL_ 1146 DeliveryModeInformation_v2 0 "customer mode" 1 "delivery mode level 1" 2 "delivery mode level 2" 3 "Not used";
VAL_ 1146 GADE_v2 0 "Sleep or Crank fault, Disable DiagMuxDTC" 1 "AutoACC fault, Disable DiagMuxDTC" 2 "ALL fault, Disable DiagMuxDTC" 3 "ALL fault, Enable DiagMuxDTC" 4 "FOTA switch fault, Disable DiagMuxDTC" 5 "Not used" 6 "Not used" 7 "Unavailable";
VAL_ 1147 Maintenance_Mode_Display 0 "Roller bench display not requested" 1 "Roller bench display requested";
VAL_ 1147 OilPressureWarning_ECM 0 "No Oil Pressure Warning" 1 "Oil Pressure Warning";
VAL_ 1147 WarningWaterTemp 0 "no water temperature warning" 1 "water temperature warning";
VAL_ 1147 ECM_WarningMessage5 0 "No Request" 1 "ECM Warning Message5";
VAL_ 1147 ECM_WarningMessage4 0 "No Request" 1 "ECM Warning Message4";
VAL_ 1147 ECM_WarningMessage3 0 "No Request" 1 "ECM Warning Message3";
VAL_ 1147 ECM_WarningMessage2 0 "No Request" 1 "ECM Warning Message2";
VAL_ 1147 ECM_WarningMessage1 0 "No Request" 1 "ECM Warning Message1";
VAL_ 1147 CCSL_CancelReason 0 "No display" 1 "CC Activation refused: CurrentSpeed" 2 "CC Activation refused: RenaultSport Conditions" 3 "CC Activation refused: OtherReason" 4 "CC Permanent failure display" 5 "SL Activation refused: CurrentSpeed" 6 "SL Activation refused: RenaultSport Conditions" 7 "SL Activation refused: OtherReason" 8 "SL Permanent failure display" 9 "Not used" 10 "Not used" 11 "Not used" 12 "Not used" 13 "Not used" 14 "Not used" 15 "Not used";
VAL_ 1147 MILLamp 0 "No test of readiness codes status and Readiness Codes completed and MIL lamp off request" 1 "No test of readiness codes status and Readiness Codes completed and MIL Lamp on request" 2 "No test of readiness codes status and Readiness Codes completed and MIL lamp flash request" 3 "No test of readiness codes status and Readiness Codes completed and MIL lamp auto-test" 4 "No test of readiness codes status and Readiness codes not completed and MIL lamp off request" 5 "No test of readiness codes status and Readiness codes not completed and MIL Lamp on request" 6 "No test of readiness codes status and Readiness codes not completed and MIL lamp flash request" 7 "No test of readiness codes status and Readiness codes not completed and MIL lamp auto-test" 8 "Test of readiness codes status and Readiness Codes completed and MIL lamp off request" 9 "Test of readiness codes status and Readiness Codes completed and MIL Lamp on request" 10 "Test of readiness codes status and Readiness Codes completed and MIL lamp flash request" 11 "Test of readiness codes status and Readiness Codes completed and MIL lamp auto-test" 12 "Test of readiness codes status and Readiness codes not completed and MIL lamp off request" 13 "Test of readiness codes status and Readiness codes not completed and MIL Lamp on request" 14 "Test of readiness codes status and Readiness codes not completed and MIL lamp flash request" 15 "Test of readiness codes status and Readiness codes not completed and MIL lamp auto-test";
VAL_ 1147 Engine_high_oil_level_warning 0 "No high level engine oil warning" 1 "Engine high oil level warning";
VAL_ 1147 CCSL_TransitionStatesDisplay 0 "No display" 1 "CC User Activation OFF to ON Waiting" 2 "CC User Activation OFF to ON WaitingInFailure" 3 "CC User Activation ON Waiting to ON Active" 4 "CC User Activation ON Suspend to ON Active by SETSW" 5 "CC User Activation ON Suspend to ON Active by RESSW" 6 "CC User Deactivation ON Active to ON Suspend" 7 "CC System Deactivation ON Active to ON Suspend w/o risk" 8 "CC System Deactivation: ON Active to OFF with risk for driver" 9 "CC System Deactivation: ON Waiting to ON WaitingInFailure" 10 "CC System Deactivation: ON Active to ON WaitingInFailure" 11 "CC System Deactivation: ON Suspend to ON WaitingInFailure" 12 "SL User Activation OFF to ON Waiting" 13 "SL User Activation OFF to ON WaitingInFailure" 14 "SL User Activation ON Waiting to ON Active" 15 "SL User Activation ON Suspend to ON Active by SETSW" 16 "SL User Activation ON Suspend to ON Active by RESSW" 17 "SL User Deactivation ON Active to ON Suspend" 18 "SL System Deactivation ON Active to ON Suspend w/o risk" 19 "SL System Deactivation: ON Active to OFF with risk for driver" 20 "SL System Deactivation: ON Waiting to ON WaitingInFailure" 21 "SL System Deactivation: ON Active to ON WaitingInFailure" 22 "SL System Deactivation: ON Suspend to ON WaitingInFailure" 23 "Not used" 24 "Not used" 25 "Not used" 26 "Not used" 27 "Not used" 28 "Not used" 29 "Not used" 30 "Not used" 31 "Not used";
VAL_ 1147 CCSL_CancelReasonRER 0 "No ReEmission" 1 "ReEmission request";
VAL_ 1147 ECM_OilPressureSwitchFaultDisp 0 "No oil pressure switch fault warning requested" 1 "Oil pressure switch fault warning requested";
VAL_ 1147 Engine_low_oil_level_warning 0 "No engine oil low level warning" 1 "Engine oil low level warning";
VAL_ 1148 ERDC_R_RefuseToOpenAlertDisplay 0 "No Request" 1 "Request" 2 "Not used" 3 "Unavailable";
VAL_ 1148 ERDC_R_RefuseToOpenAlertDisp_RER 0 "No Request" 1 "Request" 2 "Not used" 3 "Unavailable";
VAL_ 1149 AD_LaneMarker1_1 0 "No Display" 1 "Line lost" 2 "Solid white" 3 "Dashed white" 4 "Solid yellow without caution" 5 "Solid yellow with caution" 6 "Not used" 7 "Not used";
VAL_ 1149 AD_DrivingLaneType 0 "No Display" 1 "Normal lane" 2 "Right merge lane" 3 "Left merge lane";
VAL_ 1149 AD_CurveStatus 0 "Straight" 1 "Right gentle curve" 2 "Right normal curve" 3 "Right tight curve" 4 "Left gentle curve" 5 "Left normal curve" 6 "Left tight curve" 7 "Not used";
VAL_ 1149 AD_LineShort1_2 0 "Long" 1 "Short";
VAL_ 1149 AD_LineShort1_1 0 "Long" 1 "Short";
VAL_ 1149 AD_LaneMarker2_1 0 "No Display" 1 "Line lost" 2 "Solid white" 3 "Dashed white" 4 "Solid yellow without caution" 5 "Solid yellow with caution" 6 "Not used" 7 "Not used";
VAL_ 1149 AD_LaneMarker1_2 0 "No Display" 1 "Line lost" 2 "Solid white" 3 "Dashed white" 4 "Solid yellow without caution" 5 "Solid yellow with caution" 6 "Not used" 7 "Not used";
VAL_ 1149 AD_LineShort2_2 0 "Long" 1 "Short";
VAL_ 1149 AD_LineShort2_1 0 "Long" 1 "Short";
VAL_ 1149 AD_LaneMarker3_1 0 "No Display" 1 "Line lost" 2 "Solid white" 3 "Dashed white" 4 "Solid yellow without caution" 5 "Solid yellow with caution" 6 "Not used" 7 "Not used";
VAL_ 1149 AD_LaneMarker2_2 0 "No Display" 1 "Line lost" 2 "Solid white" 3 "Dashed white" 4 "Solid yellow without caution" 5 "Solid yellow with caution" 6 "Not used" 7 "Not used";
VAL_ 1149 AD_LineShort3_2 0 "Long" 1 "Short";
VAL_ 1149 AD_LineShort3_1 0 "Long" 1 "Short";
VAL_ 1149 AD_LaneMarker4_1 0 "No Display" 1 "Line lost" 2 "Solid white" 3 "Dashed white" 4 "Solid yellow without caution" 5 "Solid yellow with caution" 6 "Not used" 7 "Not used";
VAL_ 1149 AD_LaneMarker3_2 0 "No Display" 1 "Line lost" 2 "Solid white" 3 "Dashed white" 4 "Solid yellow without caution" 5 "Solid yellow with caution" 6 "Not used" 7 "Not used";
VAL_ 1149 ALC_TurnByTurnPriority 0 "No priority" 1 "ALC priority";
VAL_ 1149 AD_LowHighViewState 0 "Low view" 1 "High view";
VAL_ 1149 AD_LineShort4_2 0 "Long" 1 "Short";
VAL_ 1149 AD_LineShort4_1 0 "Long" 1 "Short";
VAL_ 1149 AD_LaneMarker4_2 0 "No Display" 1 "Line lost" 2 "Solid white" 3 "Dashed white" 4 "Solid yellow without caution" 5 "Solid yellow with caution" 6 "Not used" 7 "Not used";
VAL_ 1149 AD2_ALCGapDetection 0 "No Display" 1 "Preferred lane" 2 "1 time Right ALC to preferred lane" 3 "2 time Right ALC to preferred lane" 4 "3 time Right ALC to preferred lane" 5 "4 time Right ALC to preferred lane" 6 "5 time Right ALC to preferred lane" 7 "6 time Right ALC to preferred lane" 8 "7 time Right ALC to preferred lane" 9 "8 time Right ALC to preferred lane" 10 "1 time Left ALC to preferred lane" 11 "2 time Left ALC to preferred lane" 12 "3 time Left ALC to preferred lane" 13 "4 time Left ALC to preferred lane" 14 "5 time Left ALC to preferred lane" 15 "6 time Left ALC to preferred lane" 16 "7 time Left ALC to preferred lane" 17 "8 time Left ALC to preferred lane" 18 "Not used" 19 "Not used" 20 "Not used" 21 "Not used" 22 "Not used" 23 "Not used" 24 "Not used" 25 "Not used" 26 "Not used" 27 "Not used" 28 "Not used" 29 "Not used" 30 "Not used" 31 "Not used";
VAL_ 1149 AD2_CarPoolLaneNotification 0 "No display" 1 "HOV lane on Right" 2 "HOV lane on Center" 3 "HOV lane on Right and Center" 4 "HOV lane on Left" 5 "HOV lane on Left and Right" 6 "HOV lane on Left and Center" 7 "HOV lane on Left and Center and Right";
VAL_ 1149 AD2_HostVehicleLanePosition 0 "No Display" 1 "1st lane" 2 "2nd lane" 3 "3rd lane" 4 "4th lane" 5 "5th lane" 6 "6th lane" 7 "7th lane" 8 "8th lane" 9 "Not used" 10 "Not used" 11 "Not used" 12 "Not used" 13 "Not used" 14 "Not used" 15 "Not used";
VAL_ 1149 AD2_NumOfLane 0 "No Display" 1 "1 lane" 2 "2 lanes" 3 "3 lanes" 4 "4 lanes" 5 "5 lanes" 6 "6 lanes" 7 "7 lanes" 8 "8 lanes" 9 "Not used" 10 "Not used" 11 "Not used" 12 "Not used" 13 "Not used" 14 "Not used" 15 "Not used";
VAL_ 1150 SET_PositionInLane_State 0 "Invalid" 1 "To_hard_shoulder" 2 "Centre" 3 "To_overtake_lane";
VAL_ 1150 SET_VoiceGuidance_State 0 "Invalid" 1 "OFF" 2 "ON" 3 "Not Used";
VAL_ 1150 SET_LaneChangeSwiftness_State 0 "Invalid" 1 "Swift" 2 "Standard" 3 "Comfort";
VAL_ 1150 SET_NavigatDriveAssist_State 0 "Invalid" 1 "OFF" 2 "ON" 3 "Not Used";
VAL_ 1150 SET_OvertakeRelatSpeed_State 0 "Invalid" 1 "Low" 2 "Middle" 3 "High";
VAL_ 1150 SET_OvertakingAssist_State 0 "Invalid" 1 "OFF" 2 "ON" 3 "Not Used";
VAL_ 1150 SET_Acceleration_State 0 "Invalid" 1 "Quick" 2 "Standard" 3 "Gentle";
VAL_ 1150 SET_ALCActivationByTSIG_State 0 "Invalid" 1 "OFF" 2 "ON" 3 "Not Used";
VAL_ 1150 SET_CornerSpeedLevel_State 0 "Invalid" 1 "Quick" 2 "Standard" 3 "Gentle";
VAL_ 1150 SET_Deceleration_State 0 "Invalid" 1 "Quick" 2 "Standard" 3 "Gentle";
VAL_ 1150 RAB_CancelReason_v2 0 "No display" 1 "VDC desactivated by driver" 2 "VDC in regulation" 3 "Active Pedal HighTemp" 4 "SideRadar Blocked" 5 "Side Radar Permanent Failure" 6 "Us Sensor Permanent Failure" 7 "Parking Camera blocked" 8 "Parking Camera Permanent Failure" 9 "Trailer Presence" 10 "sonar blocked" 11 "ADAS ECU Temporary failure" 12 "ADAS ECU Permanent failure" 13 "reserved" 14 "reserved" 15 "reserved";
VAL_ 1150 ADL3_DisclaimerRepetitionRequest 0 "No repetition request" 1 "Repetition request";
VAL_ 1150 CASP_ActivationState 0 "Activated" 1 "Deactivated";
VAL_ 1150 SET_ADL3Activation_State 0 "Invalid" 1 "Activated" 2 "Deactivated" 3 "Not Used";
VAL_ 1150 SET_AD_HandsOff_State 0 "Invalid" 1 "Activated" 2 "Deactivated" 3 "Not Used";
VAL_ 1150 SET_ALC_AssistMode_State 0 "Invalid" 1 "Successive" 2 "Individual" 3 "Not Used";
VAL_ 1150 CASP_Extended_ConvertedSpeedReq 0 "No Diplay Request" 1 "Converted Speed Display Request";
VAL_ 1150 SET_ContextSpdLocal_ActState 0 "Unavailable" 1 "AutoMode OFF" 2 "AutoMode ON" 3 "Prompt mode activated";
VAL_ 1150 AES_ActivationState 0 "Unavailable" 1 "Activated" 2 "De-activated" 3 "Not used";
VAL_ 1152 ERDC_L_RefuseToOpenAlertDisplay 0 "No Request" 1 "Request" 2 "Not used" 3 "Unavailable";
VAL_ 1152 ERDC_L_RefuseToOpenAlertDisp_RER 0 "No Request" 1 "Request" 2 "Not used" 3 "Unavailable";
VAL_ 1161 MBLfailureDisplay 0 "No display" 1 "MBL failure display";
VAL_ 1165 OEMmode_display_request 0 "No display requested" 1 "4WD Dyno mode Display" 2 "FWD Dyno mode Display" 3 "RWD Dyno mode Display" 4 "ICE Forced Dyno mode Display" 5 "Dyno mode Deactivated" 6 "Not Used" 7 "Not Used";
VAL_ 1165 OEMmode_coupling_Alert 0 "No Display requested" 1 "Display requested";
VAL_ 1165 OEMmodeMenuState 0 "No request" 1 "No roller bench mode" 2 "4WD Dyno Mode activated" 3 "FWD Dyno Mode activated" 4 "RWD Dyno Mode activated" 5 "ICE forced dyno mode activated" 6 "OEM Mode 5 activated" 7 "OEM Mode 6 activated" 8 "OEM Mode 7 activated" 9 "OEM Mode 8 activated" 10 "OEM Mode 9 activated" 11 "OEM Mode 10 activated" 12 "OEM Mode 11 activated" 13 "OEM Mode 12 activated" 14 "OEM Mode 13 activated" 15 "Unavailable";
VAL_ 1165 StopLampCANfailure_display 0 "no display" 1 "display";
VAL_ 1167 V2X_ICW_Direction 0 "Invalid" 1 "Left" 2 "LeftFront" 3 "Front" 4 "RightFront" 5 "Right" 6 "RightRear" 7 "Rear" 8 "LeftRear" 9 "Not used" 10 "Not used" 11 "Not used" 12 "Not used" 13 "Not used" 14 "Not used" 15 "Not used";
VAL_ 1167 V2X_VRUCW_Direction 0 "Invalid" 1 "Left" 2 "LeftFront" 3 "Front" 4 "RightFront" 5 "Right" 6 "RightRear" 7 "Rear" 8 "LeftRear" 9 "Not used" 10 "Not used" 11 "Not used" 12 "Not used" 13 "Not used" 14 "Not used" 15 "Not used";
VAL_ 1167 V2X_CurrentLaneTurnSign 0 "Invalid" 1 "Straight-Lane" 2 "Left-Lane" 3 "Right-Lane" 4 "U-turn lane" 5 "Not used" 6 "Not used" 7 "Not used";
VAL_ 1167 V2X_GLOSA_WarningState 0 "Unactivated" 1 "Activated";
VAL_ 1167 V2X_GLOSA_GoStraightLightColor 0 "Invalid" 1 "Red Light" 2 "Green Light" 3 "Yellow Light" 4 "Yellow Light Flash" 5 "Not used" 6 "Not used" 7 "Not used";
VAL_ 1167 V2X_InitCompletedFlag 0 "V2X Initialization is not complete" 1 "V2X Initialization is completed";
VAL_ 1176 OSE_AlertStatusLeft 0 "No alert" 1 "Level1" 2 "Level2" 3 "Level3" 4 "Function stop" 5 "Not Used" 6 "Not Used" 7 "Not Used";
VAL_ 1176 ADTutorial_ActivationState 0 "Activated" 1 "Deactivated";
VAL_ 1176 TSRPredictive_ActivationState 0 "Unavailable" 1 "TSR Predictive OFF" 2 "TSR Predictive ON" 3 "Not Used";
VAL_ 1176 OSE_FailureDisplay 0 "No display" 1 "Temporary failure display" 2 "Permanent failure display" 3 "Not Used";
VAL_ 1176 OSE_AlertStatusRight 0 "No alert" 1 "Level1" 2 "Level2" 3 "Level3" 4 "Function stop" 5 "Not Used" 6 "Not Used" 7 "Not Used";
VAL_ 1176 RMF_StatusDisplay 0 "No display" 1 "Warning" 2 "Intervention1" 3 "Intervention2" 4 "Intervention3" 5 "Intervention4" 6 "Not used" 7 "Unavailable";
VAL_ 1176 RMF_StateDisplayRequest 0 "No display" 1 "Warning" 2 "Intervention1" 3 "Intervention2" 4 "Intervention3" 5 "Intervention4" 6 "Intervention Cancelled" 7 "Recovered" 8 "Not used" 9 "Not used" 10 "Not used" 11 "Not used" 12 "Not used" 13 "Not used" 14 "Not used" 15 "Unavailable";
VAL_ 1176 RMF_FailureDisplay 0 "No display" 1 "RMF Failure1" 2 "RMF Failure2" 3 "RMF Failure3" 4 "Not used" 5 "Not used" 6 "Not used" 7 "Unavailable";
VAL_ 1177 DMC_Tempoff_Request 0 "No request" 1 "Stop request ON";
VAL_ 1177 RMF_Tempoff_Request 0 "No request" 1 "Stop request ON";
VAL_ 1177 WiperLinkedALSActivationRequest 0 "No request" 1 "Activation request" 2 "Deactivation request" 3 "Reset request";
VAL_ 1177 OverSpeedWarningSoundMute 0 "No MUTE" 1 "MUTE";
VAL_ 1177 DAA_Tempoff_Request 0 "No request" 1 "Stop request ON";
VAL_ 1179 eHBox_USB_MapInstall_LoadTime 0 "Table Value420480";
VAL_ 1179 eHBox_USBInstall_InsertedState 0 "Unavailable" 1 "Not inserted" 2 "Inserted" 3 "Not used";
VAL_ 1179 eHBox_USB_Save_MapStatus 0 "Unavailable" 1 "Success" 2 "Vehicle information save error" 3 "No space in USB" 4 "USB Device removed" 5 "Not used" 6 "Not used" 7 "Not used";
VAL_ 1179 eHBox_USBSave_InsertedState 0 "Unavailable" 1 "Not inserted" 2 "Inserted" 3 "Not used";
VAL_ 1179 eHBox_USBMapData_Status 0 "No status" 1 "Map of USB is same or older" 2 "Map of USB is incompatible with vehicle" 3 "Map of USB is incompatible with software version" 4 "Map information read error" 5 "Detect newer Map version" 6 "Not Used" 7 "Not Used";
VAL_ 1179 eHBox_USBMapInstall_DispRequest 0 "No Request" 1 "Request";
VAL_ 1179 eHBox_USB_MapdataContainState 0 "Unavailable" 1 "Not contain" 2 "Contain" 3 "Not used";
VAL_ 1179 eHBox_USB_MapInstallState 0 "No status" 1 "Map update is removed USB" 2 "Map update error" 3 "Map update is completed";
VAL_ 1180 AirSUSP_StatusDisplay 0 "No Display" 1 "AirSUSP System OFF" 2 "AirSUSP System ON" 3 "Reserve";
VAL_ 1180 AirSusp_HeightDeflectionDisplay 0 "No Display" 1 "Vehicle height currently too High" 2 "Vehicle height currently too low" 3 "Reserve";
VAL_ 1180 AirSUSP_FailureDisplay 0 "Normal" 1 "Fail Mode";
VAL_ 1180 AirSusp_StrokeLeveDisplay_FL 0 "Not Request" 1 "DISPLAY Level0 (Low/Bound)" 2 "DISPLAY Level1" 3 "DISPLAY Level2" 4 "DISPLAY Level3" 5 "DISPLAY Level4" 6 "DISPLAY Level5" 7 "DISPLAY Level6" 8 "DISPLAY Level7" 9 "DISPLAY Level8" 10 "DISPLAY Level9" 11 "DISPLAY Level10" 12 "DISPLAY Level11" 13 "DISPLAY Level12" 14 "DISPLAY Level13" 15 "DISPLAY Level14 (High/Rebound)";
VAL_ 1180 AirSusp_SuspendReason 0 "No Display (Default)" 1 "Reserve" 2 "Reserve" 3 "Reserve" 4 "Shift P" 5 "Except Shift P" 6 "Door open" 7 "Vehicle overloaded" 8 "Compressor cooling" 9 "Engine hood OPEN" 10 "AirSUSP system disable" 11 "Not used" 12 "Not used" 13 "Not used" 14 "Not used" 15 "Not used";
VAL_ 1180 AirSusp_StrokeLeveDisplay_RL 0 "Not Request" 1 "DISPLAY Level0 (Low/Bound)" 2 "DISPLAY Level1" 3 "DISPLAY Level2" 4 "DISPLAY Level3" 5 "DISPLAY Level4" 6 "DISPLAY Level5" 7 "DISPLAY Level6" 8 "DISPLAY Level7" 9 "DISPLAY Level8" 10 "DISPLAY Level9" 11 "DISPLAY Level10" 12 "DISPLAY Level11" 13 "DISPLAY Level12" 14 "DISPLAY Level13" 15 "DISPLAY Level14 (High/Rebound)";
VAL_ 1180 AirSusp_StrokeLeveDisplay_FR 0 "Not Request" 1 "DISPLAY Level0 (Low/Bound)" 2 "DISPLAY Level1" 3 "DISPLAY Level2" 4 "DISPLAY Level3" 5 "DISPLAY Level4" 6 "DISPLAY Level5" 7 "DISPLAY Level6" 8 "DISPLAY Level7" 9 "DISPLAY Level8" 10 "DISPLAY Level9" 11 "DISPLAY Level10" 12 "DISPLAY Level11" 13 "DISPLAY Level12" 14 "DISPLAY Level13" 15 "DISPLAY Level14 (High/Rebound)";
VAL_ 1180 AirSusp_AutoModeStatus 0 "No Display" 1 "ALL" 2 "KEEP_NORMAL" 3 "HI_LOW" 4 "Only_HI" 5 "Only_LOW" 6 "Reserve" 7 "Reserve";
VAL_ 1180 AirSusp_StrokeLeveDisplay_RR 0 "Not Request" 1 "DISPLAY Level0 (Low/Bound)" 2 "DISPLAY Level1" 3 "DISPLAY Level2" 4 "DISPLAY Level3" 5 "DISPLAY Level4" 6 "DISPLAY Level5" 7 "DISPLAY Level6" 8 "DISPLAY Level7" 9 "DISPLAY Level8" 10 "DISPLAY Level9" 11 "DISPLAY Level10" 12 "DISPLAY Level11" 13 "DISPLAY Level12" 14 "DISPLAY Level13" 15 "DISPLAY Level14 (High/Rebound)";
VAL_ 1181 eHBox_USB_ReadMap_DispRequest 0 "No Request" 1 "Request";
VAL_ 1181 eHBox_LicenseState 0 "Inactive" 1 "Active";
VAL_ 1181 eHBox_MapUpdate_State 0 "No request" 1 "No State" 2 "Start to Save Map" 3 "Not inserted USB_save" 4 "Result of Save Map" 5 "Not inserted USB_install" 6 "Not contain" 7 "Read Map Version" 8 "Select Map Update" 9 "Result of Map Version" 10 "Map Updating" 11 "Result of Map Updating" 12 "Not used" 13 "Not used" 14 "Not used" 15 "Not used";
VAL_ 1181 eHBox_Current_Map_version 0 "Table Value420478";
